VERSION "HNPBNNNYNNNNNNNNNNNNNNNNNNNNNNNNYNYYYYYYYY>4>%%%/4>'%**4YYY///"

NS_ :

BS_:

BU_: TPM TCM SCCM RF_HUB PTS ORC IC HaLF ETM ESM ESC EPS ECM Diagnost DTCM DASM CBC AFLS ADCM

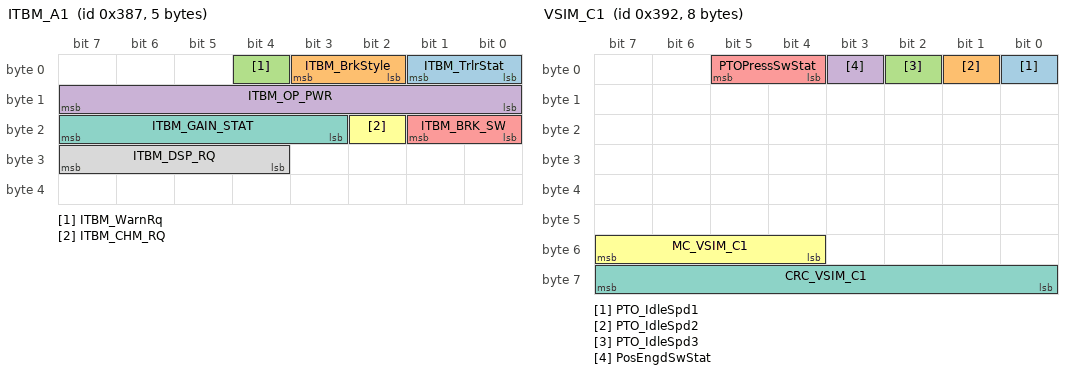
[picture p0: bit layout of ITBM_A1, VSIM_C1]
BO_ 903 ITBM_A1: 5 Vector__XXX
 SG_ ITBM_TrlrStat : 0|2@1+ (1,0) [0|0] ""  PTS,IC,CBC
 SG_ ITBM_BrkStyle : 2|2@1+ (1,0) [0|0] ""  IC,CBC
 SG_ ITBM_WarnRq : 4|1@1+ (1,0) [0|0] ""  IC
 SG_ ITBM_OP_PWR : 8|8@1+ (0.5,0) [0|100] "%"  IC
 SG_ ITBM_BRK_SW : 16|2@1+ (1,0) [0|0] ""  CBC
 SG_ ITBM_CHM_RQ : 18|1@1+ (1,0) [0|0] ""  IC
 SG_ ITBM_GAIN_STAT : 19|5@1+ (0.5,0) [0|10] ""  IC
 SG_ ITBM_DSP_RQ : 28|4@1+ (1,0) [0|0] ""  IC

BO_ 904 TCM_HSC: 8 ECM
 SG_ TCM_HSC : 7|64@0+ (1,0) [0|0] ""  Diagnost

BO_ 912 ECM_APPL5: 8 ECM
 SG_ ECM_APPL5 : 7|64@0+ (1,0) [0|0] ""  Diagnost

BO_ 914 VSIM_C1: 8 Vector__XXX
 SG_ PTO_IdleSpd1 : 0|1@1+ (1,0) [0|0] ""  ECM
 SG_ PTO_IdleSpd2 : 1|1@1+ (1,0) [0|0] ""  ECM
 SG_ PTO_IdleSpd3 : 2|1@1+ (1,0) [0|0] ""  ECM
 SG_ PosEngdSwStat : 3|1@1+ (1,0) [0|0] ""  ECM
 SG_ PTOPressSwStat : 4|2@1+ (1,0) [0|0] ""  ECM,CBC
 SG_ MC_VSIM_C1 : 52|4@1+ (1,0) [0|15] ""  ECM,CBC
 SG_ CRC_VSIM_C1 : 56|8@1+ (1,0) [0|0] ""  ECM,CBC

BO_ 916 VSIM_C2: 6 Vector__XXX
 SG_ STEREO_MD : 0|1@1+ (1,0) [0|0] ""  CBC
 SG_ SupHrnRq : 1|1@1+ (1,0) [0|0] ""  CBC
 SG_ PNC_ALM_MUTE : 2|1@1+ (1,0) [0|0] ""  CBC
 SG_ FtWigWagRq : 3|1@1+ (1,0) [0|0] ""  CBC
 SG_ RrWigWagRq : 4|1@1+ (1,0) [0|0] ""  CBC
 SG_ AudioMuteRq : 5|1@1+ (1,0) [0|0] ""  CBC
 SG_ PlowHL_Stat : 6|2@1+ (1,0) [0|0] ""  CBC
 SG_ SnowPlowPrsnt : 8|1@1+ (1,0) [0|0] ""  CBC
 SG_ VSIM_LBeamFlt : 9|1@1+ (1,0) [0|0] ""  CBC
 SG_ VSIM_HBeamFlt : 10|1@1+ (1,0) [0|0] ""  CBC
 SG_ VSIM_TS_Flt_RL : 11|1@1+ (1,0) [0|0] ""  CBC
 SG_ VSIM_TS_Flt_RR : 12|1@1+ (1,0) [0|0] ""  CBC
 SG_ VSIM_TS : 13|1@1+ (1,0) [0|0] ""  CBC
 SG_ DsblTurnLmpFlt : 14|1@1+ (1,0) [0|0] ""  CBC
 SG_ SprtRearLtg : 15|1@1+ (1,0) [0|0] ""  CBC
 SG_ VSIM_DualQual_Req : 21|1@1+ (1,0) [0|0] ""  CBC
 SG_ VSIM_DRL_Req : 22|1@1+ (1,0) [0|0] ""  CBC
 SG_ R_AC_Enable : 23|1@1+ (1,0) [0|0] ""  CBC

BO_ 920 TCM_HSD: 8 ECM
 SG_ TCM_HSD : 7|64@0+ (1,0) [0|0] ""  Diagnost

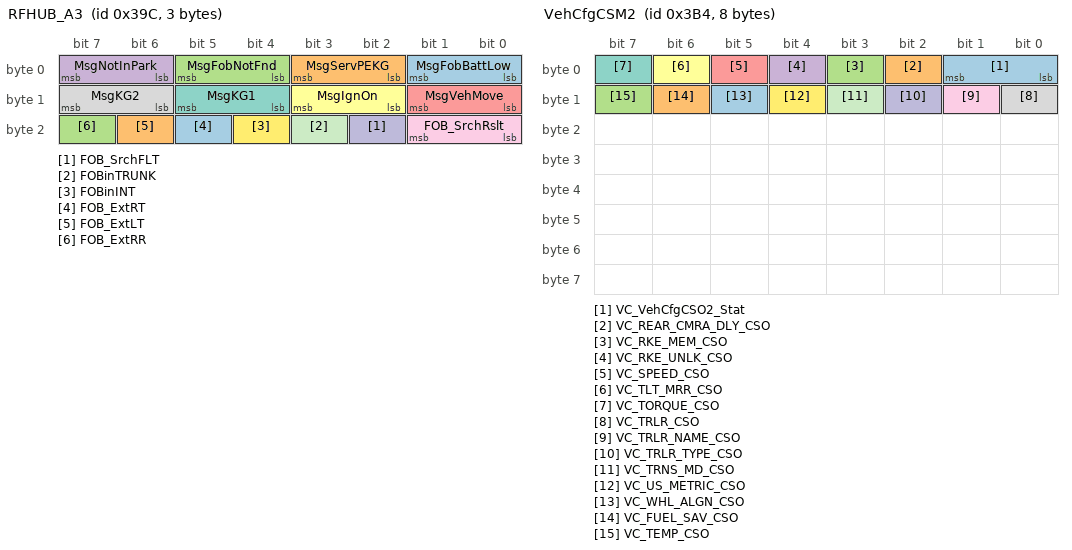
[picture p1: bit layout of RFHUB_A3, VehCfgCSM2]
BO_ 924 RFHUB_A3: 3 RF_HUB
 SG_ MsgFobBattLow : 0|2@1+ (1,0) [0|0] ""  IC
 SG_ MsgServPEKG : 2|2@1+ (1,0) [0|0] ""  IC
 SG_ MsgFobNotFnd : 4|2@1+ (1,0) [0|0] ""  IC
 SG_ MsgNotInPark : 6|2@1+ (1,0) [0|0] ""  IC
 SG_ MsgVehMove : 8|2@1+ (1,0) [0|0] ""  IC
 SG_ MsgIgnOn : 10|2@1+ (1,0) [0|0] ""  IC
 SG_ MsgKG1 : 12|2@1+ (1,0) [0|0] ""  IC
 SG_ MsgKG2 : 14|2@1+ (1,0) [0|0] ""  IC
 SG_ FOB_SrchRslt : 16|2@1+ (1,0) [0|0] ""  CBC
 SG_ FOB_SrchFLT : 18|1@1+ (1,0) [0|0] ""  CBC
 SG_ FOBinTRUNK : 19|1@1+ (1,0) [0|0] ""  CBC
 SG_ FOBinINT : 20|1@1+ (1,0) [0|0] ""  CBC
 SG_ FOB_ExtRT : 21|1@1+ (1,0) [0|0] ""  CBC
 SG_ FOB_ExtLT : 22|1@1+ (1,0) [0|0] ""  CBC
 SG_ FOB_ExtRR : 23|1@1+ (1,0) [0|0] ""  CBC

BO_ 928 ECM_APPL6: 8 ECM
 SG_ ECM_APPL6 : 7|64@0+ (1,0) [0|0] ""  Diagnost

BO_ 936 ECM_APPL7: 8 ECM
 SG_ ECM_APPL7 : 7|64@0+ (1,0) [0|0] ""  Diagnost

BO_ 937 CBC_CFG1: 8 CBC
 SG_ RKE_ONE_PRESS_ENBL : 0|1@1+ (1,0) [0|0] ""  IC
 SG_ SOUND_LK : 1|1@1+ (1,0) [0|0] ""  IC
 SG_ FLASH_LK : 2|1@1+ (1,0) [0|0] ""  IC
 SG_ HL_WPR : 3|1@1+ (1,0) [0|0] ""  IC
 SG_ AUTO_LK : 4|1@1+ (1,0) [0|0] ""  IC
 SG_ AUTO_UNLK : 5|1@1+ (1,0) [0|0] ""  IC
 SG_ DR_ALR : 6|1@1+ (1,0) [0|0] ""  IC
 SG_ CFG_AUTO_WPR : 7|1@1+ (1,0) [0|0] ""  IC
 SG_ ILL_APRCH_TIME : 8|8@1+ (1,0) [0|254] "sec"  IC
 SG_ HL_DLY_TIME : 16|8@1+ (1,0) [0|254] "sec"  IC
 SG_ ACC_DLY_TIME : 31|16@0+ (1,0) [0|65534] "sec"  IC
 SG_ DRL_ON : 40|1@1+ (1,0) [0|0] ""  IC
 SG_ ECM_Enbl : 41|1@1+ (1,0) [0|0] ""  IC
 SG_ RemLoHrnEnbl : 50|1@1+ (1,0) [0|0] ""  IC
 SG_ RemLoLgtEnbl : 51|1@1+ (1,0) [0|0] ""  IC
 SG_ SOUND_RS : 52|1@1+ (1,0) [0|0] ""  IC
 SG_ AUTO_RELK : 53|1@1+ (1,0) [0|0] ""  IC
 SG_ StaticGridResp : 54|1@1+ (1,0) [0|0] ""  IC
 SG_ DynamicGridResp : 55|1@1+ (1,0) [0|0] ""  IC
 SG_ SOUND_LK_1ST_2ND : 56|2@1+ (1,0) [0|0] ""  IC

BO_ 944 TCM_APPL2: 8 Diagnost
 SG_ TCM_APPL2 : 7|64@0+ (1,0) [0|0] ""  TCM,ECM

BO_ 945 TCM_APPL1: 8 ECM
 SG_ TCM_APPL1 : 7|64@0+ (1,0) [0|0] ""  Diagnost

BO_ 946 TCM_APPL3: 8 ECM
 SG_ TCM_APPL3 : 7|64@0+ (1,0) [0|0] ""  Diagnost

BO_ 947 VehCfgCSM1: 8 CBC
 SG_ VC_VehCfgCSO1_Stat : 0|2@1+ (1,0) [0|0] ""  IC,RF_HUB
 SG_ VC_PRK_AST_CSO : 2|2@1+ (1,0) [0|0] ""  IC,RF_HUB
 SG_ VC_PRK_AST_BRK_CSO : 4|1@1+ (1,0) [0|0] ""  IC,RF_HUB
 SG_ VC_PRK_FT_VOL_CSO : 5|1@1+ (1,0) [0|0] ""  IC,RF_HUB
 SG_ VC_PRK_RR_VOL_CSO : 6|1@1+ (1,0) [0|0] ""  IC,RF_HUB
 SG_ VC_EPS_CSO : 7|1@1+ (1,0) [0|0] ""  IC,RF_HUB
 SG_ VC_FCW_CSO : 8|2@1+ (1,0) [0|0] ""  IC,RF_HUB
 SG_ VC_FCW_BRK_CSO : 10|1@1+ (1,0) [0|0] ""  IC,RF_HUB
 SG_ VC_HRN_RMT_LK_CSO : 11|2@1+ (1,0) [0|0] ""  IC,RF_HUB
 SG_ VC_HRN_RMT_ST_CSO : 13|1@1+ (1,0) [0|0] ""  IC,RF_HUB
 SG_ VC_HRN_RMT_LWR_CSO : 14|1@1+ (1,0) [0|0] ""  IC,RF_HUB
 SG_ VC_CHMSL_LINE_CSO : 15|1@1+ (1,0) [0|0] ""  IC,RF_HUB
 SG_ VC_DCS_CSO : 16|2@1+ (1,0) [0|0] ""  IC,RF_HUB
 SG_ VC_AUX_SWS_CSO : 18|2@1+ (1,0) [0|0] ""  IC,RF_HUB
 SG_ VC_CMRA_GRDLNS_CSO : 20|2@1+ (1,0) [0|0] ""  IC,RF_HUB
 SG_ VC_ACC_DLY_CSO : 24|1@1+ (1,0) [0|0] ""  IC,RF_HUB
 SG_ VC_AFLS_CSO : 25|1@1+ (1,0) [0|0] ""  IC,RF_HUB
 SG_ VC_AMB_DMR_CSO : 26|1@1+ (1,0) [0|0] ""  IC,RF_HUB
 SG_ VC_ASCM_TJ_CSO : 27|1@1+ (1,0) [0|0] ""  IC,RF_HUB
 SG_ VC_ASCM_WRN_CSO : 28|1@1+ (1,0) [0|0] ""  IC,RF_HUB
 SG_ VC_AUTO_AERO_CSO : 29|1@1+ (1,0) [0|0] ""  IC,RF_HUB
 SG_ VC_AUTO_HB_CSO : 30|1@1+ (1,0) [0|0] ""  IC,RF_HUB
 SG_ VC_AUTO_PRK_CSO : 31|1@1+ (1,0) [0|0] ""  IC,RF_HUB
 SG_ VC_BLIND_SPOT_CSO : 32|1@1+ (1,0) [0|0] ""  IC,RF_HUB
 SG_ VC_CAPACITY_CSO : 33|1@1+ (1,0) [0|0] ""  IC,RF_HUB
 SG_ VC_CLK_DSP_CSO : 34|1@1+ (1,0) [0|0] ""  IC,RF_HUB
 SG_ VC_CMP_CAL_CSO : 35|1@1+ (1,0) [0|0] ""  IC,RF_HUB
 SG_ VC_CMP_VAR_CSO : 36|1@1+ (1,0) [0|0] ""  IC,RF_HUB
 SG_ VC_CONS_CSO : 37|1@1+ (1,0) [0|0] ""  IC,RF_HUB
 SG_ VC_DISTANCE_CSO : 38|1@1+ (1,0) [0|0] ""  IC,RF_HUB
 SG_ VC_DR_LK_CSO : 39|1@1+ (1,0) [0|0] ""  IC,RF_HUB
 SG_ VC_DR_UNLK_CSO : 40|1@1+ (1,0) [0|0] ""  IC,RF_HUB
 SG_ VC_DRL_CSO : 41|1@1+ (1,0) [0|0] ""  IC,RF_HUB
 SG_ VC_EASY_EXIT_CSO : 42|1@1+ (1,0) [0|0] ""  IC,RF_HUB
 SG_ VC_ENTRY_EXIT_CSO : 43|1@1+ (1,0) [0|0] ""  IC,RF_HUB
 SG_ VC_EPB_SERV_CSO : 44|1@1+ (1,0) [0|0] ""  IC,RF_HUB
 SG_ VC_FLSH_LMP_LK_CSO : 45|1@1+ (1,0) [0|0] ""  IC,RF_HUB
 SG_ VC_HL_DRP_CSO : 46|1@1+ (1,0) [0|0] ""  IC,RF_HUB
 SG_ VC_HL_OFF_DLY_CSO : 47|1@1+ (1,0) [0|0] ""  IC,RF_HUB
 SG_ VC_HL_WPR_CSO : 48|1@1+ (1,0) [0|0] ""  IC,RF_HUB
 SG_ VC_HSA_CSO : 49|1@1+ (1,0) [0|0] ""  IC,RF_HUB
 SG_ VC_ILL_APPRCH_CSO : 50|1@1+ (1,0) [0|0] ""  IC,RF_HUB
 SG_ VC_LDW_TRQ_CSO : 51|1@1+ (1,0) [0|0] ""  IC,RF_HUB
 SG_ VC_LDW_WRN_CSO : 52|1@1+ (1,0) [0|0] ""  IC,RF_HUB
 SG_ VC_LGHT_RMT_LWR_CSO : 53|1@1+ (1,0) [0|0] ""  IC,RF_HUB
 SG_ VC_NAV_TRN_CSO : 54|1@1+ (1,0) [0|0] ""  IC,RF_HUB
 SG_ VC_PE_CSO : 55|1@1+ (1,0) [0|0] ""  IC,RF_HUB
 SG_ VC_PER_SHFT_ENBL_CSO : 56|1@1+ (1,0) [0|0] ""  IC,RF_HUB
 SG_ VC_PER_SHFT_RPM_CSO : 57|1@1+ (1,0) [0|0] ""  IC,RF_HUB
 SG_ VC_PLG_CHM_CSO : 58|1@1+ (1,0) [0|0] ""  IC,RF_HUB
 SG_ VC_POWER_CSO : 59|1@1+ (1,0) [0|0] ""  IC,RF_HUB
 SG_ VC_PRESSURE_CSO : 60|1@1+ (1,0) [0|0] ""  IC,RF_HUB
 SG_ VC_PTO_CSO : 61|1@1+ (1,0) [0|0] ""  IC,RF_HUB
 SG_ VC_RAIN_WPR_CSO : 62|1@1+ (1,0) [0|0] ""  IC,RF_HUB
 SG_ VC_REAR_CMRA_CSO : 63|1@1+ (1,0) [0|0] ""  IC,RF_HUB

BO_ 948 VehCfgCSM2: 8 CBC
 SG_ VC_VehCfgCSO2_Stat : 0|2@1+ (1,0) [0|0] ""  IC,RF_HUB
 SG_ VC_REAR_CMRA_DLY_CSO : 2|1@1+ (1,0) [0|0] ""  IC,RF_HUB
 SG_ VC_RKE_MEM_CSO : 3|1@1+ (1,0) [0|0] ""  IC,RF_HUB
 SG_ VC_RKE_UNLK_CSO : 4|1@1+ (1,0) [0|0] ""  IC,RF_HUB
 SG_ VC_SPEED_CSO : 5|1@1+ (1,0) [0|0] ""  IC,RF_HUB
 SG_ VC_TLT_MRR_CSO : 6|1@1+ (1,0) [0|0] ""  IC,RF_HUB
 SG_ VC_TORQUE_CSO : 7|1@1+ (1,0) [0|0] ""  IC,RF_HUB
 SG_ VC_TRLR_CSO : 8|1@1+ (1,0) [0|0] ""  IC,RF_HUB
 SG_ VC_TRLR_NAME_CSO : 9|1@1+ (1,0) [0|0] ""  IC,RF_HUB
 SG_ VC_TRLR_TYPE_CSO : 10|1@1+ (1,0) [0|0] ""  IC,RF_HUB
 SG_ VC_TRNS_MD_CSO : 11|1@1+ (1,0) [0|0] ""  IC,RF_HUB
 SG_ VC_US_METRIC_CSO : 12|1@1+ (1,0) [0|0] ""  IC,RF_HUB
 SG_ VC_WHL_ALGN_CSO : 13|1@1+ (1,0) [0|0] ""  IC,RF_HUB
 SG_ VC_FUEL_SAV_CSO : 14|1@1+ (1,0) [0|0] ""  RF_HUB
 SG_ VC_TEMP_CSO : 15|1@1+ (1,0) [0|0] ""  RF_HUB

BO_ 949 VehCfgCSM1_BU: 8 RF_HUB
 SG_ VC_BU_VehCfgCSO1_Stat : 0|2@1+ (1,0) [0|0] ""  CBC
 SG_ VC_BU_PRK_AST_CSO : 2|2@1+ (1,0) [0|0] ""  CBC
 SG_ VC_BU_PRK_AST_BRK_CSO : 4|1@1+ (1,0) [0|0] ""  CBC
 SG_ VC_BU_PRK_FT_VOL_CSO : 5|1@1+ (1,0) [0|0] ""  CBC
 SG_ VC_BU_PRK_RR_VOL_CSO : 6|1@1+ (1,0) [0|0] ""  CBC
 SG_ VC_BU_EPS_CSO : 7|1@1+ (1,0) [0|0] ""  CBC
 SG_ VC_BU_FCW_CSO : 8|2@1+ (1,0) [0|0] ""  CBC
 SG_ VC_BU_FCW_BRK_CSO : 10|1@1+ (1,0) [0|0] ""  CBC
 SG_ VC_BU_HRN_RMT_LK_CSO : 11|2@1+ (1,0) [0|0] ""  CBC
 SG_ VC_BU_HRN_RMT_ST_CSO : 13|1@1+ (1,0) [0|0] ""  CBC
 SG_ VC_BU_HRN_RMT_LWR_CSO : 14|1@1+ (1,0) [0|0] ""  CBC
 SG_ VC_BU_CHMSL_LINE_CSO : 15|1@1+ (1,0) [0|0] ""  CBC
 SG_ VC_BU_DCS_CSO : 16|2@1+ (1,0) [0|0] ""  CBC
 SG_ VC_BU_AUX_SWS_CSO : 18|2@1+ (1,0) [0|0] ""  CBC
 SG_ VC_BU_CMRA_GRDLNS_CSO : 20|2@1+ (1,0) [0|0] ""  CBC
 SG_ VC_BU_ACC_DLY_CSO : 24|1@1+ (1,0) [0|0] ""  CBC
 SG_ VC_BU_AFLS_CSO : 25|1@1+ (1,0) [0|0] ""  CBC
 SG_ VC_BU_AMB_DMR_CSO : 26|1@1+ (1,0) [0|0] ""  CBC
 SG_ VC_BU_ASCM_TJ_CSO : 27|1@1+ (1,0) [0|0] ""  CBC
 SG_ VC_BU_ASCM_WRN_CSO : 28|1@1+ (1,0) [0|0] ""  CBC
 SG_ VC_BU_AUTO_AERO_CSO : 29|1@1+ (1,0) [0|0] ""  CBC
 SG_ VC_BU_AUTO_HB_CSO : 30|1@1+ (1,0) [0|0] ""  CBC
 SG_ VC_BU_AUTO_PRK_CSO : 31|1@1+ (1,0) [0|0] ""  CBC
 SG_ VC_BU_BLIND_SPOT_CSO : 32|1@1+ (1,0) [0|0] ""  CBC
 SG_ VC_BU_CAPACITY_CSO : 33|1@1+ (1,0) [0|0] ""  CBC
 SG_ VC_BU_CLK_DSP_CSO : 34|1@1+ (1,0) [0|0] ""  CBC
 SG_ VC_BU_CMP_CAL_CSO : 35|1@1+ (1,0) [0|0] ""  CBC
 SG_ VC_BU_CMP_VAR_CSO : 36|1@1+ (1,0) [0|0] ""  CBC
 SG_ VC_BU_CONS_CSO : 37|1@1+ (1,0) [0|0] ""  CBC
 SG_ VC_BU_DISTANCE_CSO : 38|1@1+ (1,0) [0|0] ""  CBC
 SG_ VC_BU_DR_LK_CSO : 39|1@1+ (1,0) [0|0] ""  CBC
 SG_ VC_BU_DR_UNLK_CSO : 40|1@1+ (1,0) [0|0] ""  CBC
 SG_ VC_BU_DRL_CSO : 41|1@1+ (1,0) [0|0] ""  CBC
 SG_ VC_BU_EASY_EXIT_CSO : 42|1@1+ (1,0) [0|0] ""  CBC
 SG_ VC_BU_ENTRY_EXIT_CSO : 43|1@1+ (1,0) [0|0] ""  CBC
 SG_ VC_BU_EPB_SERV_CSO : 44|1@1+ (1,0) [0|0] ""  CBC
 SG_ VC_BU_FLSH_LMP_LK_CSO : 45|1@1+ (1,0) [0|0] ""  CBC
 SG_ VC_BU_HL_DRP_CSO : 46|1@1+ (1,0) [0|0] ""  CBC
 SG_ VC_BU_HL_OFF_DLY_CSO : 47|1@1+ (1,0) [0|0] ""  CBC
 SG_ VC_BU_HL_WPR_CSO : 48|1@1+ (1,0) [0|0] ""  CBC
 SG_ VC_BU_HSA_CSO : 49|1@1+ (1,0) [0|0] ""  CBC
 SG_ VC_BU_ILL_APPRCH_CSO : 50|1@1+ (1,0) [0|0] ""  CBC
 SG_ VC_BU_LDW_TRQ_CSO : 51|1@1+ (1,0) [0|0] ""  CBC
 SG_ VC_BU_LDW_WRN_CSO : 52|1@1+ (1,0) [0|0] ""  CBC
 SG_ VC_BU_LGHT_RMT_LWR_CSO : 53|1@1+ (1,0) [0|0] ""  CBC
 SG_ VC_BU_NAV_TRN_CSO : 54|1@1+ (1,0) [0|0] ""  CBC
 SG_ VC_BU_PE_CSO : 55|1@1+ (1,0) [0|0] ""  CBC
 SG_ VC_BU_PER_SHFT_ENBL_CSO : 56|1@1+ (1,0) [0|0] ""  CBC
 SG_ VC_BU_PER_SHFT_RPM_CSO : 57|1@1+ (1,0) [0|0] ""  CBC
 SG_ VC_BU_PLG_CHM_CSO : 58|1@1+ (1,0) [0|0] ""  CBC
 SG_ VC_BU_POWER_CSO : 59|1@1+ (1,0) [0|0] ""  CBC
 SG_ VC_BU_PRESSURE_CSO : 60|1@1+ (1,0) [0|0] ""  CBC
 SG_ VC_BU_PTO_CSO : 61|1@1+ (1,0) [0|0] ""  CBC
 SG_ VC_BU_RAIN_WPR_CSO : 62|1@1+ (1,0) [0|0] ""  CBC
 SG_ VC_BU_REAR_CMRA_CSO : 63|1@1+ (1,0) [0|0] ""  CBC

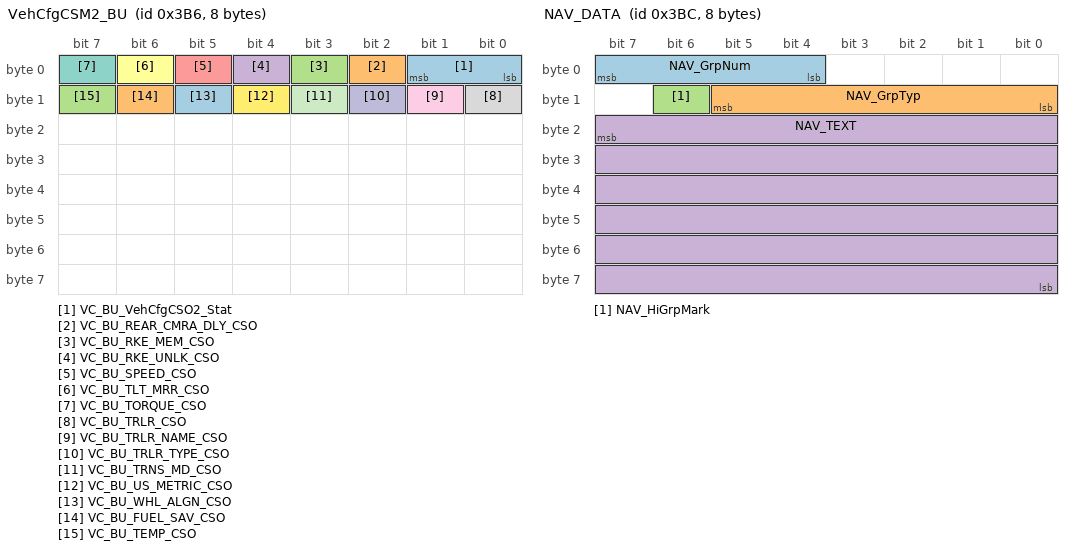
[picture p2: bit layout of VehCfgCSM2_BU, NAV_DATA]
BO_ 950 VehCfgCSM2_BU: 8 RF_HUB
 SG_ VC_BU_VehCfgCSO2_Stat : 0|2@1+ (1,0) [0|0] ""  CBC
 SG_ VC_BU_REAR_CMRA_DLY_CSO : 2|1@1+ (1,0) [0|0] ""  CBC
 SG_ VC_BU_RKE_MEM_CSO : 3|1@1+ (1,0) [0|0] ""  CBC
 SG_ VC_BU_RKE_UNLK_CSO : 4|1@1+ (1,0) [0|0] ""  CBC
 SG_ VC_BU_SPEED_CSO : 5|1@1+ (1,0) [0|0] ""  CBC
 SG_ VC_BU_TLT_MRR_CSO : 6|1@1+ (1,0) [0|0] ""  CBC
 SG_ VC_BU_TORQUE_CSO : 7|1@1+ (1,0) [0|0] ""  CBC
 SG_ VC_BU_TRLR_CSO : 8|1@1+ (1,0) [0|0] ""  CBC
 SG_ VC_BU_TRLR_NAME_CSO : 9|1@1+ (1,0) [0|0] ""  CBC
 SG_ VC_BU_TRLR_TYPE_CSO : 10|1@1+ (1,0) [0|0] ""  CBC
 SG_ VC_BU_TRNS_MD_CSO : 11|1@1+ (1,0) [0|0] ""  CBC
 SG_ VC_BU_US_METRIC_CSO : 12|1@1+ (1,0) [0|0] ""  CBC
 SG_ VC_BU_WHL_ALGN_CSO : 13|1@1+ (1,0) [0|0] ""  CBC
 SG_ VC_BU_FUEL_SAV_CSO : 14|1@1+ (1,0) [0|0] ""  CBC
 SG_ VC_BU_TEMP_CSO : 15|1@1+ (1,0) [0|0] ""  CBC

BO_ 956 NAV_DATA: 8 CBC
 SG_ NAV_GrpNum : 4|4@1+ (1,1) [1|16] "Group"  IC
 SG_ NAV_GrpTyp : 8|6@1+ (1,0) [1|40] "Text"  IC
 SG_ NAV_HiGrpMark : 14|1@1+ (1,0) [0|0] ""  IC
 SG_ NAV_TEXT : 23|48@0+ (1,0) [0|0] ""  IC

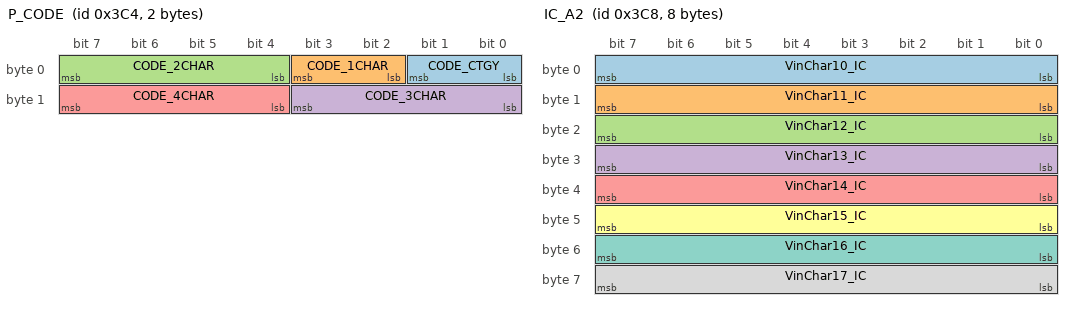
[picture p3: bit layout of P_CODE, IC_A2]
BO_ 964 P_CODE: 2 ECM
 SG_ CODE_CTGY : 0|2@1+ (1,0) [0|0] ""  IC
 SG_ CODE_1CHAR : 2|2@1+ (1,0) [0|3] "decimal"  IC
 SG_ CODE_2CHAR : 4|4@1+ (1,0) [0|15] ""  IC
 SG_ CODE_3CHAR : 8|4@1+ (1,0) [0|15] ""  IC
 SG_ CODE_4CHAR : 12|4@1+ (1,0) [0|15] ""  IC

BO_ 968 IC_A2: 8 IC
 SG_ VinChar10_IC : 0|8@1+ (1,0) [0|0] ""  RF_HUB
 SG_ VinChar11_IC : 8|8@1+ (1,0) [0|0] ""  RF_HUB
 SG_ VinChar12_IC : 16|8@1+ (1,0) [0|0] ""  RF_HUB
 SG_ VinChar13_IC : 24|8@1+ (1,0) [0|0] ""  RF_HUB
 SG_ VinChar14_IC : 32|8@1+ (1,0) [0|0] ""  RF_HUB
 SG_ VinChar15_IC : 40|8@1+ (1,0) [0|0] ""  RF_HUB
 SG_ VinChar16_IC : 48|8@1+ (1,0) [0|0] ""  RF_HUB
 SG_ VinChar17_IC : 56|8@1+ (1,0) [0|0] ""  RF_HUB

BO_ 969 AMB_TEMP_DISP: 4 CBC
 SG_ AMB_TEMP_AVG_F : 0|8@1+ (1,-40) [-40|210] "°F"  IC
 SG_ AMB_TEMP_AVG_C : 8|8@1+ (1,-40) [-40|210] "°C"  IC

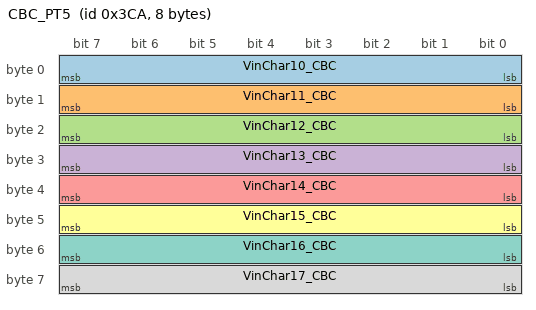
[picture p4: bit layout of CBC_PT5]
BO_ 970 CBC_PT5: 8 CBC
 SG_ VinChar10_CBC : 0|8@1+ (1,0) [0|0] ""  RF_HUB
 SG_ VinChar11_CBC : 8|8@1+ (1,0) [0|0] ""  RF_HUB
 SG_ VinChar12_CBC : 16|8@1+ (1,0) [0|0] ""  RF_HUB
 SG_ VinChar13_CBC : 24|8@1+ (1,0) [0|0] ""  RF_HUB
 SG_ VinChar14_CBC : 32|8@1+ (1,0) [0|0] ""  RF_HUB
 SG_ VinChar15_CBC : 40|8@1+ (1,0) [0|0] ""  RF_HUB
 SG_ VinChar16_CBC : 48|8@1+ (1,0) [0|0] ""  RF_HUB
 SG_ VinChar17_CBC : 56|8@1+ (1,0) [0|0] ""  RF_HUB

CM_ SG_ 903 ITBM_TrlrStat "Trailer connection status";
CM_ SG_ 903 ITBM_BrkStyle "Trailer brake style";
CM_ SG_ 903 ITBM_WarnRq "ITBM warning request";
CM_ SG_ 903 ITBM_OP_PWR "ITBM brake output value (PWM)";
CM_ SG_ 903 ITBM_BRK_SW "Brake light activation";
CM_ SG_ 903 ITBM_CHM_RQ "ITBM fault chime request";
CM_ SG_ 903 ITBM_GAIN_STAT "Set gain";
CM_ SG_ 903 ITBM_DSP_RQ "ITBM display request";
CM_ SG_ 904 TCM_HSC "Manual control at test bench";
CM_ SG_ 912 ECM_APPL5 "CCP 10ms DAQ  (from ENGINE to external tool)";
CM_ SG_ 914 PTO_IdleSpd1 "Power takeoff idle speed 1 selected";
CM_ SG_ 914 PTO_IdleSpd2 "Power takeoff idle speed 2 selected";
CM_ SG_ 914 PTO_IdleSpd3 "Power takeoff idle speed 3 selected";
CM_ SG_ 914 PosEngdSwStat "Positive engagement switch status; On = [1]";
CM_ SG_ 914 PTOPressSwStat "PTO Pressure Switch Status";
CM_ SG_ 914 MC_VSIM_C1 "Message counter";
CM_ SG_ 914 CRC_VSIM_C1 "CRC-checksum byte 1 to 7 according to SAE J1850";
CM_ SG_ 916 STEREO_MD "No HFM mode RQ=[0], HFM mode RQ = [1]";
CM_ SG_ 916 SupHrnRq "Suppress horn request";
CM_ SG_ 916 PNC_ALM_MUTE "Panic alarm mute";
CM_ SG_ 916 FtWigWagRq "Front wig wag request";
CM_ SG_ 916 RrWigWagRq "Rear wig wag request";
CM_ SG_ 916 AudioMuteRq "Audio mute request; Audio mute = [1]";
CM_ SG_ 916 PlowHL_Stat "Snowplow headlamp status";
CM_ SG_ 916 SnowPlowPrsnt "Snowplow is present; true = [1]";
CM_ SG_ 916 VSIM_LBeamFlt "VSIM low beam headlamp faulted";
CM_ SG_ 916 VSIM_HBeamFlt "VSIM high beam headlamp faulted";
CM_ SG_ 916 VSIM_TS_Flt_RL "VSIM turn signal fault - left rear";
CM_ SG_ 916 VSIM_TS_Flt_RR "VSIM turn signal fault - right rear";
CM_ SG_ 916 VSIM_TS "VSIM driven turn signals";
CM_ SG_ 916 DsblTurnLmpFlt "Disable rear turn lamp fault";
CM_ SG_ 916 SprtRearLtg "Separate rear lighting";
CM_ SG_ 916 VSIM_DualQual_Req "Quad headlamp control is required; Quad = [1]";
CM_ SG_ 916 VSIM_DRL_Req "Front DRL control is required; DRL = [1]";
CM_ SG_ 916 R_AC_Enable "Rear A/C enable request; On = [1]";
CM_ SG_ 920 TCM_HSD "Manual control at test bench";
CM_ SG_ 924 MsgFobBattLow "Indicates battery low on FOBIK last used for RKE purposes";
CM_ SG_ 924 MsgServPEKG "Service the Keyless System.";
CM_ SG_ 924 MsgFobNotFnd "FOB Not Detected.";
CM_ SG_ 924 MsgNotInPark "Vehicle was not in Park.";
CM_ SG_ 924 MsgVehMove "Vehicle Moving";
CM_ SG_ 924 MsgIgnOn "Vehicle Ignition was left on";
CM_ SG_ 924 MsgKG1 "Place holder for future.";
CM_ SG_ 924 MsgKG2 "Place holder for future.";
CM_ SG_ 924 FOB_SrchRslt "FOB search result";
CM_ SG_ 924 FOB_SrchFLT "FOB search fault";
CM_ SG_ 924 FOBinTRUNK "FOB is in zone trunk";
CM_ SG_ 924 FOBinINT "FOB is in zone interior";
CM_ SG_ 924 FOB_ExtRT "FOB is in zone exterior right";
CM_ SG_ 924 FOB_ExtLT "FOB is in zone exterior left";
CM_ SG_ 924 FOB_ExtRR "FOB is in zone exterior rear";
CM_ SG_ 928 ECM_APPL6 "CCP 80ms DAQ  (from ENGINE to external tool)";
CM_ SG_ 936 ECM_APPL7 "Application";
CM_ SG_ 937 RKE_ONE_PRESS_ENBL "Unlck all doors on 1st press; yes = [0], no = [1]";
CM_ SG_ 937 SOUND_LK "Sound horn on lock; no = [0], yes = [1]";
CM_ SG_ 937 FLASH_LK "Flash lamps with lock; no = [0], yes = [1]";
CM_ SG_ 937 HL_WPR "Headlamp on with wiper; no = [0], yes =[1]";
CM_ SG_ 937 AUTO_LK "Auto lock; enabled = [1]";
CM_ SG_ 937 AUTO_UNLK "Auto unlock; enabled = [1]";
CM_ SG_ 937 DR_ALR "Door alert; enabled = [1]";
CM_ SG_ 937 CFG_AUTO_WPR "Auto wiper configuration; no = [0], yes =[1]";
CM_ SG_ 937 ILL_APRCH_TIME "Illuminated approach time";
CM_ SG_ 937 HL_DLY_TIME "Headlamp delay time";
CM_ SG_ 937 ACC_DLY_TIME "Power accessory delay time";
CM_ SG_ 937 DRL_ON "Daytime running lamps on; enabled = [1]";
CM_ SG_ 937 ECM_Enbl "EC Mirror; enabled = [1]";
CM_ SG_ 937 RemLoHrnEnbl "Remote lowering horn enabled";
CM_ SG_ 937 RemLoLgtEnbl "Remote lowering lights enabled";
CM_ SG_ 937 SOUND_RS "Sound horn on Remote Start ; no = [0], yes = [1]";
CM_ SG_ 937 AUTO_RELK "Auto relock; enabled = [1]";
CM_ SG_ 937 StaticGridResp "Static Gridlines ON = [1]";
CM_ SG_ 937 DynamicGridResp "Dynamic Gridlines ON = [1]";
CM_ SG_ 937 SOUND_LK_1ST_2ND "Sound horn on lock status";
CM_ SG_ 944 TCM_APPL2 "CCP to transmission";
CM_ SG_ 945 TCM_APPL1 "CCP from transmission";
CM_ SG_ 946 TCM_APPL3 "CCP from transmission";
CM_ SG_ 947 VC_VehCfgCSO1_Stat "Configuration message CSO1 status";
CM_ SG_ 947 VC_PRK_AST_CSO "Park assist customer settings menu";
CM_ SG_ 947 VC_PRK_AST_BRK_CSO "Park assist brake customer settings menu; Present = [1]";
CM_ SG_ 947 VC_PRK_FT_VOL_CSO "Park assist front volume customer settings menu; Present = [1]";
CM_ SG_ 947 VC_PRK_RR_VOL_CSO "Park assist rear volume customer settings menu; Present = [1]";
CM_ SG_ 947 VC_EPS_CSO "Electric power steering customer settings menu; Present = [1]";
CM_ SG_ 947 VC_FCW_CSO "Forward collision warning customer settings menu";
CM_ SG_ 947 VC_FCW_BRK_CSO "Forward collision mitigation braking customer settings menu; Present = [1]";
CM_ SG_ 947 VC_HRN_RMT_LK_CSO "Sound horn with remote lock customer settings menu";
CM_ SG_ 947 VC_HRN_RMT_ST_CSO "Sound horn with remote start customer settings menu; Present = [1]";
CM_ SG_ 947 VC_HRN_RMT_LWR_CSO "Sound horn with remote lower customer settings menu; Present = [1]";
CM_ SG_ 947 VC_CHMSL_LINE_CSO "CHMSL line menu; Present = [1]";
CM_ SG_ 947 VC_DCS_CSO "Auto on driver comfort customer settings menu";
CM_ SG_ 947 VC_AUX_SWS_CSO "Auxiliary switches customer settings menu";
CM_ SG_ 947 VC_CMRA_GRDLNS_CSO "Rear view camera gridlines customer settings menu";
CM_ SG_ 947 VC_ACC_DLY_CSO "Power accessory delay customer settings menu; Present = [1]";
CM_ SG_ 947 VC_AFLS_CSO "Adaptive front light system customer settings menu; Present = [1]";
CM_ SG_ 947 VC_AMB_DMR_CSO "Ambient dimmer customer settings menu; Present = [1]";
CM_ SG_ 947 VC_ASCM_TJ_CSO "Tire jack mode customer settings menu; Present = [1]";
CM_ SG_ 947 VC_ASCM_WRN_CSO "Air suspension warning customer settings menu; Present = [1]";
CM_ SG_ 947 VC_AUTO_AERO_CSO "Automatic aero mode customer settings menu; Present = [1]";
CM_ SG_ 947 VC_AUTO_HB_CSO "Auto high beam customer settings menu; Present = [1]";
CM_ SG_ 947 VC_AUTO_PRK_CSO "Auto park customer settings menu; Present = [1]";
CM_ SG_ 947 VC_BLIND_SPOT_CSO "Blind spot alert customer settings menu; Present = [1]";
CM_ SG_ 947 VC_CAPACITY_CSO "Capacity unit customer settings menu; Present = [1]";
CM_ SG_ 947 VC_CLK_DSP_CSO "Clock display customer settings menu; Present = [1]";
CM_ SG_ 947 VC_CMP_CAL_CSO "Compass calibration customer settings menu; Present = [1]";
CM_ SG_ 947 VC_CMP_VAR_CSO "Compass variance customer settings menu; Present = [1]";
CM_ SG_ 947 VC_CONS_CSO "Consumption unit customer settings menu; Present = [1]";
CM_ SG_ 947 VC_DISTANCE_CSO "Distance unit customer settings menu; Present = [1]";
CM_ SG_ 947 VC_DR_LK_CSO "Auto door lock customer settings menu; Present = [1]";
CM_ SG_ 947 VC_DR_UNLK_CSO "Auto door unlock customer settings menu; Present = [1]";
CM_ SG_ 947 VC_DRL_CSO "Daytime running lights customer settings menu; Present = [1]";
CM_ SG_ 947 VC_EASY_EXIT_CSO "Easy exit seat customer settings menu; Present = [1]";
CM_ SG_ 947 VC_ENTRY_EXIT_CSO "Auto entry exit mode customer settings menu; Present = [1]";
CM_ SG_ 947 VC_EPB_SERV_CSO "EPB service mode customer settings menu; Present = [1]";
CM_ SG_ 947 VC_FLSH_LMP_LK_CSO "Flash lamps with lock customer settings menu; Present = [1]";
CM_ SG_ 947 VC_HL_DRP_CSO "Headlamp drop customer settings menu; Present = [1]";
CM_ SG_ 947 VC_HL_OFF_DLY_CSO "Headlamp off delay customer settings menu; Present = [1]";
CM_ SG_ 947 VC_HL_WPR_CSO "Headlamps on with wiper customer settings menu; Present = [1]";
CM_ SG_ 947 VC_HSA_CSO "Hill start assist customer settings menu; Present = [1]";
CM_ SG_ 947 VC_ILL_APPRCH_CSO "Illuminated approach customer settings menu; Present = [1]";
CM_ SG_ 947 VC_LDW_TRQ_CSO "Lane departure torque customer settings menu; Present = [1]";
CM_ SG_ 947 VC_LDW_WRN_CSO "Lane departure warning customer settings menu; Present = [1]";
CM_ SG_ 947 VC_LGHT_RMT_LWR_CSO "Flash lights with remote lower customer settings menu; Present = [1]";
CM_ SG_ 947 VC_NAV_TRN_CSO "Nav turn by turn customer settings menu; Present = [1]";
CM_ SG_ 947 VC_PE_CSO "Passive entry customer settings menu; Present = [1]";
CM_ SG_ 947 VC_PER_SHFT_ENBL_CSO "Performance shift enable customer settings menu; Present = [1]";
CM_ SG_ 947 VC_PER_SHFT_RPM_CSO "Performance shift rpm customer settings menu; Present = [1]";
CM_ SG_ 947 VC_PLG_CHM_CSO "Power liftgate chime customer settings menu; Present = [1]";
CM_ SG_ 947 VC_POWER_CSO "Power unit customer settings menu; Present = [1]";
CM_ SG_ 947 VC_PRESSURE_CSO "Pressure unit customer settings menu; Present = [1]";
CM_ SG_ 947 VC_PTO_CSO "Power take off customer settings menu; Present = [1]";
CM_ SG_ 947 VC_RAIN_WPR_CSO "Rain sensitive wipers customer settings menu; Present = [1]";
CM_ SG_ 947 VC_REAR_CMRA_CSO "Rear camera customer settings menu; Present = [1]";
CM_ SG_ 948 VC_VehCfgCSO2_Stat "Configuration message CSO2 status";
CM_ SG_ 948 VC_REAR_CMRA_DLY_CSO "Rear view camera delay customer settings menu; Present = [1]";
CM_ SG_ 948 VC_RKE_MEM_CSO "RKE linked to memory customer settings menu; Present = [1]";
CM_ SG_ 948 VC_RKE_UNLK_CSO "RKE unlock customer settings menu; Present = [1]";
CM_ SG_ 948 VC_SPEED_CSO "Speed unit customer settings menu; Present = [1]";
CM_ SG_ 948 VC_TLT_MRR_CSO "Tilt mirror in reverse customer settings menu; Present = [1]";
CM_ SG_ 948 VC_TORQUE_CSO "Torque unit customer settings menu; Present = [1]";
CM_ SG_ 948 VC_TRLR_CSO "Trailer selected customer settings menu; Present = [1]";
CM_ SG_ 948 VC_TRLR_NAME_CSO "Trailer name customer settings menu; Present = [1]";
CM_ SG_ 948 VC_TRLR_TYPE_CSO "Trailer type customer settings menu; Present = [1]";
CM_ SG_ 948 VC_TRNS_MD_CSO "Transport mode customer settings menu; Present = [1]";
CM_ SG_ 948 VC_US_METRIC_CSO "US metric customer settings menu; Present = [1]";
CM_ SG_ 948 VC_WHL_ALGN_CSO "Wheel alignment customer settings menu; Present = [1]";
CM_ SG_ 948 VC_FUEL_SAV_CSO "Waiting for description from J. Kuhn; Present = [1]";
CM_ SG_ 948 VC_TEMP_CSO "Waiting for description from J. Kuhn; Present = [1]";
CM_ SG_ 949 VC_BU_VehCfgCSO1_Stat "Backup for Configuration message CSO1 status";
CM_ SG_ 949 VC_BU_PRK_AST_CSO "Backup for park assist customer settings menu";
CM_ SG_ 949 VC_BU_PRK_AST_BRK_CSO "Backup for park assist brake customer settings menu";
CM_ SG_ 949 VC_BU_PRK_FT_VOL_CSO "Backup for park assist front volume customer settings menu";
CM_ SG_ 949 VC_BU_PRK_RR_VOL_CSO "Backup for park assist rear volume customer settings menu";
CM_ SG_ 949 VC_BU_EPS_CSO "Backup for electric power steering customer settings menu";
CM_ SG_ 949 VC_BU_FCW_CSO "Backup for Forward collision warning customer settings menu";
CM_ SG_ 949 VC_BU_FCW_BRK_CSO "Backup for Forward collision mitigation braking customer settings menu";
CM_ SG_ 949 VC_BU_HRN_RMT_LK_CSO "Backup for Sound horn with remote lock customer settings menu";
CM_ SG_ 949 VC_BU_HRN_RMT_ST_CSO "Backup for Sound horn with remote start customer settings menu";
CM_ SG_ 949 VC_BU_HRN_RMT_LWR_CSO "Backup for Sound horn with remote lower customer settings menu";
CM_ SG_ 949 VC_BU_CHMSL_LINE_CSO "Backup for CHMSL line customer settings menu";
CM_ SG_ 949 VC_BU_DCS_CSO "Backup for Auto on driver comfort customer settings menu";
CM_ SG_ 949 VC_BU_AUX_SWS_CSO "Backup for Auxiliary switches customer settings menu";
CM_ SG_ 949 VC_BU_CMRA_GRDLNS_CSO "Backup for Rear view camera gridlines customer settings menu";
CM_ SG_ 949 VC_BU_ACC_DLY_CSO "Backup for Power accessory delay customer settings menu";
CM_ SG_ 949 VC_BU_AFLS_CSO "Backup for Adaptive front light system customer settings menu";
CM_ SG_ 949 VC_BU_AMB_DMR_CSO "Backup for Ambient dimmer customer settings menu";
CM_ SG_ 949 VC_BU_ASCM_TJ_CSO "Backup for Tire jack mode customer settings menu";
CM_ SG_ 949 VC_BU_ASCM_WRN_CSO "Backup for Air suspension warning customer settings menu";
CM_ SG_ 949 VC_BU_AUTO_AERO_CSO "Backup for Automatic aero mode customer settings menu";
CM_ SG_ 949 VC_BU_AUTO_HB_CSO "Backup for Auto high beam customer settings menu";
CM_ SG_ 949 VC_BU_AUTO_PRK_CSO "Backup for Auto park customer settings menu";
CM_ SG_ 949 VC_BU_BLIND_SPOT_CSO "Backup for Blind spot alert customer settings menu";
CM_ SG_ 949 VC_BU_CAPACITY_CSO "Backup for Capacity unit customer settings menu";
CM_ SG_ 949 VC_BU_CLK_DSP_CSO "Backup for Clock display customer settings menu";
CM_ SG_ 949 VC_BU_CMP_CAL_CSO "Backup for Compass calibration customer settings menu";
CM_ SG_ 949 VC_BU_CMP_VAR_CSO "Backup for Compass variance customer settings menu";
CM_ SG_ 949 VC_BU_CONS_CSO "Backup for Consumption unit customer settings menu";
CM_ SG_ 949 VC_BU_DISTANCE_CSO "Backup for Distance unit customer settings menu";
CM_ SG_ 949 VC_BU_DR_LK_CSO "Backup for Auto door lock customer settings menu";
CM_ SG_ 949 VC_BU_DR_UNLK_CSO "Backup for Auto door unlock customer settings menu";
CM_ SG_ 949 VC_BU_DRL_CSO "Backup for Daytime running lights customer settings menu";
CM_ SG_ 949 VC_BU_EASY_EXIT_CSO "Backup for Easy exit seat customer settings menu";
CM_ SG_ 949 VC_BU_ENTRY_EXIT_CSO "Backup for Auto entry exit mode customer settings menu";
CM_ SG_ 949 VC_BU_EPB_SERV_CSO "Backup for EPB service mode customer settings menu";
CM_ SG_ 949 VC_BU_FLSH_LMP_LK_CSO "Backup for Flash lamps with lock customer settings menu";
CM_ SG_ 949 VC_BU_HL_DRP_CSO "Backup for Headlamp drop customer settings menu";
CM_ SG_ 949 VC_BU_HL_OFF_DLY_CSO "Backup for Headlamp off delay customer settings menu";
CM_ SG_ 949 VC_BU_HL_WPR_CSO "Backup for Headlamps on with wiper customer settings menu";
CM_ SG_ 949 VC_BU_HSA_CSO "Backup for Hill start assist customer settings menu";
CM_ SG_ 949 VC_BU_ILL_APPRCH_CSO "Backup for Illuminated approach customer settings menu";
CM_ SG_ 949 VC_BU_LDW_TRQ_CSO "Backup for Lane departure torque customer settings menu";
CM_ SG_ 949 VC_BU_LDW_WRN_CSO "Backup for Lane departure warning customer settings menu";
CM_ SG_ 949 VC_BU_LGHT_RMT_LWR_CSO "Backup for Flash lights with remote lower customer settings menu";
CM_ SG_ 949 VC_BU_NAV_TRN_CSO "Backup for Nav turn by turn customer settings menu";
CM_ SG_ 949 VC_BU_PE_CSO "Backup for Passive entry customer settings menu";
CM_ SG_ 949 VC_BU_PER_SHFT_ENBL_CSO "Backup for Performance shift enable customer settings menu";
CM_ SG_ 949 VC_BU_PER_SHFT_RPM_CSO "Backup for Performance shift rpm customer settings menu";
CM_ SG_ 949 VC_BU_PLG_CHM_CSO "Backup for Power liftgate chime customer settings menu";
CM_ SG_ 949 VC_BU_POWER_CSO "Backup for Power unit customer settings menu";
CM_ SG_ 949 VC_BU_PRESSURE_CSO "Backup for Pressure unit customer settings menu";
CM_ SG_ 949 VC_BU_PTO_CSO "Backup for Power take off customer settings menu";
CM_ SG_ 949 VC_BU_RAIN_WPR_CSO "Backup for Rain sensitive wipers customer settings menu";
CM_ SG_ 949 VC_BU_REAR_CMRA_CSO "Backup for Rear camera customer settings menu";
CM_ SG_ 950 VC_BU_VehCfgCSO2_Stat "Backup for Configuration message CSO2 status";
CM_ SG_ 950 VC_BU_REAR_CMRA_DLY_CSO "Backup for Rear view camera delay customer settings menu";
CM_ SG_ 950 VC_BU_RKE_MEM_CSO "Backup for RKE linked to memory customer settings menu";
CM_ SG_ 950 VC_BU_RKE_UNLK_CSO "Backup for RKE unlock customer settings menu";
CM_ SG_ 950 VC_BU_SPEED_CSO "Backup for Speed unit customer settings menu";
CM_ SG_ 950 VC_BU_TLT_MRR_CSO "Backup for Tilt mirror in reverse customer settings menu";
CM_ SG_ 950 VC_BU_TORQUE_CSO "Backup for Torque unit customer settings menu";
CM_ SG_ 950 VC_BU_TRLR_CSO "Backup for Trailer selected customer settings menu";
CM_ SG_ 950 VC_BU_TRLR_NAME_CSO "Backup for Trailer name customer settings menu";
CM_ SG_ 950 VC_BU_TRLR_TYPE_CSO "Backup for Trailer type customer settings menu";
CM_ SG_ 950 VC_BU_TRNS_MD_CSO "Backup for Transport mode customer settings menu";
CM_ SG_ 950 VC_BU_US_METRIC_CSO "Backup for US metric customer settings menu";
CM_ SG_ 950 VC_BU_WHL_ALGN_CSO "Backup for Wheel alignment customer settings menu";
CM_ SG_ 950 VC_BU_FUEL_SAV_CSO "Backup for waiting for description from J. Kuhn; Present = [1]";
CM_ SG_ 950 VC_BU_TEMP_CSO "Backup for waiting for description from J. Kuhn; Present = [1]";
CM_ SG_ 956 NAV_GrpNum "NAV group number";
CM_ SG_ 956 NAV_GrpTyp "NAV group type";
CM_ SG_ 956 NAV_HiGrpMark "NAV high group mark";
CM_ SG_ 956 NAV_TEXT "NAV data field";
CM_ SG_ 964 CODE_CTGY "Flash code category";
CM_ SG_ 964 CODE_1CHAR "Flash code 1st character";
CM_ SG_ 964 CODE_2CHAR "Flash code 2nd character";
CM_ SG_ 964 CODE_3CHAR "Flash code 3rd character";
CM_ SG_ 964 CODE_4CHAR "Flash code 4th character";
CM_ SG_ 968 VinChar10_IC "VIN ascii character 10 from the IC";
CM_ SG_ 968 VinChar11_IC "VIN ascii character 11 from the IC";
CM_ SG_ 968 VinChar12_IC "VIN ascii character 12 from the IC";
CM_ SG_ 968 VinChar13_IC "VIN ascii character 13 from the IC";
CM_ SG_ 968 VinChar14_IC "VIN ascii character 14 from the IC";
CM_ SG_ 968 VinChar15_IC "VIN ascii character 15 from the IC";
CM_ SG_ 968 VinChar16_IC "VIN ascii character 16 from the IC";
CM_ SG_ 968 VinChar17_IC "VIN ascii character 17 from the IC";
CM_ SG_ 969 AMB_TEMP_AVG_F "Ambient temperature average - in degrees Fahrenheit";
CM_ SG_ 969 AMB_TEMP_AVG_C "Ambient temperature average - in degrees Celsius";
CM_ SG_ 970 VinChar10_CBC "VIN ascii character 10 from the CBC";
CM_ SG_ 970 VinChar11_CBC "VIN ascii character 11 from the CBC";
CM_ SG_ 970 VinChar12_CBC "VIN ascii character 12 from the CBC";
CM_ SG_ 970 VinChar13_CBC "VIN ascii character 13 from the CBC";
CM_ SG_ 970 VinChar14_CBC "VIN ascii character 14 from the CBC";
CM_ SG_ 970 VinChar15_CBC "VIN ascii character 15 from the CBC";
CM_ SG_ 970 VinChar16_CBC "VIN ascii character 16 from the CBC";
CM_ SG_ 970 VinChar17_CBC "VIN ascii character 17 from the CBC";
BA_DEF_ SG_  "GenSigTimeout_ADCM" INT 0 65535;
BA_DEF_ SG_  "GenSigTimeout_AFLS" INT 0 65535;
BA_DEF_ SG_  "GenSigTimeout_CBC" INT 0 65535;
BA_DEF_ SG_  "GenSigTimeout_DTCM" INT 0 65535;
BA_DEF_ SG_  "GenSigTimeout_ECM" INT 0 65535;
BA_DEF_ SG_  "GenSigTimeout_EPS" INT 0 65535;
BA_DEF_ SG_  "GenSigTimeout_ESC" INT 0 65535;
BA_DEF_ SG_  "GenSigTimeout_ESM" INT 0 65535;
BA_DEF_ SG_  "GenSigTimeout_ETM" INT 0 65535;
BA_DEF_ SG_  "GenSigTimeout_HaLF" INT 0 65535;
BA_DEF_ SG_  "GenSigTimeout_IC" INT 0 65535;
BA_DEF_ SG_  "GenSigTimeout_ORC" INT 0 65535;
BA_DEF_ SG_  "GenSigTimeout_PTS" INT 0 65535;
BA_DEF_ SG_  "GenSigTimeout_RF_HUB" INT 0 65535;
BA_DEF_ SG_  "GenSigTimeout_SCCM" INT 0 65535;
BA_DEF_ SG_  "GenSigTimeout_TPM" INT 0 65535;
BA_DEF_ BO_  "GenMsgStartValue" STRING ;
BA_DEF_ SG_  "GenSigSNA" STRING ;
BA_DEF_ SG_  "FlexKomIsMotorola" ENUM  "nein","ja";
BA_DEF_ SG_  "FlexKomSigLaenge" INT 0 64;
BA_DEF_ SG_  "FlexKomSigStartPos" INT 0 63;
BA_DEF_ SG_  "FlexKomComment" STRING ;
BA_DEF_ SG_  "FlexKomSigName" STRING ;
BA_DEF_ SG_  "FlexKomSID" INT 0 2147483647;
BA_DEF_ SG_  "GenSigStartValue" HEX 0 4294967295;
BA_DEF_ SG_  "FlexKomSigStartValue" STRING ;
BA_DEF_ SG_  "GenSigCycleTimeActive" INT 0 65535;
BA_DEF_ SG_  "GenSigCycleTime" INT 0 65535;
BA_DEF_ SG_  "GenSigSendType" ENUM  "cyclicX","spontanX","cyclicIfActiveX","spontanWithDelay","cyclicAndSpontanX","cyclicAndSpontanWithDelay","spontanWithRepitition","cyclicIfActiveAndSpontanWD","cyclicIfActiveFast","cyclicWithRepeatOnDemand","none";
BA_DEF_ BO_  "GenMsgNrOfRepetitions" INT 0 65535;
BA_DEF_ BO_  "GenMsgDelayTime" INT 0 65535;
BA_DEF_ BO_  "GenMsgStartDelayTime" INT 0 65535;
BA_DEF_ BO_  "GenMsgCycleTimeActive" INT 0 65535;
BA_DEF_ BO_  "GenMsgCycleTime" INT 0 65535;
BA_DEF_ BO_  "GenMsgSendType" ENUM  "cyclicX","spontanX","cyclicIfActiveX","spontanWithDelay","cyclicAndSpontanX","cyclicAndSpontanWithDelay","spontanWithRepitition","cyclicIfActiveAndSpontanWD","cyclicIfActiveFast","cyclicWithRepeatOnDemand","none";
BA_DEF_ BO_  "DiagResponse" ENUM  "nein","ja";
BA_DEF_ BO_  "DiagRequest" ENUM  "nein","ja";
BA_DEF_ BO_  "DiagState" ENUM  "nein","ja";
BA_DEF_ BO_  "App-Botschaft" ENUM  "nein","ja";
BA_DEF_ BO_  "NWM-Botschaft" ENUM  "nein","ja";
BA_DEF_DEF_  "GenSigTimeout_ADCM" 0;
BA_DEF_DEF_  "GenSigTimeout_AFLS" 0;
BA_DEF_DEF_  "GenSigTimeout_CBC" 0;
BA_DEF_DEF_  "GenSigTimeout_DTCM" 0;
BA_DEF_DEF_  "GenSigTimeout_ECM" 0;
BA_DEF_DEF_  "GenSigTimeout_EPS" 0;
BA_DEF_DEF_  "GenSigTimeout_ESC" 0;
BA_DEF_DEF_  "GenSigTimeout_ESM" 0;
BA_DEF_DEF_  "GenSigTimeout_ETM" 0;
BA_DEF_DEF_  "GenSigTimeout_HaLF" 0;
BA_DEF_DEF_  "GenSigTimeout_IC" 0;
BA_DEF_DEF_  "GenSigTimeout_ORC" 0;
BA_DEF_DEF_  "GenSigTimeout_PTS" 0;
BA_DEF_DEF_  "GenSigTimeout_RF_HUB" 0;
BA_DEF_DEF_  "GenSigTimeout_SCCM" 0;
BA_DEF_DEF_  "GenSigTimeout_TPM" 0;
BA_DEF_DEF_  "GenMsgStartValue" "";
BA_DEF_DEF_  "GenSigSNA" "";
BA_DEF_DEF_  "FlexKomIsMotorola" "nein";
BA_DEF_DEF_  "FlexKomSigLaenge" 0;
BA_DEF_DEF_  "FlexKomSigStartPos" 0;
BA_DEF_DEF_  "FlexKomComment" "";
BA_DEF_DEF_  "FlexKomSigName" "";
BA_DEF_DEF_  "FlexKomSID" 0;
BA_DEF_DEF_  "GenSigStartValue" 0;
BA_DEF_DEF_  "FlexKomSigStartValue" "";
BA_DEF_DEF_  "GenSigCycleTimeActive" 0;
BA_DEF_DEF_  "GenSigCycleTime" 0;
BA_DEF_DEF_  "GenSigSendType" "cyclicX";
BA_DEF_DEF_  "GenMsgNrOfRepetitions" 0;
BA_DEF_DEF_  "GenMsgDelayTime" 0;
BA_DEF_DEF_  "GenMsgStartDelayTime" 0;
BA_DEF_DEF_  "GenMsgCycleTimeActive" 0;
BA_DEF_DEF_  "GenMsgCycleTime" 0;
BA_DEF_DEF_  "GenMsgSendType" "cyclicX";
BA_DEF_DEF_  "DiagResponse" "nein";
BA_DEF_DEF_  "DiagRequest" "nein";
BA_DEF_DEF_  "DiagState" "nein";
BA_DEF_DEF_  "App-Botschaft" "nein";
BA_DEF_DEF_  "NWM-Botschaft" "nein";
BA_ "GenMsgSendType" BO_ 903 5;
BA_ "GenMsgCycleTime" BO_ 903 500;
BA_ "GenMsgDelayTime" BO_ 903 20;
BA_ "GenMsgNrOfRepetitions" BO_ 903 2;
BA_ "GenMsgStartValue" BO_ 903 "000003F000h";
BA_ "GenMsgSendType" BO_ 904 1;
BA_ "GenMsgDelayTime" BO_ 904 20;
BA_ "GenMsgNrOfRepetitions" BO_ 904 2;
BA_ "GenMsgStartValue" BO_ 904 "0000000000000000h";
BA_ "GenMsgSendType" BO_ 912 1;
BA_ "GenMsgDelayTime" BO_ 912 20;
BA_ "GenMsgNrOfRepetitions" BO_ 912 2;
BA_ "GenMsgStartValue" BO_ 912 "0000000000000000h";
BA_ "GenMsgCycleTime" BO_ 914 250;
BA_ "GenMsgDelayTime" BO_ 914 20;
BA_ "GenMsgNrOfRepetitions" BO_ 914 2;
BA_ "GenMsgStartValue" BO_ 914 "00000000000000FFh";
BA_ "GenMsgSendType" BO_ 916 5;
BA_ "GenMsgCycleTime" BO_ 916 1000;
BA_ "GenMsgDelayTime" BO_ 916 20;
BA_ "GenMsgNrOfRepetitions" BO_ 916 2;
BA_ "GenMsgStartValue" BO_ 916 "000000000000h";
BA_ "GenMsgSendType" BO_ 920 1;
BA_ "GenMsgDelayTime" BO_ 920 20;
BA_ "GenMsgNrOfRepetitions" BO_ 920 2;
BA_ "GenMsgStartValue" BO_ 920 "0000000000000000h";
BA_ "GenMsgSendType" BO_ 924 5;
BA_ "GenMsgCycleTime" BO_ 924 1000;
BA_ "GenMsgDelayTime" BO_ 924 20;
BA_ "GenMsgNrOfRepetitions" BO_ 924 2;
BA_ "GenMsgStartValue" BO_ 924 "000000h";
BA_ "GenMsgSendType" BO_ 928 1;
BA_ "GenMsgDelayTime" BO_ 928 20;
BA_ "GenMsgNrOfRepetitions" BO_ 928 2;
BA_ "GenMsgStartValue" BO_ 928 "0000000000000000h";
BA_ "GenMsgSendType" BO_ 936 1;
BA_ "GenMsgDelayTime" BO_ 936 20;
BA_ "GenMsgNrOfRepetitions" BO_ 936 2;
BA_ "GenMsgStartValue" BO_ 936 "0000000000000000h";
BA_ "GenMsgSendType" BO_ 937 5;
BA_ "GenMsgCycleTime" BO_ 937 1000;
BA_ "GenMsgDelayTime" BO_ 937 20;
BA_ "GenMsgNrOfRepetitions" BO_ 937 2;
BA_ "GenMsgStartValue" BO_ 937 "00FFFFFFFF00C003h";
BA_ "GenMsgStartDelayTime" BO_ 937 10;
BA_ "GenMsgSendType" BO_ 944 1;
BA_ "GenMsgDelayTime" BO_ 944 20;
BA_ "GenMsgNrOfRepetitions" BO_ 944 2;
BA_ "GenMsgStartValue" BO_ 944 "0000000000000000h";
BA_ "GenMsgSendType" BO_ 945 1;
BA_ "GenMsgDelayTime" BO_ 945 20;
BA_ "GenMsgNrOfRepetitions" BO_ 945 2;
BA_ "GenMsgStartValue" BO_ 945 "0000000000000000h";
BA_ "GenMsgSendType" BO_ 946 1;
BA_ "GenMsgDelayTime" BO_ 946 20;
BA_ "GenMsgNrOfRepetitions" BO_ 946 2;
BA_ "GenMsgStartValue" BO_ 946 "0000000000000000h";
BA_ "GenMsgSendType" BO_ 947 5;
BA_ "GenMsgCycleTime" BO_ 947 2000;
BA_ "GenMsgDelayTime" BO_ 947 20;
BA_ "GenMsgNrOfRepetitions" BO_ 947 2;
BA_ "GenMsgStartValue" BO_ 947 "0300000000000000h";
BA_ "GenMsgStartDelayTime" BO_ 947 60;
BA_ "GenMsgSendType" BO_ 948 5;
BA_ "GenMsgCycleTime" BO_ 948 2000;
BA_ "GenMsgDelayTime" BO_ 948 20;
BA_ "GenMsgNrOfRepetitions" BO_ 948 2;
BA_ "GenMsgStartValue" BO_ 948 "0300000000000000h";
BA_ "GenMsgStartDelayTime" BO_ 948 70;
BA_ "GenMsgSendType" BO_ 949 1;
BA_ "GenMsgDelayTime" BO_ 949 20;
BA_ "GenMsgNrOfRepetitions" BO_ 949 2;
BA_ "GenMsgStartValue" BO_ 949 "0300000000000000h";
BA_ "GenMsgSendType" BO_ 950 1;
BA_ "GenMsgDelayTime" BO_ 950 20;
BA_ "GenMsgNrOfRepetitions" BO_ 950 2;
BA_ "GenMsgStartValue" BO_ 950 "0300000000000000h";
BA_ "GenMsgSendType" BO_ 956 5;
BA_ "GenMsgCycleTime" BO_ 956 1000;
BA_ "GenMsgDelayTime" BO_ 956 20;
BA_ "GenMsgNrOfRepetitions" BO_ 956 2;
BA_ "GenMsgStartValue" BO_ 956 "0000000000000000h";
BA_ "GenMsgSendType" BO_ 964 1;
BA_ "GenMsgDelayTime" BO_ 964 20;
BA_ "GenMsgNrOfRepetitions" BO_ 964 2;
BA_ "GenMsgStartValue" BO_ 964 "0000h";
BA_ "GenMsgSendType" BO_ 968 9;
BA_ "GenMsgCycleTime" BO_ 968 100;
BA_ "GenMsgDelayTime" BO_ 968 100;
BA_ "GenMsgNrOfRepetitions" BO_ 968 3;
BA_ "GenMsgStartValue" BO_ 968 "0000000000000000h";
BA_ "GenMsgCycleTime" BO_ 969 1000;
BA_ "GenMsgDelayTime" BO_ 969 20;
BA_ "GenMsgNrOfRepetitions" BO_ 969 2;
BA_ "GenMsgStartValue" BO_ 969 "FFFF0000h";
BA_ "GenMsgSendType" BO_ 970 9;
BA_ "GenMsgCycleTime" BO_ 970 100;
BA_ "GenMsgDelayTime" BO_ 970 100;
BA_ "GenMsgNrOfRepetitions" BO_ 970 3;
BA_ "GenMsgStartValue" BO_ 970 "0000000000000000h";
BA_ "GenSigSendType" SG_ 903 ITBM_TrlrStat 5;
BA_ "GenSigCycleTime" SG_ 903 ITBM_TrlrStat 500;
BA_ "FlexKomSigStartValue" SG_ 903 ITBM_TrlrStat "00h";
BA_ "GenSigTimeout_CBC" SG_ 903 ITBM_TrlrStat 5250;
BA_ "GenSigTimeout_IC" SG_ 903 ITBM_TrlrStat 5250;
BA_ "GenSigTimeout_PTS" SG_ 903 ITBM_TrlrStat 5250;
BA_ "FlexKomSID" SG_ 903 ITBM_TrlrStat 1592;
BA_ "FlexKomSigStartPos" SG_ 903 ITBM_TrlrStat 7;
BA_ "FlexKomSigLaenge" SG_ 903 ITBM_TrlrStat 8;
BA_ "FlexKomSigName" SG_ 903 ITBM_TrlrStat "ITBM_TrlrPkt";
BA_ "FlexKomComment" SG_ 903 ITBM_TrlrStat "ITBM trailer status packet";
BA_ "FlexKomIsMotorola" SG_ 903 ITBM_TrlrStat 1;
BA_ "GenSigSNA" SG_ 903 ITBM_TrlrStat "3h";
BA_ "GenSigSendType" SG_ 903 ITBM_BrkStyle 5;
BA_ "GenSigCycleTime" SG_ 903 ITBM_BrkStyle 500;
BA_ "FlexKomSigStartValue" SG_ 903 ITBM_BrkStyle "00h";
BA_ "GenSigTimeout_CBC" SG_ 903 ITBM_BrkStyle 5250;
BA_ "GenSigTimeout_IC" SG_ 903 ITBM_BrkStyle 5250;
BA_ "FlexKomSID" SG_ 903 ITBM_BrkStyle 1592;
BA_ "FlexKomSigStartPos" SG_ 903 ITBM_BrkStyle 7;
BA_ "FlexKomSigLaenge" SG_ 903 ITBM_BrkStyle 8;
BA_ "FlexKomSigName" SG_ 903 ITBM_BrkStyle "ITBM_TrlrPkt";
BA_ "FlexKomComment" SG_ 903 ITBM_BrkStyle "ITBM trailer status packet";
BA_ "FlexKomIsMotorola" SG_ 903 ITBM_BrkStyle 1;
BA_ "GenSigSNA" SG_ 903 ITBM_BrkStyle "0h";
BA_ "GenSigSendType" SG_ 903 ITBM_WarnRq 5;
BA_ "GenSigCycleTime" SG_ 903 ITBM_WarnRq 500;
BA_ "FlexKomSigStartValue" SG_ 903 ITBM_WarnRq "00h";
BA_ "GenSigTimeout_IC" SG_ 903 ITBM_WarnRq 5250;
BA_ "FlexKomSID" SG_ 903 ITBM_WarnRq 1592;
BA_ "FlexKomSigStartPos" SG_ 903 ITBM_WarnRq 7;
BA_ "FlexKomSigLaenge" SG_ 903 ITBM_WarnRq 8;
BA_ "FlexKomSigName" SG_ 903 ITBM_WarnRq "ITBM_TrlrPkt";
BA_ "FlexKomComment" SG_ 903 ITBM_WarnRq "ITBM trailer status packet";
BA_ "FlexKomIsMotorola" SG_ 903 ITBM_WarnRq 1;
BA_ "GenSigSNA" SG_ 903 ITBM_WarnRq "0h";
BA_ "GenSigSendType" SG_ 903 ITBM_OP_PWR 5;
BA_ "GenSigCycleTime" SG_ 903 ITBM_OP_PWR 500;
BA_ "FlexKomSigStartValue" SG_ 903 ITBM_OP_PWR "00h";
BA_ "GenSigTimeout_IC" SG_ 903 ITBM_OP_PWR 5250;
BA_ "FlexKomSID" SG_ 903 ITBM_OP_PWR 1737;
BA_ "FlexKomSigStartPos" SG_ 903 ITBM_OP_PWR 15;
BA_ "FlexKomSigLaenge" SG_ 903 ITBM_OP_PWR 8;
BA_ "FlexKomSigName" SG_ 903 ITBM_OP_PWR "ITBM_OP_PWR";
BA_ "FlexKomComment" SG_ 903 ITBM_OP_PWR "ITBM brake output value (PWM)";
BA_ "FlexKomIsMotorola" SG_ 903 ITBM_OP_PWR 1;
BA_ "GenSigSNA" SG_ 903 ITBM_OP_PWR "FFh";
BA_ "GenSigSendType" SG_ 903 ITBM_BRK_SW 5;
BA_ "GenSigCycleTime" SG_ 903 ITBM_BRK_SW 500;
BA_ "FlexKomSigStartValue" SG_ 903 ITBM_BRK_SW "03h";
BA_ "GenSigStartValue" SG_ 903 ITBM_BRK_SW 3;
BA_ "GenSigTimeout_CBC" SG_ 903 ITBM_BRK_SW 5250;
BA_ "FlexKomSID" SG_ 903 ITBM_BRK_SW 1735;
BA_ "FlexKomSigStartPos" SG_ 903 ITBM_BRK_SW 17;
BA_ "FlexKomSigLaenge" SG_ 903 ITBM_BRK_SW 2;
BA_ "FlexKomSigName" SG_ 903 ITBM_BRK_SW "ITBM_BRK_SW";
BA_ "FlexKomComment" SG_ 903 ITBM_BRK_SW "Brake light activation";
BA_ "FlexKomIsMotorola" SG_ 903 ITBM_BRK_SW 1;
BA_ "GenSigSNA" SG_ 903 ITBM_BRK_SW "3h";
BA_ "GenSigSendType" SG_ 903 ITBM_CHM_RQ 5;
BA_ "GenSigCycleTime" SG_ 903 ITBM_CHM_RQ 500;
BA_ "FlexKomSigStartValue" SG_ 903 ITBM_CHM_RQ "00h";
BA_ "GenSigTimeout_IC" SG_ 903 ITBM_CHM_RQ 5250;
BA_ "FlexKomSID" SG_ 903 ITBM_CHM_RQ 1739;
BA_ "FlexKomSigStartPos" SG_ 903 ITBM_CHM_RQ 18;
BA_ "FlexKomSigLaenge" SG_ 903 ITBM_CHM_RQ 1;
BA_ "FlexKomSigName" SG_ 903 ITBM_CHM_RQ "ITBM_CHM_RQ";
BA_ "FlexKomComment" SG_ 903 ITBM_CHM_RQ "ITBM fault chime request";
BA_ "FlexKomIsMotorola" SG_ 903 ITBM_CHM_RQ 1;
BA_ "GenSigSNA" SG_ 903 ITBM_CHM_RQ "0h";
BA_ "GenSigSendType" SG_ 903 ITBM_GAIN_STAT 5;
BA_ "GenSigCycleTime" SG_ 903 ITBM_GAIN_STAT 500;
BA_ "FlexKomSigStartValue" SG_ 903 ITBM_GAIN_STAT "00h";
BA_ "GenSigTimeout_IC" SG_ 903 ITBM_GAIN_STAT 5250;
BA_ "FlexKomSID" SG_ 903 ITBM_GAIN_STAT 1738;
BA_ "FlexKomSigStartPos" SG_ 903 ITBM_GAIN_STAT 23;
BA_ "FlexKomSigLaenge" SG_ 903 ITBM_GAIN_STAT 5;
BA_ "FlexKomSigName" SG_ 903 ITBM_GAIN_STAT "ITBM_GAIN_STAT";
BA_ "FlexKomComment" SG_ 903 ITBM_GAIN_STAT "Set gain";
BA_ "FlexKomIsMotorola" SG_ 903 ITBM_GAIN_STAT 1;
BA_ "GenSigSNA" SG_ 903 ITBM_GAIN_STAT "1Fh";
BA_ "GenSigSendType" SG_ 903 ITBM_DSP_RQ 5;
BA_ "GenSigCycleTime" SG_ 903 ITBM_DSP_RQ 500;
BA_ "FlexKomSigStartValue" SG_ 903 ITBM_DSP_RQ "0Fh";
BA_ "GenSigStartValue" SG_ 903 ITBM_DSP_RQ 15;
BA_ "GenSigTimeout_IC" SG_ 903 ITBM_DSP_RQ 5250;
BA_ "FlexKomSID" SG_ 903 ITBM_DSP_RQ 1736;
BA_ "FlexKomSigStartPos" SG_ 903 ITBM_DSP_RQ 31;
BA_ "FlexKomSigLaenge" SG_ 903 ITBM_DSP_RQ 4;
BA_ "FlexKomSigName" SG_ 903 ITBM_DSP_RQ "ITBM_DSP_RQ";
BA_ "FlexKomComment" SG_ 903 ITBM_DSP_RQ "ITBM display request";
BA_ "FlexKomIsMotorola" SG_ 903 ITBM_DSP_RQ 1;
BA_ "GenSigSNA" SG_ 903 ITBM_DSP_RQ "Fh";
BA_ "GenSigSendType" SG_ 904 TCM_HSC 1;
BA_ "FlexKomSigStartValue" SG_ 904 TCM_HSC "0000000000000000h";
BA_ "FlexKomSID" SG_ 904 TCM_HSC 801;
BA_ "FlexKomSigStartPos" SG_ 904 TCM_HSC 7;
BA_ "FlexKomSigLaenge" SG_ 904 TCM_HSC 64;
BA_ "FlexKomSigName" SG_ 904 TCM_HSC "TCM_HSC";
BA_ "FlexKomComment" SG_ 904 TCM_HSC "Manual control at test bench";
BA_ "FlexKomIsMotorola" SG_ 904 TCM_HSC 1;
BA_ "GenSigSNA" SG_ 904 TCM_HSC "0h";
BA_ "GenSigSendType" SG_ 912 ECM_APPL5 1;
BA_ "FlexKomSigStartValue" SG_ 912 ECM_APPL5 "0000000000000000h";
BA_ "FlexKomSID" SG_ 912 ECM_APPL5 783;
BA_ "FlexKomSigStartPos" SG_ 912 ECM_APPL5 7;
BA_ "FlexKomSigLaenge" SG_ 912 ECM_APPL5 64;
BA_ "FlexKomSigName" SG_ 912 ECM_APPL5 "ECM_APPL5";
BA_ "FlexKomComment" SG_ 912 ECM_APPL5 "CCP 10ms DAQ  (from ENGINE to external tool)";
BA_ "FlexKomIsMotorola" SG_ 912 ECM_APPL5 1;
BA_ "GenSigSNA" SG_ 912 ECM_APPL5 "0h";
BA_ "GenSigCycleTime" SG_ 914 PTO_IdleSpd1 250;
BA_ "FlexKomSigStartValue" SG_ 914 PTO_IdleSpd1 "00000000000000FFh";
BA_ "FlexKomSID" SG_ 914 PTO_IdleSpd1 1799;
BA_ "FlexKomSigStartPos" SG_ 914 PTO_IdleSpd1 7;
BA_ "FlexKomSigLaenge" SG_ 914 PTO_IdleSpd1 64;
BA_ "FlexKomSigName" SG_ 914 PTO_IdleSpd1 "VSIM_PTO_Pkt";
BA_ "FlexKomComment" SG_ 914 PTO_IdleSpd1 "Power takeoff packet";
BA_ "FlexKomIsMotorola" SG_ 914 PTO_IdleSpd1 1;
BA_ "GenSigSNA" SG_ 914 PTO_IdleSpd1 "0h";
BA_ "GenSigCycleTime" SG_ 914 PTO_IdleSpd2 250;
BA_ "FlexKomSigStartValue" SG_ 914 PTO_IdleSpd2 "00000000000000FFh";
BA_ "FlexKomSID" SG_ 914 PTO_IdleSpd2 1799;
BA_ "FlexKomSigStartPos" SG_ 914 PTO_IdleSpd2 7;
BA_ "FlexKomSigLaenge" SG_ 914 PTO_IdleSpd2 64;
BA_ "FlexKomSigName" SG_ 914 PTO_IdleSpd2 "VSIM_PTO_Pkt";
BA_ "FlexKomComment" SG_ 914 PTO_IdleSpd2 "Power takeoff packet";
BA_ "FlexKomIsMotorola" SG_ 914 PTO_IdleSpd2 1;
BA_ "GenSigSNA" SG_ 914 PTO_IdleSpd2 "0h";
BA_ "GenSigCycleTime" SG_ 914 PTO_IdleSpd3 250;
BA_ "FlexKomSigStartValue" SG_ 914 PTO_IdleSpd3 "00000000000000FFh";
BA_ "FlexKomSID" SG_ 914 PTO_IdleSpd3 1799;
BA_ "FlexKomSigStartPos" SG_ 914 PTO_IdleSpd3 7;
BA_ "FlexKomSigLaenge" SG_ 914 PTO_IdleSpd3 64;
BA_ "FlexKomSigName" SG_ 914 PTO_IdleSpd3 "VSIM_PTO_Pkt";
BA_ "FlexKomComment" SG_ 914 PTO_IdleSpd3 "Power takeoff packet";
BA_ "FlexKomIsMotorola" SG_ 914 PTO_IdleSpd3 1;
BA_ "GenSigSNA" SG_ 914 PTO_IdleSpd3 "0h";
BA_ "GenSigCycleTime" SG_ 914 PosEngdSwStat 250;
BA_ "FlexKomSigStartValue" SG_ 914 PosEngdSwStat "00000000000000FFh";
BA_ "FlexKomSID" SG_ 914 PosEngdSwStat 1799;
BA_ "FlexKomSigStartPos" SG_ 914 PosEngdSwStat 7;
BA_ "FlexKomSigLaenge" SG_ 914 PosEngdSwStat 64;
BA_ "FlexKomSigName" SG_ 914 PosEngdSwStat "VSIM_PTO_Pkt";
BA_ "FlexKomComment" SG_ 914 PosEngdSwStat "Power takeoff packet";
BA_ "FlexKomIsMotorola" SG_ 914 PosEngdSwStat 1;
BA_ "GenSigSNA" SG_ 914 PosEngdSwStat "0h";
BA_ "GenSigCycleTime" SG_ 914 PTOPressSwStat 250;
BA_ "FlexKomSigStartValue" SG_ 914 PTOPressSwStat "00000000000000FFh";
BA_ "GenSigTimeout_CBC" SG_ 914 PTOPressSwStat 2625;
BA_ "FlexKomSID" SG_ 914 PTOPressSwStat 1799;
BA_ "FlexKomSigStartPos" SG_ 914 PTOPressSwStat 7;
BA_ "FlexKomSigLaenge" SG_ 914 PTOPressSwStat 64;
BA_ "FlexKomSigName" SG_ 914 PTOPressSwStat "VSIM_PTO_Pkt";
BA_ "FlexKomComment" SG_ 914 PTOPressSwStat "Power takeoff packet";
BA_ "FlexKomIsMotorola" SG_ 914 PTOPressSwStat 1;
BA_ "GenSigSNA" SG_ 914 PTOPressSwStat "3h";
BA_ "GenSigCycleTime" SG_ 914 MC_VSIM_C1 250;
BA_ "FlexKomSigStartValue" SG_ 914 MC_VSIM_C1 "00000000000000FFh";
BA_ "GenSigTimeout_CBC" SG_ 914 MC_VSIM_C1 2625;
BA_ "FlexKomSID" SG_ 914 MC_VSIM_C1 1799;
BA_ "FlexKomSigStartPos" SG_ 914 MC_VSIM_C1 7;
BA_ "FlexKomSigLaenge" SG_ 914 MC_VSIM_C1 64;
BA_ "FlexKomSigName" SG_ 914 MC_VSIM_C1 "VSIM_PTO_Pkt";
BA_ "FlexKomComment" SG_ 914 MC_VSIM_C1 "Power takeoff packet";
BA_ "FlexKomIsMotorola" SG_ 914 MC_VSIM_C1 1;
BA_ "GenSigSNA" SG_ 914 MC_VSIM_C1 "0h";
BA_ "GenSigCycleTime" SG_ 914 CRC_VSIM_C1 250;
BA_ "FlexKomSigStartValue" SG_ 914 CRC_VSIM_C1 "00000000000000FFh";
BA_ "GenSigStartValue" SG_ 914 CRC_VSIM_C1 255;
BA_ "GenSigTimeout_CBC" SG_ 914 CRC_VSIM_C1 2625;
BA_ "FlexKomSID" SG_ 914 CRC_VSIM_C1 1799;
BA_ "FlexKomSigStartPos" SG_ 914 CRC_VSIM_C1 7;
BA_ "FlexKomSigLaenge" SG_ 914 CRC_VSIM_C1 64;
BA_ "FlexKomSigName" SG_ 914 CRC_VSIM_C1 "VSIM_PTO_Pkt";
BA_ "FlexKomComment" SG_ 914 CRC_VSIM_C1 "Power takeoff packet";
BA_ "FlexKomIsMotorola" SG_ 914 CRC_VSIM_C1 1;
BA_ "GenSigSNA" SG_ 914 CRC_VSIM_C1 "FFh";
BA_ "GenSigSendType" SG_ 916 STEREO_MD 5;
BA_ "GenSigCycleTime" SG_ 916 STEREO_MD 1000;
BA_ "FlexKomSigStartValue" SG_ 916 STEREO_MD "00h";
BA_ "FlexKomSID" SG_ 916 STEREO_MD 736;
BA_ "FlexKomSigLaenge" SG_ 916 STEREO_MD 1;
BA_ "FlexKomSigName" SG_ 916 STEREO_MD "STEREO_MD";
BA_ "FlexKomComment" SG_ 916 STEREO_MD "No HFM mode RQ=[0], HFM mode RQ = [1]";
BA_ "FlexKomIsMotorola" SG_ 916 STEREO_MD 1;
BA_ "GenSigSNA" SG_ 916 STEREO_MD "0h";
BA_ "GenSigSendType" SG_ 916 SupHrnRq 5;
BA_ "GenSigCycleTime" SG_ 916 SupHrnRq 1000;
BA_ "FlexKomSigStartValue" SG_ 916 SupHrnRq "00h";
BA_ "FlexKomSID" SG_ 916 SupHrnRq 737;
BA_ "FlexKomSigStartPos" SG_ 916 SupHrnRq 1;
BA_ "FlexKomSigLaenge" SG_ 916 SupHrnRq 1;
BA_ "FlexKomSigName" SG_ 916 SupHrnRq "SupHrnRq";
BA_ "FlexKomComment" SG_ 916 SupHrnRq "Suppress horn request";
BA_ "FlexKomIsMotorola" SG_ 916 SupHrnRq 1;
BA_ "GenSigSNA" SG_ 916 SupHrnRq "0h";
BA_ "GenSigSendType" SG_ 916 PNC_ALM_MUTE 5;
BA_ "GenSigCycleTime" SG_ 916 PNC_ALM_MUTE 1000;
BA_ "FlexKomSigStartValue" SG_ 916 PNC_ALM_MUTE "00h";
BA_ "FlexKomSID" SG_ 916 PNC_ALM_MUTE 738;
BA_ "FlexKomSigStartPos" SG_ 916 PNC_ALM_MUTE 2;
BA_ "FlexKomSigLaenge" SG_ 916 PNC_ALM_MUTE 1;
BA_ "FlexKomSigName" SG_ 916 PNC_ALM_MUTE "PNC_ALM_MUTE";
BA_ "FlexKomComment" SG_ 916 PNC_ALM_MUTE "Panic alarm mute";
BA_ "FlexKomIsMotorola" SG_ 916 PNC_ALM_MUTE 1;
BA_ "GenSigSNA" SG_ 916 PNC_ALM_MUTE "0h";
BA_ "GenSigSendType" SG_ 916 FtWigWagRq 5;
BA_ "GenSigCycleTime" SG_ 916 FtWigWagRq 1000;
BA_ "FlexKomSigStartValue" SG_ 916 FtWigWagRq "00h";
BA_ "FlexKomSID" SG_ 916 FtWigWagRq 739;
BA_ "FlexKomSigStartPos" SG_ 916 FtWigWagRq 4;
BA_ "FlexKomSigLaenge" SG_ 916 FtWigWagRq 2;
BA_ "FlexKomSigName" SG_ 916 FtWigWagRq "WigWagPkt";
BA_ "FlexKomComment" SG_ 916 FtWigWagRq "Exterior lighting wig wag packet";
BA_ "FlexKomIsMotorola" SG_ 916 FtWigWagRq 1;
BA_ "GenSigSNA" SG_ 916 FtWigWagRq "0h";
BA_ "GenSigSendType" SG_ 916 RrWigWagRq 5;
BA_ "GenSigCycleTime" SG_ 916 RrWigWagRq 1000;
BA_ "FlexKomSigStartValue" SG_ 916 RrWigWagRq "00h";
BA_ "FlexKomSID" SG_ 916 RrWigWagRq 739;
BA_ "FlexKomSigStartPos" SG_ 916 RrWigWagRq 4;
BA_ "FlexKomSigLaenge" SG_ 916 RrWigWagRq 2;
BA_ "FlexKomSigName" SG_ 916 RrWigWagRq "WigWagPkt";
BA_ "FlexKomComment" SG_ 916 RrWigWagRq "Exterior lighting wig wag packet";
BA_ "FlexKomIsMotorola" SG_ 916 RrWigWagRq 1;
BA_ "GenSigSNA" SG_ 916 RrWigWagRq "0h";
BA_ "GenSigSendType" SG_ 916 AudioMuteRq 5;
BA_ "GenSigCycleTime" SG_ 916 AudioMuteRq 1000;
BA_ "FlexKomSigStartValue" SG_ 916 AudioMuteRq "00h";
BA_ "FlexKomSID" SG_ 916 AudioMuteRq 1936;
BA_ "FlexKomSigStartPos" SG_ 916 AudioMuteRq 5;
BA_ "FlexKomSigLaenge" SG_ 916 AudioMuteRq 1;
BA_ "FlexKomSigName" SG_ 916 AudioMuteRq "AudioMuteRq";
BA_ "FlexKomComment" SG_ 916 AudioMuteRq "Audio mute request; Audio mute = [1]";
BA_ "FlexKomIsMotorola" SG_ 916 AudioMuteRq 1;
BA_ "GenSigSNA" SG_ 916 AudioMuteRq "0h";
BA_ "GenSigSendType" SG_ 916 PlowHL_Stat 5;
BA_ "GenSigCycleTime" SG_ 916 PlowHL_Stat 1000;
BA_ "FlexKomSigStartValue" SG_ 916 PlowHL_Stat "00h";
BA_ "GenSigTimeout_CBC" SG_ 916 PlowHL_Stat 10500;
BA_ "FlexKomSID" SG_ 916 PlowHL_Stat 1751;
BA_ "FlexKomSigStartPos" SG_ 916 PlowHL_Stat 7;
BA_ "FlexKomSigLaenge" SG_ 916 PlowHL_Stat 2;
BA_ "FlexKomSigName" SG_ 916 PlowHL_Stat "PlowHL_Stat";
BA_ "FlexKomComment" SG_ 916 PlowHL_Stat "Snowplow headlamp status";
BA_ "FlexKomIsMotorola" SG_ 916 PlowHL_Stat 1;
BA_ "GenSigSNA" SG_ 916 PlowHL_Stat "3h";
BA_ "GenSigSendType" SG_ 916 SnowPlowPrsnt 5;
BA_ "GenSigCycleTime" SG_ 916 SnowPlowPrsnt 1000;
BA_ "FlexKomSigStartValue" SG_ 916 SnowPlowPrsnt "00h";
BA_ "FlexKomSID" SG_ 916 SnowPlowPrsnt 1752;
BA_ "FlexKomSigStartPos" SG_ 916 SnowPlowPrsnt 8;
BA_ "FlexKomSigLaenge" SG_ 916 SnowPlowPrsnt 1;
BA_ "FlexKomSigName" SG_ 916 SnowPlowPrsnt "SnowPlowPrsnt";
BA_ "FlexKomComment" SG_ 916 SnowPlowPrsnt "Snowplow is present; true = [1]";
BA_ "FlexKomIsMotorola" SG_ 916 SnowPlowPrsnt 1;
BA_ "GenSigSNA" SG_ 916 SnowPlowPrsnt "0h";
BA_ "GenSigSendType" SG_ 916 VSIM_LBeamFlt 5;
BA_ "GenSigCycleTime" SG_ 916 VSIM_LBeamFlt 1000;
BA_ "FlexKomSigStartValue" SG_ 916 VSIM_LBeamFlt "00h";
BA_ "FlexKomSID" SG_ 916 VSIM_LBeamFlt 1753;
BA_ "FlexKomSigStartPos" SG_ 916 VSIM_LBeamFlt 9;
BA_ "FlexKomSigLaenge" SG_ 916 VSIM_LBeamFlt 1;
BA_ "FlexKomSigName" SG_ 916 VSIM_LBeamFlt "VSIM_LBeamFlt";
BA_ "FlexKomComment" SG_ 916 VSIM_LBeamFlt "VSIM low beam headlamp faulted";
BA_ "FlexKomIsMotorola" SG_ 916 VSIM_LBeamFlt 1;
BA_ "GenSigSNA" SG_ 916 VSIM_LBeamFlt "0h";
BA_ "GenSigSendType" SG_ 916 VSIM_HBeamFlt 5;
BA_ "GenSigCycleTime" SG_ 916 VSIM_HBeamFlt 1000;
BA_ "FlexKomSigStartValue" SG_ 916 VSIM_HBeamFlt "00h";
BA_ "FlexKomSID" SG_ 916 VSIM_HBeamFlt 1754;
BA_ "FlexKomSigStartPos" SG_ 916 VSIM_HBeamFlt 10;
BA_ "FlexKomSigLaenge" SG_ 916 VSIM_HBeamFlt 1;
BA_ "FlexKomSigName" SG_ 916 VSIM_HBeamFlt "VSIM_HBeamFlt";
BA_ "FlexKomComment" SG_ 916 VSIM_HBeamFlt "VSIM high beam headlamp faulted";
BA_ "FlexKomIsMotorola" SG_ 916 VSIM_HBeamFlt 1;
BA_ "GenSigSNA" SG_ 916 VSIM_HBeamFlt "0h";
BA_ "GenSigSendType" SG_ 916 VSIM_TS_Flt_RL 5;
BA_ "GenSigCycleTime" SG_ 916 VSIM_TS_Flt_RL 1000;
BA_ "FlexKomSigStartValue" SG_ 916 VSIM_TS_Flt_RL "00h";
BA_ "FlexKomSID" SG_ 916 VSIM_TS_Flt_RL 1755;
BA_ "FlexKomSigStartPos" SG_ 916 VSIM_TS_Flt_RL 11;
BA_ "FlexKomSigLaenge" SG_ 916 VSIM_TS_Flt_RL 1;
BA_ "FlexKomSigName" SG_ 916 VSIM_TS_Flt_RL "VSIM_TS_Flt_RL";
BA_ "FlexKomComment" SG_ 916 VSIM_TS_Flt_RL "VSIM turn signal fault - left rear";
BA_ "FlexKomIsMotorola" SG_ 916 VSIM_TS_Flt_RL 1;
BA_ "GenSigSNA" SG_ 916 VSIM_TS_Flt_RL "0h";
BA_ "GenSigSendType" SG_ 916 VSIM_TS_Flt_RR 5;
BA_ "GenSigCycleTime" SG_ 916 VSIM_TS_Flt_RR 1000;
BA_ "FlexKomSigStartValue" SG_ 916 VSIM_TS_Flt_RR "00h";
BA_ "FlexKomSID" SG_ 916 VSIM_TS_Flt_RR 1756;
BA_ "FlexKomSigStartPos" SG_ 916 VSIM_TS_Flt_RR 12;
BA_ "FlexKomSigLaenge" SG_ 916 VSIM_TS_Flt_RR 1;
BA_ "FlexKomSigName" SG_ 916 VSIM_TS_Flt_RR "VSIM_TS_Flt_RR";
BA_ "FlexKomComment" SG_ 916 VSIM_TS_Flt_RR "VSIM turn signal fault - right rear";
BA_ "FlexKomIsMotorola" SG_ 916 VSIM_TS_Flt_RR 1;
BA_ "GenSigSNA" SG_ 916 VSIM_TS_Flt_RR "0h";
BA_ "GenSigSendType" SG_ 916 VSIM_TS 5;
BA_ "GenSigCycleTime" SG_ 916 VSIM_TS 1000;
BA_ "FlexKomSigStartValue" SG_ 916 VSIM_TS "00h";
BA_ "FlexKomSID" SG_ 916 VSIM_TS 1757;
BA_ "FlexKomSigStartPos" SG_ 916 VSIM_TS 13;
BA_ "FlexKomSigLaenge" SG_ 916 VSIM_TS 1;
BA_ "FlexKomSigName" SG_ 916 VSIM_TS "VSIM_TS";
BA_ "FlexKomComment" SG_ 916 VSIM_TS "VSIM driven turn signals";
BA_ "FlexKomIsMotorola" SG_ 916 VSIM_TS 1;
BA_ "GenSigSNA" SG_ 916 VSIM_TS "0h";
BA_ "GenSigSendType" SG_ 916 DsblTurnLmpFlt 5;
BA_ "GenSigCycleTime" SG_ 916 DsblTurnLmpFlt 1000;
BA_ "FlexKomSigStartValue" SG_ 916 DsblTurnLmpFlt "00h";
BA_ "FlexKomSID" SG_ 916 DsblTurnLmpFlt 1758;
BA_ "FlexKomSigStartPos" SG_ 916 DsblTurnLmpFlt 14;
BA_ "FlexKomSigLaenge" SG_ 916 DsblTurnLmpFlt 1;
BA_ "FlexKomSigName" SG_ 916 DsblTurnLmpFlt "DsblTurnLmpFlt";
BA_ "FlexKomComment" SG_ 916 DsblTurnLmpFlt "Disable rear turn lamp fault";
BA_ "FlexKomIsMotorola" SG_ 916 DsblTurnLmpFlt 1;
BA_ "GenSigSNA" SG_ 916 DsblTurnLmpFlt "0h";
BA_ "GenSigSendType" SG_ 916 SprtRearLtg 5;
BA_ "GenSigCycleTime" SG_ 916 SprtRearLtg 1000;
BA_ "FlexKomSigStartValue" SG_ 916 SprtRearLtg "00h";
BA_ "FlexKomSID" SG_ 916 SprtRearLtg 1759;
BA_ "FlexKomSigStartPos" SG_ 916 SprtRearLtg 15;
BA_ "FlexKomSigLaenge" SG_ 916 SprtRearLtg 1;
BA_ "FlexKomSigName" SG_ 916 SprtRearLtg "SprtRearLtg";
BA_ "FlexKomComment" SG_ 916 SprtRearLtg "Separate rear lighting";
BA_ "FlexKomIsMotorola" SG_ 916 SprtRearLtg 1;
BA_ "GenSigSNA" SG_ 916 SprtRearLtg "0h";
BA_ "GenSigSendType" SG_ 916 VSIM_DualQual_Req 5;
BA_ "GenSigCycleTime" SG_ 916 VSIM_DualQual_Req 1000;
BA_ "FlexKomSigStartValue" SG_ 916 VSIM_DualQual_Req "00h";
BA_ "FlexKomSID" SG_ 916 VSIM_DualQual_Req 1937;
BA_ "FlexKomSigStartPos" SG_ 916 VSIM_DualQual_Req 21;
BA_ "FlexKomSigLaenge" SG_ 916 VSIM_DualQual_Req 1;
BA_ "FlexKomSigName" SG_ 916 VSIM_DualQual_Req "VSIM_DualQual_Req";
BA_ "FlexKomComment" SG_ 916 VSIM_DualQual_Req "Quad headlamp control is required; Quad = [1]";
BA_ "FlexKomIsMotorola" SG_ 916 VSIM_DualQual_Req 1;
BA_ "GenSigSNA" SG_ 916 VSIM_DualQual_Req "0h";
BA_ "GenSigSendType" SG_ 916 VSIM_DRL_Req 5;
BA_ "GenSigCycleTime" SG_ 916 VSIM_DRL_Req 1000;
BA_ "FlexKomSigStartValue" SG_ 916 VSIM_DRL_Req "00h";
BA_ "FlexKomSID" SG_ 916 VSIM_DRL_Req 1938;
BA_ "FlexKomSigStartPos" SG_ 916 VSIM_DRL_Req 22;
BA_ "FlexKomSigLaenge" SG_ 916 VSIM_DRL_Req 1;
BA_ "FlexKomSigName" SG_ 916 VSIM_DRL_Req "VSIM_DRL_Req";
BA_ "FlexKomComment" SG_ 916 VSIM_DRL_Req "Front DRL control is required; DRL = [1]";
BA_ "FlexKomIsMotorola" SG_ 916 VSIM_DRL_Req 1;
BA_ "GenSigSNA" SG_ 916 VSIM_DRL_Req "0h";
BA_ "GenSigSendType" SG_ 916 R_AC_Enable 5;
BA_ "GenSigCycleTime" SG_ 916 R_AC_Enable 1000;
BA_ "FlexKomSigStartValue" SG_ 916 R_AC_Enable "00h";
BA_ "FlexKomSID" SG_ 916 R_AC_Enable 1939;
BA_ "FlexKomSigStartPos" SG_ 916 R_AC_Enable 23;
BA_ "FlexKomSigLaenge" SG_ 916 R_AC_Enable 1;
BA_ "FlexKomSigName" SG_ 916 R_AC_Enable "R_AC_Enable";
BA_ "FlexKomComment" SG_ 916 R_AC_Enable "Rear A/C enable request; On = [1]";
BA_ "FlexKomIsMotorola" SG_ 916 R_AC_Enable 1;
BA_ "GenSigSNA" SG_ 916 R_AC_Enable "0h";
BA_ "GenSigSendType" SG_ 920 TCM_HSD 1;
BA_ "FlexKomSigStartValue" SG_ 920 TCM_HSD "0000000000000000h";
BA_ "FlexKomSID" SG_ 920 TCM_HSD 802;
BA_ "FlexKomSigStartPos" SG_ 920 TCM_HSD 7;
BA_ "FlexKomSigLaenge" SG_ 920 TCM_HSD 64;
BA_ "FlexKomSigName" SG_ 920 TCM_HSD "TCM_HSD";
BA_ "FlexKomComment" SG_ 920 TCM_HSD "Manual control at test bench";
BA_ "FlexKomIsMotorola" SG_ 920 TCM_HSD 1;
BA_ "GenSigSNA" SG_ 920 TCM_HSD "0h";
BA_ "GenSigSendType" SG_ 924 MsgFobBattLow 5;
BA_ "GenSigCycleTime" SG_ 924 MsgFobBattLow 1000;
BA_ "FlexKomSigStartValue" SG_ 924 MsgFobBattLow "000000h";
BA_ "GenSigTimeout_IC" SG_ 924 MsgFobBattLow 10500;
BA_ "FlexKomSID" SG_ 924 MsgFobBattLow 1038;
BA_ "FlexKomSigStartPos" SG_ 924 MsgFobBattLow 7;
BA_ "FlexKomSigLaenge" SG_ 924 MsgFobBattLow 24;
BA_ "FlexKomSigName" SG_ 924 MsgFobBattLow "RFMsgPkt";
BA_ "FlexKomComment" SG_ 924 MsgFobBattLow "RF message packet";
BA_ "FlexKomIsMotorola" SG_ 924 MsgFobBattLow 1;
BA_ "GenSigSNA" SG_ 924 MsgFobBattLow "3h";
BA_ "GenSigSendType" SG_ 924 MsgServPEKG 5;
BA_ "GenSigCycleTime" SG_ 924 MsgServPEKG 1000;
BA_ "FlexKomSigStartValue" SG_ 924 MsgServPEKG "000000h";
BA_ "GenSigTimeout_IC" SG_ 924 MsgServPEKG 10500;
BA_ "FlexKomSID" SG_ 924 MsgServPEKG 1038;
BA_ "FlexKomSigStartPos" SG_ 924 MsgServPEKG 7;
BA_ "FlexKomSigLaenge" SG_ 924 MsgServPEKG 24;
BA_ "FlexKomSigName" SG_ 924 MsgServPEKG "RFMsgPkt";
BA_ "FlexKomComment" SG_ 924 MsgServPEKG "RF message packet";
BA_ "FlexKomIsMotorola" SG_ 924 MsgServPEKG 1;
BA_ "GenSigSNA" SG_ 924 MsgServPEKG "3h";
BA_ "GenSigSendType" SG_ 924 MsgFobNotFnd 5;
BA_ "GenSigCycleTime" SG_ 924 MsgFobNotFnd 1000;
BA_ "FlexKomSigStartValue" SG_ 924 MsgFobNotFnd "000000h";
BA_ "GenSigTimeout_IC" SG_ 924 MsgFobNotFnd 10500;
BA_ "FlexKomSID" SG_ 924 MsgFobNotFnd 1038;
BA_ "FlexKomSigStartPos" SG_ 924 MsgFobNotFnd 7;
BA_ "FlexKomSigLaenge" SG_ 924 MsgFobNotFnd 24;
BA_ "FlexKomSigName" SG_ 924 MsgFobNotFnd "RFMsgPkt";
BA_ "FlexKomComment" SG_ 924 MsgFobNotFnd "RF message packet";
BA_ "FlexKomIsMotorola" SG_ 924 MsgFobNotFnd 1;
BA_ "GenSigSNA" SG_ 924 MsgFobNotFnd "3h";
BA_ "GenSigSendType" SG_ 924 MsgNotInPark 5;
BA_ "GenSigCycleTime" SG_ 924 MsgNotInPark 1000;
BA_ "FlexKomSigStartValue" SG_ 924 MsgNotInPark "000000h";
BA_ "GenSigTimeout_IC" SG_ 924 MsgNotInPark 10500;
BA_ "FlexKomSID" SG_ 924 MsgNotInPark 1038;
BA_ "FlexKomSigStartPos" SG_ 924 MsgNotInPark 7;
BA_ "FlexKomSigLaenge" SG_ 924 MsgNotInPark 24;
BA_ "FlexKomSigName" SG_ 924 MsgNotInPark "RFMsgPkt";
BA_ "FlexKomComment" SG_ 924 MsgNotInPark "RF message packet";
BA_ "FlexKomIsMotorola" SG_ 924 MsgNotInPark 1;
BA_ "GenSigSNA" SG_ 924 MsgNotInPark "3h";
BA_ "GenSigSendType" SG_ 924 MsgVehMove 5;
BA_ "GenSigCycleTime" SG_ 924 MsgVehMove 1000;
BA_ "FlexKomSigStartValue" SG_ 924 MsgVehMove "000000h";
BA_ "GenSigTimeout_IC" SG_ 924 MsgVehMove 10500;
BA_ "FlexKomSID" SG_ 924 MsgVehMove 1038;
BA_ "FlexKomSigStartPos" SG_ 924 MsgVehMove 7;
BA_ "FlexKomSigLaenge" SG_ 924 MsgVehMove 24;
BA_ "FlexKomSigName" SG_ 924 MsgVehMove "RFMsgPkt";
BA_ "FlexKomComment" SG_ 924 MsgVehMove "RF message packet";
BA_ "FlexKomIsMotorola" SG_ 924 MsgVehMove 1;
BA_ "GenSigSNA" SG_ 924 MsgVehMove "3h";
BA_ "GenSigSendType" SG_ 924 MsgIgnOn 5;
BA_ "GenSigCycleTime" SG_ 924 MsgIgnOn 1000;
BA_ "FlexKomSigStartValue" SG_ 924 MsgIgnOn "000000h";
BA_ "GenSigTimeout_IC" SG_ 924 MsgIgnOn 10500;
BA_ "FlexKomSID" SG_ 924 MsgIgnOn 1038;
BA_ "FlexKomSigStartPos" SG_ 924 MsgIgnOn 7;
BA_ "FlexKomSigLaenge" SG_ 924 MsgIgnOn 24;
BA_ "FlexKomSigName" SG_ 924 MsgIgnOn "RFMsgPkt";
BA_ "FlexKomComment" SG_ 924 MsgIgnOn "RF message packet";
BA_ "FlexKomIsMotorola" SG_ 924 MsgIgnOn 1;
BA_ "GenSigSNA" SG_ 924 MsgIgnOn "3h";
BA_ "GenSigSendType" SG_ 924 MsgKG1 5;
BA_ "GenSigCycleTime" SG_ 924 MsgKG1 1000;
BA_ "FlexKomSigStartValue" SG_ 924 MsgKG1 "000000h";
BA_ "GenSigTimeout_IC" SG_ 924 MsgKG1 10500;
BA_ "FlexKomSID" SG_ 924 MsgKG1 1038;
BA_ "FlexKomSigStartPos" SG_ 924 MsgKG1 7;
BA_ "FlexKomSigLaenge" SG_ 924 MsgKG1 24;
BA_ "FlexKomSigName" SG_ 924 MsgKG1 "RFMsgPkt";
BA_ "FlexKomComment" SG_ 924 MsgKG1 "RF message packet";
BA_ "FlexKomIsMotorola" SG_ 924 MsgKG1 1;
BA_ "GenSigSNA" SG_ 924 MsgKG1 "3h";
BA_ "GenSigSendType" SG_ 924 MsgKG2 5;
BA_ "GenSigCycleTime" SG_ 924 MsgKG2 1000;
BA_ "FlexKomSigStartValue" SG_ 924 MsgKG2 "000000h";
BA_ "GenSigTimeout_IC" SG_ 924 MsgKG2 10500;
BA_ "FlexKomSID" SG_ 924 MsgKG2 1038;
BA_ "FlexKomSigStartPos" SG_ 924 MsgKG2 7;
BA_ "FlexKomSigLaenge" SG_ 924 MsgKG2 24;
BA_ "FlexKomSigName" SG_ 924 MsgKG2 "RFMsgPkt";
BA_ "FlexKomComment" SG_ 924 MsgKG2 "RF message packet";
BA_ "FlexKomIsMotorola" SG_ 924 MsgKG2 1;
BA_ "GenSigSNA" SG_ 924 MsgKG2 "3h";
BA_ "GenSigSendType" SG_ 924 FOB_SrchRslt 5;
BA_ "GenSigCycleTime" SG_ 924 FOB_SrchRslt 1000;
BA_ "FlexKomSigStartValue" SG_ 924 FOB_SrchRslt "000000h";
BA_ "GenSigTimeout_CBC" SG_ 924 FOB_SrchRslt 10500;
BA_ "FlexKomSID" SG_ 924 FOB_SrchRslt 1038;
BA_ "FlexKomSigStartPos" SG_ 924 FOB_SrchRslt 7;
BA_ "FlexKomSigLaenge" SG_ 924 FOB_SrchRslt 24;
BA_ "FlexKomSigName" SG_ 924 FOB_SrchRslt "RFMsgPkt";
BA_ "FlexKomComment" SG_ 924 FOB_SrchRslt "RF message packet";
BA_ "FlexKomIsMotorola" SG_ 924 FOB_SrchRslt 1;
BA_ "GenSigSNA" SG_ 924 FOB_SrchRslt "0h";
BA_ "GenSigSendType" SG_ 924 FOB_SrchFLT 5;
BA_ "GenSigCycleTime" SG_ 924 FOB_SrchFLT 1000;
BA_ "FlexKomSigStartValue" SG_ 924 FOB_SrchFLT "000000h";
BA_ "FlexKomSID" SG_ 924 FOB_SrchFLT 1038;
BA_ "FlexKomSigStartPos" SG_ 924 FOB_SrchFLT 7;
BA_ "FlexKomSigLaenge" SG_ 924 FOB_SrchFLT 24;
BA_ "FlexKomSigName" SG_ 924 FOB_SrchFLT "RFMsgPkt";
BA_ "FlexKomComment" SG_ 924 FOB_SrchFLT "RF message packet";
BA_ "FlexKomIsMotorola" SG_ 924 FOB_SrchFLT 1;
BA_ "GenSigSNA" SG_ 924 FOB_SrchFLT "0h";
BA_ "GenSigSendType" SG_ 924 FOBinTRUNK 5;
BA_ "GenSigCycleTime" SG_ 924 FOBinTRUNK 1000;
BA_ "FlexKomSigStartValue" SG_ 924 FOBinTRUNK "000000h";
BA_ "FlexKomSID" SG_ 924 FOBinTRUNK 1038;
BA_ "FlexKomSigStartPos" SG_ 924 FOBinTRUNK 7;
BA_ "FlexKomSigLaenge" SG_ 924 FOBinTRUNK 24;
BA_ "FlexKomSigName" SG_ 924 FOBinTRUNK "RFMsgPkt";
BA_ "FlexKomComment" SG_ 924 FOBinTRUNK "RF message packet";
BA_ "FlexKomIsMotorola" SG_ 924 FOBinTRUNK 1;
BA_ "GenSigSNA" SG_ 924 FOBinTRUNK "0h";
BA_ "GenSigSendType" SG_ 924 FOBinINT 5;
BA_ "GenSigCycleTime" SG_ 924 FOBinINT 1000;
BA_ "FlexKomSigStartValue" SG_ 924 FOBinINT "000000h";
BA_ "FlexKomSID" SG_ 924 FOBinINT 1038;
BA_ "FlexKomSigStartPos" SG_ 924 FOBinINT 7;
BA_ "FlexKomSigLaenge" SG_ 924 FOBinINT 24;
BA_ "FlexKomSigName" SG_ 924 FOBinINT "RFMsgPkt";
BA_ "FlexKomComment" SG_ 924 FOBinINT "RF message packet";
BA_ "FlexKomIsMotorola" SG_ 924 FOBinINT 1;
BA_ "GenSigSNA" SG_ 924 FOBinINT "0h";
BA_ "GenSigSendType" SG_ 924 FOB_ExtRT 5;
BA_ "GenSigCycleTime" SG_ 924 FOB_ExtRT 1000;
BA_ "FlexKomSigStartValue" SG_ 924 FOB_ExtRT "000000h";
BA_ "FlexKomSID" SG_ 924 FOB_ExtRT 1038;
BA_ "FlexKomSigStartPos" SG_ 924 FOB_ExtRT 7;
BA_ "FlexKomSigLaenge" SG_ 924 FOB_ExtRT 24;
BA_ "FlexKomSigName" SG_ 924 FOB_ExtRT "RFMsgPkt";
BA_ "FlexKomComment" SG_ 924 FOB_ExtRT "RF message packet";
BA_ "FlexKomIsMotorola" SG_ 924 FOB_ExtRT 1;
BA_ "GenSigSNA" SG_ 924 FOB_ExtRT "0h";
BA_ "GenSigSendType" SG_ 924 FOB_ExtLT 5;
BA_ "GenSigCycleTime" SG_ 924 FOB_ExtLT 1000;
BA_ "FlexKomSigStartValue" SG_ 924 FOB_ExtLT "000000h";
BA_ "FlexKomSID" SG_ 924 FOB_ExtLT 1038;
BA_ "FlexKomSigStartPos" SG_ 924 FOB_ExtLT 7;
BA_ "FlexKomSigLaenge" SG_ 924 FOB_ExtLT 24;
BA_ "FlexKomSigName" SG_ 924 FOB_ExtLT "RFMsgPkt";
BA_ "FlexKomComment" SG_ 924 FOB_ExtLT "RF message packet";
BA_ "FlexKomIsMotorola" SG_ 924 FOB_ExtLT 1;
BA_ "GenSigSNA" SG_ 924 FOB_ExtLT "0h";
BA_ "GenSigSendType" SG_ 924 FOB_ExtRR 5;
BA_ "GenSigCycleTime" SG_ 924 FOB_ExtRR 1000;
BA_ "FlexKomSigStartValue" SG_ 924 FOB_ExtRR "000000h";
BA_ "FlexKomSID" SG_ 924 FOB_ExtRR 1038;
BA_ "FlexKomSigStartPos" SG_ 924 FOB_ExtRR 7;
BA_ "FlexKomSigLaenge" SG_ 924 FOB_ExtRR 24;
BA_ "FlexKomSigName" SG_ 924 FOB_ExtRR "RFMsgPkt";
BA_ "FlexKomComment" SG_ 924 FOB_ExtRR "RF message packet";
BA_ "FlexKomIsMotorola" SG_ 924 FOB_ExtRR 1;
BA_ "GenSigSNA" SG_ 924 FOB_ExtRR "0h";
BA_ "GenSigSendType" SG_ 928 ECM_APPL6 1;
BA_ "FlexKomSigStartValue" SG_ 928 ECM_APPL6 "0000000000000000h";
BA_ "FlexKomSID" SG_ 928 ECM_APPL6 784;
BA_ "FlexKomSigStartPos" SG_ 928 ECM_APPL6 7;
BA_ "FlexKomSigLaenge" SG_ 928 ECM_APPL6 64;
BA_ "FlexKomSigName" SG_ 928 ECM_APPL6 "ECM_APPL6";
BA_ "FlexKomComment" SG_ 928 ECM_APPL6 "CCP 80ms DAQ  (from ENGINE to external tool)";
BA_ "FlexKomIsMotorola" SG_ 928 ECM_APPL6 1;
BA_ "GenSigSNA" SG_ 928 ECM_APPL6 "0h";
BA_ "GenSigSendType" SG_ 936 ECM_APPL7 1;
BA_ "FlexKomSigStartValue" SG_ 936 ECM_APPL7 "0000000000000000h";
BA_ "FlexKomSID" SG_ 936 ECM_APPL7 1111;
BA_ "FlexKomSigStartPos" SG_ 936 ECM_APPL7 7;
BA_ "FlexKomSigLaenge" SG_ 936 ECM_APPL7 64;
BA_ "FlexKomSigName" SG_ 936 ECM_APPL7 "ECM_APPL7";
BA_ "FlexKomComment" SG_ 936 ECM_APPL7 "Application";
BA_ "FlexKomIsMotorola" SG_ 936 ECM_APPL7 1;
BA_ "GenSigSNA" SG_ 936 ECM_APPL7 "0h";
BA_ "GenSigSendType" SG_ 937 RKE_ONE_PRESS_ENBL 5;
BA_ "GenSigCycleTime" SG_ 937 RKE_ONE_PRESS_ENBL 1000;
BA_ "FlexKomSigStartValue" SG_ 937 RKE_ONE_PRESS_ENBL "00FFFFFFFF00h";
BA_ "GenSigTimeout_IC" SG_ 937 RKE_ONE_PRESS_ENBL 10500;
BA_ "FlexKomSID" SG_ 937 RKE_ONE_PRESS_ENBL 843;
BA_ "FlexKomSigStartPos" SG_ 937 RKE_ONE_PRESS_ENBL 7;
BA_ "FlexKomSigLaenge" SG_ 937 RKE_ONE_PRESS_ENBL 48;
BA_ "FlexKomSigName" SG_ 937 RKE_ONE_PRESS_ENBL "CBC_CFG_STAT";
BA_ "FlexKomComment" SG_ 937 RKE_ONE_PRESS_ENBL "Configuration status CBC";
BA_ "FlexKomIsMotorola" SG_ 937 RKE_ONE_PRESS_ENBL 1;
BA_ "GenSigSNA" SG_ 937 RKE_ONE_PRESS_ENBL "0h";
BA_ "GenSigSendType" SG_ 937 SOUND_LK 5;
BA_ "GenSigCycleTime" SG_ 937 SOUND_LK 1000;
BA_ "FlexKomSigStartValue" SG_ 937 SOUND_LK "00FFFFFFFF00h";
BA_ "GenSigTimeout_IC" SG_ 937 SOUND_LK 10500;
BA_ "FlexKomSID" SG_ 937 SOUND_LK 843;
BA_ "FlexKomSigStartPos" SG_ 937 SOUND_LK 7;
BA_ "FlexKomSigLaenge" SG_ 937 SOUND_LK 48;
BA_ "FlexKomSigName" SG_ 937 SOUND_LK "CBC_CFG_STAT";
BA_ "FlexKomComment" SG_ 937 SOUND_LK "Configuration status CBC";
BA_ "FlexKomIsMotorola" SG_ 937 SOUND_LK 1;
BA_ "GenSigSNA" SG_ 937 SOUND_LK "0h";
BA_ "GenSigSendType" SG_ 937 FLASH_LK 5;
BA_ "GenSigCycleTime" SG_ 937 FLASH_LK 1000;
BA_ "FlexKomSigStartValue" SG_ 937 FLASH_LK "00FFFFFFFF00h";
BA_ "GenSigTimeout_IC" SG_ 937 FLASH_LK 10500;
BA_ "FlexKomSID" SG_ 937 FLASH_LK 843;
BA_ "FlexKomSigStartPos" SG_ 937 FLASH_LK 7;
BA_ "FlexKomSigLaenge" SG_ 937 FLASH_LK 48;
BA_ "FlexKomSigName" SG_ 937 FLASH_LK "CBC_CFG_STAT";
BA_ "FlexKomComment" SG_ 937 FLASH_LK "Configuration status CBC";
BA_ "FlexKomIsMotorola" SG_ 937 FLASH_LK 1;
BA_ "GenSigSNA" SG_ 937 FLASH_LK "0h";
BA_ "GenSigSendType" SG_ 937 HL_WPR 5;
BA_ "GenSigCycleTime" SG_ 937 HL_WPR 1000;
BA_ "FlexKomSigStartValue" SG_ 937 HL_WPR "00FFFFFFFF00h";
BA_ "GenSigTimeout_IC" SG_ 937 HL_WPR 10500;
BA_ "FlexKomSID" SG_ 937 HL_WPR 843;
BA_ "FlexKomSigStartPos" SG_ 937 HL_WPR 7;
BA_ "FlexKomSigLaenge" SG_ 937 HL_WPR 48;
BA_ "FlexKomSigName" SG_ 937 HL_WPR "CBC_CFG_STAT";
BA_ "FlexKomComment" SG_ 937 HL_WPR "Configuration status CBC";
BA_ "FlexKomIsMotorola" SG_ 937 HL_WPR 1;
BA_ "GenSigSNA" SG_ 937 HL_WPR "0h";
BA_ "GenSigSendType" SG_ 937 AUTO_LK 5;
BA_ "GenSigCycleTime" SG_ 937 AUTO_LK 1000;
BA_ "FlexKomSigStartValue" SG_ 937 AUTO_LK "00FFFFFFFF00h";
BA_ "GenSigTimeout_IC" SG_ 937 AUTO_LK 10500;
BA_ "FlexKomSID" SG_ 937 AUTO_LK 843;
BA_ "FlexKomSigStartPos" SG_ 937 AUTO_LK 7;
BA_ "FlexKomSigLaenge" SG_ 937 AUTO_LK 48;
BA_ "FlexKomSigName" SG_ 937 AUTO_LK "CBC_CFG_STAT";
BA_ "FlexKomComment" SG_ 937 AUTO_LK "Configuration status CBC";
BA_ "FlexKomIsMotorola" SG_ 937 AUTO_LK 1;
BA_ "GenSigSNA" SG_ 937 AUTO_LK "0h";
BA_ "GenSigSendType" SG_ 937 AUTO_UNLK 5;
BA_ "GenSigCycleTime" SG_ 937 AUTO_UNLK 1000;
BA_ "FlexKomSigStartValue" SG_ 937 AUTO_UNLK "00FFFFFFFF00h";
BA_ "GenSigTimeout_IC" SG_ 937 AUTO_UNLK 10500;
BA_ "FlexKomSID" SG_ 937 AUTO_UNLK 843;
BA_ "FlexKomSigStartPos" SG_ 937 AUTO_UNLK 7;
BA_ "FlexKomSigLaenge" SG_ 937 AUTO_UNLK 48;
BA_ "FlexKomSigName" SG_ 937 AUTO_UNLK "CBC_CFG_STAT";
BA_ "FlexKomComment" SG_ 937 AUTO_UNLK "Configuration status CBC";
BA_ "FlexKomIsMotorola" SG_ 937 AUTO_UNLK 1;
BA_ "GenSigSNA" SG_ 937 AUTO_UNLK "0h";
BA_ "GenSigSendType" SG_ 937 DR_ALR 5;
BA_ "GenSigCycleTime" SG_ 937 DR_ALR 1000;
BA_ "FlexKomSigStartValue" SG_ 937 DR_ALR "00FFFFFFFF00h";
BA_ "GenSigTimeout_IC" SG_ 937 DR_ALR 10500;
BA_ "FlexKomSID" SG_ 937 DR_ALR 843;
BA_ "FlexKomSigStartPos" SG_ 937 DR_ALR 7;
BA_ "FlexKomSigLaenge" SG_ 937 DR_ALR 48;
BA_ "FlexKomSigName" SG_ 937 DR_ALR "CBC_CFG_STAT";
BA_ "FlexKomComment" SG_ 937 DR_ALR "Configuration status CBC";
BA_ "FlexKomIsMotorola" SG_ 937 DR_ALR 1;
BA_ "GenSigSNA" SG_ 937 DR_ALR "0h";
BA_ "GenSigSendType" SG_ 937 CFG_AUTO_WPR 5;
BA_ "GenSigCycleTime" SG_ 937 CFG_AUTO_WPR 1000;
BA_ "FlexKomSigStartValue" SG_ 937 CFG_AUTO_WPR "00FFFFFFFF00h";
BA_ "GenSigTimeout_IC" SG_ 937 CFG_AUTO_WPR 10500;
BA_ "FlexKomSID" SG_ 937 CFG_AUTO_WPR 843;
BA_ "FlexKomSigStartPos" SG_ 937 CFG_AUTO_WPR 7;
BA_ "FlexKomSigLaenge" SG_ 937 CFG_AUTO_WPR 48;
BA_ "FlexKomSigName" SG_ 937 CFG_AUTO_WPR "CBC_CFG_STAT";
BA_ "FlexKomComment" SG_ 937 CFG_AUTO_WPR "Configuration status CBC";
BA_ "FlexKomIsMotorola" SG_ 937 CFG_AUTO_WPR 1;
BA_ "GenSigSNA" SG_ 937 CFG_AUTO_WPR "0h";
BA_ "GenSigSendType" SG_ 937 ILL_APRCH_TIME 5;
BA_ "GenSigCycleTime" SG_ 937 ILL_APRCH_TIME 1000;
BA_ "FlexKomSigStartValue" SG_ 937 ILL_APRCH_TIME "00FFFFFFFF00h";
BA_ "GenSigStartValue" SG_ 937 ILL_APRCH_TIME 255;
BA_ "GenSigTimeout_IC" SG_ 937 ILL_APRCH_TIME 10500;
BA_ "FlexKomSID" SG_ 937 ILL_APRCH_TIME 843;
BA_ "FlexKomSigStartPos" SG_ 937 ILL_APRCH_TIME 7;
BA_ "FlexKomSigLaenge" SG_ 937 ILL_APRCH_TIME 48;
BA_ "FlexKomSigName" SG_ 937 ILL_APRCH_TIME "CBC_CFG_STAT";
BA_ "FlexKomComment" SG_ 937 ILL_APRCH_TIME "Configuration status CBC";
BA_ "FlexKomIsMotorola" SG_ 937 ILL_APRCH_TIME 1;
BA_ "GenSigSNA" SG_ 937 ILL_APRCH_TIME "FFh";
BA_ "GenSigSendType" SG_ 937 HL_DLY_TIME 5;
BA_ "GenSigCycleTime" SG_ 937 HL_DLY_TIME 1000;
BA_ "FlexKomSigStartValue" SG_ 937 HL_DLY_TIME "00FFFFFFFF00h";
BA_ "GenSigStartValue" SG_ 937 HL_DLY_TIME 255;
BA_ "GenSigTimeout_IC" SG_ 937 HL_DLY_TIME 10500;
BA_ "FlexKomSID" SG_ 937 HL_DLY_TIME 843;
BA_ "FlexKomSigStartPos" SG_ 937 HL_DLY_TIME 7;
BA_ "FlexKomSigLaenge" SG_ 937 HL_DLY_TIME 48;
BA_ "FlexKomSigName" SG_ 937 HL_DLY_TIME "CBC_CFG_STAT";
BA_ "FlexKomComment" SG_ 937 HL_DLY_TIME "Configuration status CBC";
BA_ "FlexKomIsMotorola" SG_ 937 HL_DLY_TIME 1;
BA_ "GenSigSNA" SG_ 937 HL_DLY_TIME "FFh";
BA_ "GenSigSendType" SG_ 937 ACC_DLY_TIME 5;
BA_ "GenSigCycleTime" SG_ 937 ACC_DLY_TIME 1000;
BA_ "FlexKomSigStartValue" SG_ 937 ACC_DLY_TIME "00FFFFFFFF00h";
BA_ "GenSigStartValue" SG_ 937 ACC_DLY_TIME 65535;
BA_ "GenSigTimeout_IC" SG_ 937 ACC_DLY_TIME 10500;
BA_ "FlexKomSID" SG_ 937 ACC_DLY_TIME 843;
BA_ "FlexKomSigStartPos" SG_ 937 ACC_DLY_TIME 7;
BA_ "FlexKomSigLaenge" SG_ 937 ACC_DLY_TIME 48;
BA_ "FlexKomSigName" SG_ 937 ACC_DLY_TIME "CBC_CFG_STAT";
BA_ "FlexKomComment" SG_ 937 ACC_DLY_TIME "Configuration status CBC";
BA_ "FlexKomIsMotorola" SG_ 937 ACC_DLY_TIME 1;
BA_ "GenSigSNA" SG_ 937 ACC_DLY_TIME "FFFFh";
BA_ "GenSigSendType" SG_ 937 DRL_ON 5;
BA_ "GenSigCycleTime" SG_ 937 DRL_ON 1000;
BA_ "FlexKomSigStartValue" SG_ 937 DRL_ON "00FFFFFFFF00h";
BA_ "GenSigTimeout_IC" SG_ 937 DRL_ON 10500;
BA_ "FlexKomSID" SG_ 937 DRL_ON 843;
BA_ "FlexKomSigStartPos" SG_ 937 DRL_ON 7;
BA_ "FlexKomSigLaenge" SG_ 937 DRL_ON 48;
BA_ "FlexKomSigName" SG_ 937 DRL_ON "CBC_CFG_STAT";
BA_ "FlexKomComment" SG_ 937 DRL_ON "Configuration status CBC";
BA_ "FlexKomIsMotorola" SG_ 937 DRL_ON 1;
BA_ "GenSigSNA" SG_ 937 DRL_ON "0h";
BA_ "GenSigSendType" SG_ 937 ECM_Enbl 5;
BA_ "GenSigCycleTime" SG_ 937 ECM_Enbl 1000;
BA_ "FlexKomSigStartValue" SG_ 937 ECM_Enbl "00FFFFFFFF00h";
BA_ "GenSigTimeout_IC" SG_ 937 ECM_Enbl 10500;
BA_ "FlexKomSID" SG_ 937 ECM_Enbl 843;
BA_ "FlexKomSigStartPos" SG_ 937 ECM_Enbl 7;
BA_ "FlexKomSigLaenge" SG_ 937 ECM_Enbl 48;
BA_ "FlexKomSigName" SG_ 937 ECM_Enbl "CBC_CFG_STAT";
BA_ "FlexKomComment" SG_ 937 ECM_Enbl "Configuration status CBC";
BA_ "FlexKomIsMotorola" SG_ 937 ECM_Enbl 1;
BA_ "GenSigSNA" SG_ 937 ECM_Enbl "0h";
BA_ "GenSigSendType" SG_ 937 RemLoHrnEnbl 5;
BA_ "GenSigCycleTime" SG_ 937 RemLoHrnEnbl 1000;
BA_ "FlexKomSigStartValue" SG_ 937 RemLoHrnEnbl "00h";
BA_ "GenSigTimeout_IC" SG_ 937 RemLoHrnEnbl 10500;
BA_ "FlexKomSID" SG_ 937 RemLoHrnEnbl 1813;
BA_ "FlexKomSigStartPos" SG_ 937 RemLoHrnEnbl 50;
BA_ "FlexKomSigLaenge" SG_ 937 RemLoHrnEnbl 1;
BA_ "FlexKomSigName" SG_ 937 RemLoHrnEnbl "RemLoHrnEnbl";
BA_ "FlexKomComment" SG_ 937 RemLoHrnEnbl "Remote lowering horn enabled";
BA_ "FlexKomIsMotorola" SG_ 937 RemLoHrnEnbl 1;
BA_ "GenSigSNA" SG_ 937 RemLoHrnEnbl "0h";
BA_ "GenSigSendType" SG_ 937 RemLoLgtEnbl 5;
BA_ "GenSigCycleTime" SG_ 937 RemLoLgtEnbl 1000;
BA_ "FlexKomSigStartValue" SG_ 937 RemLoLgtEnbl "00h";
BA_ "GenSigTimeout_IC" SG_ 937 RemLoLgtEnbl 10500;
BA_ "FlexKomSID" SG_ 937 RemLoLgtEnbl 1812;
BA_ "FlexKomSigStartPos" SG_ 937 RemLoLgtEnbl 51;
BA_ "FlexKomSigLaenge" SG_ 937 RemLoLgtEnbl 1;
BA_ "FlexKomSigName" SG_ 937 RemLoLgtEnbl "RemLoLgtEnbl";
BA_ "FlexKomComment" SG_ 937 RemLoLgtEnbl "Remote lowering lights enabled";
BA_ "FlexKomIsMotorola" SG_ 937 RemLoLgtEnbl 1;
BA_ "GenSigSNA" SG_ 937 RemLoLgtEnbl "0h";
BA_ "GenSigSendType" SG_ 937 SOUND_RS 5;
BA_ "GenSigCycleTime" SG_ 937 SOUND_RS 1000;
BA_ "FlexKomSigStartValue" SG_ 937 SOUND_RS "00h";
BA_ "GenSigTimeout_IC" SG_ 937 SOUND_RS 10500;
BA_ "FlexKomSID" SG_ 937 SOUND_RS 966;
BA_ "FlexKomSigStartPos" SG_ 937 SOUND_RS 52;
BA_ "FlexKomSigLaenge" SG_ 937 SOUND_RS 1;
BA_ "FlexKomSigName" SG_ 937 SOUND_RS "SOUND_RS";
BA_ "FlexKomComment" SG_ 937 SOUND_RS "Sound horn on Remote Start ; no = [0], yes = [1]";
BA_ "FlexKomIsMotorola" SG_ 937 SOUND_RS 1;
BA_ "GenSigSNA" SG_ 937 SOUND_RS "0h";
BA_ "GenSigSendType" SG_ 937 AUTO_RELK 5;
BA_ "GenSigCycleTime" SG_ 937 AUTO_RELK 1000;
BA_ "FlexKomSigStartValue" SG_ 937 AUTO_RELK "00h";
BA_ "GenSigTimeout_IC" SG_ 937 AUTO_RELK 10500;
BA_ "FlexKomSID" SG_ 937 AUTO_RELK 1079;
BA_ "FlexKomSigStartPos" SG_ 937 AUTO_RELK 53;
BA_ "FlexKomSigLaenge" SG_ 937 AUTO_RELK 1;
BA_ "FlexKomSigName" SG_ 937 AUTO_RELK "AUTO_RELK";
BA_ "FlexKomComment" SG_ 937 AUTO_RELK "Auto relock; enabled = [1]";
BA_ "FlexKomIsMotorola" SG_ 937 AUTO_RELK 1;
BA_ "GenSigSNA" SG_ 937 AUTO_RELK "0h";
BA_ "GenSigSendType" SG_ 937 StaticGridResp 5;
BA_ "GenSigCycleTime" SG_ 937 StaticGridResp 1000;
BA_ "FlexKomSigStartValue" SG_ 937 StaticGridResp "01h";
BA_ "GenSigStartValue" SG_ 937 StaticGridResp 1;
BA_ "GenSigTimeout_IC" SG_ 937 StaticGridResp 10500;
BA_ "FlexKomSID" SG_ 937 StaticGridResp 1879;
BA_ "FlexKomSigStartPos" SG_ 937 StaticGridResp 54;
BA_ "FlexKomSigLaenge" SG_ 937 StaticGridResp 1;
BA_ "FlexKomSigName" SG_ 937 StaticGridResp "StaticGridResp";
BA_ "FlexKomComment" SG_ 937 StaticGridResp "Static Gridlines ON = [1]";
BA_ "FlexKomIsMotorola" SG_ 937 StaticGridResp 1;
BA_ "GenSigSNA" SG_ 937 StaticGridResp "1h";
BA_ "GenSigSendType" SG_ 937 DynamicGridResp 5;
BA_ "GenSigCycleTime" SG_ 937 DynamicGridResp 1000;
BA_ "FlexKomSigStartValue" SG_ 937 DynamicGridResp "01h";
BA_ "GenSigStartValue" SG_ 937 DynamicGridResp 1;
BA_ "GenSigTimeout_IC" SG_ 937 DynamicGridResp 10500;
BA_ "FlexKomSID" SG_ 937 DynamicGridResp 1878;
BA_ "FlexKomSigStartPos" SG_ 937 DynamicGridResp 55;
BA_ "FlexKomSigLaenge" SG_ 937 DynamicGridResp 1;
BA_ "FlexKomSigName" SG_ 937 DynamicGridResp "DynamicGridResp";
BA_ "FlexKomComment" SG_ 937 DynamicGridResp "Dynamic Gridlines ON = [1]";
BA_ "FlexKomIsMotorola" SG_ 937 DynamicGridResp 1;
BA_ "GenSigSNA" SG_ 937 DynamicGridResp "1h";
BA_ "GenSigSendType" SG_ 937 SOUND_LK_1ST_2ND 5;
BA_ "GenSigCycleTime" SG_ 937 SOUND_LK_1ST_2ND 1000;
BA_ "FlexKomSigStartValue" SG_ 937 SOUND_LK_1ST_2ND "03h";
BA_ "GenSigStartValue" SG_ 937 SOUND_LK_1ST_2ND 3;
BA_ "GenSigTimeout_IC" SG_ 937 SOUND_LK_1ST_2ND 10500;
BA_ "FlexKomSID" SG_ 937 SOUND_LK_1ST_2ND 1956;
BA_ "FlexKomSigStartPos" SG_ 937 SOUND_LK_1ST_2ND 57;
BA_ "FlexKomSigLaenge" SG_ 937 SOUND_LK_1ST_2ND 2;
BA_ "FlexKomSigName" SG_ 937 SOUND_LK_1ST_2ND "SOUND_LK_1ST_2ND";
BA_ "FlexKomComment" SG_ 937 SOUND_LK_1ST_2ND "Sound horn on lock status";
BA_ "FlexKomIsMotorola" SG_ 937 SOUND_LK_1ST_2ND 1;
BA_ "GenSigSNA" SG_ 937 SOUND_LK_1ST_2ND "3h";
BA_ "GenSigSendType" SG_ 944 TCM_APPL2 1;
BA_ "FlexKomSigStartValue" SG_ 944 TCM_APPL2 "0000000000000000h";
BA_ "FlexKomSID" SG_ 944 TCM_APPL2 1178;
BA_ "FlexKomSigStartPos" SG_ 944 TCM_APPL2 7;
BA_ "FlexKomSigLaenge" SG_ 944 TCM_APPL2 64;
BA_ "FlexKomSigName" SG_ 944 TCM_APPL2 "TCM_APPL2";
BA_ "FlexKomComment" SG_ 944 TCM_APPL2 "CCP to transmission";
BA_ "FlexKomIsMotorola" SG_ 944 TCM_APPL2 1;
BA_ "GenSigSNA" SG_ 944 TCM_APPL2 "0h";
BA_ "GenSigSendType" SG_ 945 TCM_APPL1 1;
BA_ "FlexKomSigStartValue" SG_ 945 TCM_APPL1 "0000000000000000h";
BA_ "FlexKomSID" SG_ 945 TCM_APPL1 778;
BA_ "FlexKomSigStartPos" SG_ 945 TCM_APPL1 7;
BA_ "FlexKomSigLaenge" SG_ 945 TCM_APPL1 64;
BA_ "FlexKomSigName" SG_ 945 TCM_APPL1 "TCM_APPL1";
BA_ "FlexKomComment" SG_ 945 TCM_APPL1 "CCP from transmission";
BA_ "FlexKomIsMotorola" SG_ 945 TCM_APPL1 1;
BA_ "GenSigSNA" SG_ 945 TCM_APPL1 "0h";
BA_ "GenSigSendType" SG_ 946 TCM_APPL3 1;
BA_ "FlexKomSigStartValue" SG_ 946 TCM_APPL3 "0000000000000000h";
BA_ "FlexKomSID" SG_ 946 TCM_APPL3 1179;
BA_ "FlexKomSigStartPos" SG_ 946 TCM_APPL3 7;
BA_ "FlexKomSigLaenge" SG_ 946 TCM_APPL3 64;
BA_ "FlexKomSigName" SG_ 946 TCM_APPL3 "TCM_APPL3";
BA_ "FlexKomComment" SG_ 946 TCM_APPL3 "CCP from transmission";
BA_ "FlexKomIsMotorola" SG_ 946 TCM_APPL3 1;
BA_ "GenSigSNA" SG_ 946 TCM_APPL3 "0h";
BA_ "GenSigSendType" SG_ 947 VC_VehCfgCSO1_Stat 5;
BA_ "GenSigCycleTime" SG_ 947 VC_VehCfgCSO1_Stat 2000;
BA_ "FlexKomSigStartValue" SG_ 947 VC_VehCfgCSO1_Stat "0300000000000000h";
BA_ "GenSigStartValue" SG_ 947 VC_VehCfgCSO1_Stat 3;
BA_ "GenSigTimeout_IC" SG_ 947 VC_VehCfgCSO1_Stat 21000;
BA_ "FlexKomSID" SG_ 947 VC_VehCfgCSO1_Stat 2006;
BA_ "FlexKomSigStartPos" SG_ 947 VC_VehCfgCSO1_Stat 7;
BA_ "FlexKomSigLaenge" SG_ 947 VC_VehCfgCSO1_Stat 64;
BA_ "FlexKomSigName" SG_ 947 VC_VehCfgCSO1_Stat "VehCfgCSM1_Pkt";
BA_ "FlexKomComment" SG_ 947 VC_VehCfgCSO1_Stat "Vehicle configuration - customer settings menu 1 P";
BA_ "FlexKomIsMotorola" SG_ 947 VC_VehCfgCSO1_Stat 1;
BA_ "GenSigSNA" SG_ 947 VC_VehCfgCSO1_Stat "3h";
BA_ "GenSigSendType" SG_ 947 VC_PRK_AST_CSO 5;
BA_ "GenSigCycleTime" SG_ 947 VC_PRK_AST_CSO 2000;
BA_ "FlexKomSigStartValue" SG_ 947 VC_PRK_AST_CSO "0300000000000000h";
BA_ "GenSigTimeout_IC" SG_ 947 VC_PRK_AST_CSO 21000;
BA_ "FlexKomSID" SG_ 947 VC_PRK_AST_CSO 2006;
BA_ "FlexKomSigStartPos" SG_ 947 VC_PRK_AST_CSO 7;
BA_ "FlexKomSigLaenge" SG_ 947 VC_PRK_AST_CSO 64;
BA_ "FlexKomSigName" SG_ 947 VC_PRK_AST_CSO "VehCfgCSM1_Pkt";
BA_ "FlexKomComment" SG_ 947 VC_PRK_AST_CSO "Vehicle configuration - customer settings menu 1 P";
BA_ "FlexKomIsMotorola" SG_ 947 VC_PRK_AST_CSO 1;
BA_ "GenSigSNA" SG_ 947 VC_PRK_AST_CSO "0h";
BA_ "GenSigSendType" SG_ 947 VC_PRK_AST_BRK_CSO 5;
BA_ "GenSigCycleTime" SG_ 947 VC_PRK_AST_BRK_CSO 2000;
BA_ "FlexKomSigStartValue" SG_ 947 VC_PRK_AST_BRK_CSO "0300000000000000h";
BA_ "GenSigTimeout_IC" SG_ 947 VC_PRK_AST_BRK_CSO 21000;
BA_ "FlexKomSID" SG_ 947 VC_PRK_AST_BRK_CSO 2006;
BA_ "FlexKomSigStartPos" SG_ 947 VC_PRK_AST_BRK_CSO 7;
BA_ "FlexKomSigLaenge" SG_ 947 VC_PRK_AST_BRK_CSO 64;
BA_ "FlexKomSigName" SG_ 947 VC_PRK_AST_BRK_CSO "VehCfgCSM1_Pkt";
BA_ "FlexKomComment" SG_ 947 VC_PRK_AST_BRK_CSO "Vehicle configuration - customer settings menu 1 P";
BA_ "FlexKomIsMotorola" SG_ 947 VC_PRK_AST_BRK_CSO 1;
BA_ "GenSigSNA" SG_ 947 VC_PRK_AST_BRK_CSO "0h";
BA_ "GenSigSendType" SG_ 947 VC_PRK_FT_VOL_CSO 5;
BA_ "GenSigCycleTime" SG_ 947 VC_PRK_FT_VOL_CSO 2000;
BA_ "FlexKomSigStartValue" SG_ 947 VC_PRK_FT_VOL_CSO "0300000000000000h";
BA_ "GenSigTimeout_IC" SG_ 947 VC_PRK_FT_VOL_CSO 21000;
BA_ "FlexKomSID" SG_ 947 VC_PRK_FT_VOL_CSO 2006;
BA_ "FlexKomSigStartPos" SG_ 947 VC_PRK_FT_VOL_CSO 7;
BA_ "FlexKomSigLaenge" SG_ 947 VC_PRK_FT_VOL_CSO 64;
BA_ "FlexKomSigName" SG_ 947 VC_PRK_FT_VOL_CSO "VehCfgCSM1_Pkt";
BA_ "FlexKomComment" SG_ 947 VC_PRK_FT_VOL_CSO "Vehicle configuration - customer settings menu 1 P";
BA_ "FlexKomIsMotorola" SG_ 947 VC_PRK_FT_VOL_CSO 1;
BA_ "GenSigSNA" SG_ 947 VC_PRK_FT_VOL_CSO "0h";
BA_ "GenSigSendType" SG_ 947 VC_PRK_RR_VOL_CSO 5;
BA_ "GenSigCycleTime" SG_ 947 VC_PRK_RR_VOL_CSO 2000;
BA_ "FlexKomSigStartValue" SG_ 947 VC_PRK_RR_VOL_CSO "0300000000000000h";
BA_ "GenSigTimeout_IC" SG_ 947 VC_PRK_RR_VOL_CSO 21000;
BA_ "FlexKomSID" SG_ 947 VC_PRK_RR_VOL_CSO 2006;
BA_ "FlexKomSigStartPos" SG_ 947 VC_PRK_RR_VOL_CSO 7;
BA_ "FlexKomSigLaenge" SG_ 947 VC_PRK_RR_VOL_CSO 64;
BA_ "FlexKomSigName" SG_ 947 VC_PRK_RR_VOL_CSO "VehCfgCSM1_Pkt";
BA_ "FlexKomComment" SG_ 947 VC_PRK_RR_VOL_CSO "Vehicle configuration - customer settings menu 1 P";
BA_ "FlexKomIsMotorola" SG_ 947 VC_PRK_RR_VOL_CSO 1;
BA_ "GenSigSNA" SG_ 947 VC_PRK_RR_VOL_CSO "0h";
BA_ "GenSigSendType" SG_ 947 VC_EPS_CSO 5;
BA_ "GenSigCycleTime" SG_ 947 VC_EPS_CSO 2000;
BA_ "FlexKomSigStartValue" SG_ 947 VC_EPS_CSO "0300000000000000h";
BA_ "GenSigTimeout_IC" SG_ 947 VC_EPS_CSO 21000;
BA_ "FlexKomSID" SG_ 947 VC_EPS_CSO 2006;
BA_ "FlexKomSigStartPos" SG_ 947 VC_EPS_CSO 7;
BA_ "FlexKomSigLaenge" SG_ 947 VC_EPS_CSO 64;
BA_ "FlexKomSigName" SG_ 947 VC_EPS_CSO "VehCfgCSM1_Pkt";
BA_ "FlexKomComment" SG_ 947 VC_EPS_CSO "Vehicle configuration - customer settings menu 1 P";
BA_ "FlexKomIsMotorola" SG_ 947 VC_EPS_CSO 1;
BA_ "GenSigSNA" SG_ 947 VC_EPS_CSO "0h";
BA_ "GenSigSendType" SG_ 947 VC_FCW_CSO 5;
BA_ "GenSigCycleTime" SG_ 947 VC_FCW_CSO 2000;
BA_ "FlexKomSigStartValue" SG_ 947 VC_FCW_CSO "0300000000000000h";
BA_ "GenSigTimeout_IC" SG_ 947 VC_FCW_CSO 21000;
BA_ "FlexKomSID" SG_ 947 VC_FCW_CSO 2006;
BA_ "FlexKomSigStartPos" SG_ 947 VC_FCW_CSO 7;
BA_ "FlexKomSigLaenge" SG_ 947 VC_FCW_CSO 64;
BA_ "FlexKomSigName" SG_ 947 VC_FCW_CSO "VehCfgCSM1_Pkt";
BA_ "FlexKomComment" SG_ 947 VC_FCW_CSO "Vehicle configuration - customer settings menu 1 P";
BA_ "FlexKomIsMotorola" SG_ 947 VC_FCW_CSO 1;
BA_ "GenSigSNA" SG_ 947 VC_FCW_CSO "0h";
BA_ "GenSigSendType" SG_ 947 VC_FCW_BRK_CSO 5;
BA_ "GenSigCycleTime" SG_ 947 VC_FCW_BRK_CSO 2000;
BA_ "FlexKomSigStartValue" SG_ 947 VC_FCW_BRK_CSO "0300000000000000h";
BA_ "GenSigTimeout_IC" SG_ 947 VC_FCW_BRK_CSO 21000;
BA_ "FlexKomSID" SG_ 947 VC_FCW_BRK_CSO 2006;
BA_ "FlexKomSigStartPos" SG_ 947 VC_FCW_BRK_CSO 7;
BA_ "FlexKomSigLaenge" SG_ 947 VC_FCW_BRK_CSO 64;
BA_ "FlexKomSigName" SG_ 947 VC_FCW_BRK_CSO "VehCfgCSM1_Pkt";
BA_ "FlexKomComment" SG_ 947 VC_FCW_BRK_CSO "Vehicle configuration - customer settings menu 1 P";
BA_ "FlexKomIsMotorola" SG_ 947 VC_FCW_BRK_CSO 1;
BA_ "GenSigSNA" SG_ 947 VC_FCW_BRK_CSO "0h";
BA_ "GenSigSendType" SG_ 947 VC_HRN_RMT_LK_CSO 5;
BA_ "GenSigCycleTime" SG_ 947 VC_HRN_RMT_LK_CSO 2000;
BA_ "FlexKomSigStartValue" SG_ 947 VC_HRN_RMT_LK_CSO "0300000000000000h";
BA_ "GenSigTimeout_IC" SG_ 947 VC_HRN_RMT_LK_CSO 21000;
BA_ "FlexKomSID" SG_ 947 VC_HRN_RMT_LK_CSO 2006;
BA_ "FlexKomSigStartPos" SG_ 947 VC_HRN_RMT_LK_CSO 7;
BA_ "FlexKomSigLaenge" SG_ 947 VC_HRN_RMT_LK_CSO 64;
BA_ "FlexKomSigName" SG_ 947 VC_HRN_RMT_LK_CSO "VehCfgCSM1_Pkt";
BA_ "FlexKomComment" SG_ 947 VC_HRN_RMT_LK_CSO "Vehicle configuration - customer settings menu 1 P";
BA_ "FlexKomIsMotorola" SG_ 947 VC_HRN_RMT_LK_CSO 1;
BA_ "GenSigSNA" SG_ 947 VC_HRN_RMT_LK_CSO "0h";
BA_ "GenSigSendType" SG_ 947 VC_HRN_RMT_ST_CSO 5;
BA_ "GenSigCycleTime" SG_ 947 VC_HRN_RMT_ST_CSO 2000;
BA_ "FlexKomSigStartValue" SG_ 947 VC_HRN_RMT_ST_CSO "0300000000000000h";
BA_ "GenSigTimeout_IC" SG_ 947 VC_HRN_RMT_ST_CSO 21000;
BA_ "FlexKomSID" SG_ 947 VC_HRN_RMT_ST_CSO 2006;
BA_ "FlexKomSigStartPos" SG_ 947 VC_HRN_RMT_ST_CSO 7;
BA_ "FlexKomSigLaenge" SG_ 947 VC_HRN_RMT_ST_CSO 64;
BA_ "FlexKomSigName" SG_ 947 VC_HRN_RMT_ST_CSO "VehCfgCSM1_Pkt";
BA_ "FlexKomComment" SG_ 947 VC_HRN_RMT_ST_CSO "Vehicle configuration - customer settings menu 1 P";
BA_ "FlexKomIsMotorola" SG_ 947 VC_HRN_RMT_ST_CSO 1;
BA_ "GenSigSNA" SG_ 947 VC_HRN_RMT_ST_CSO "0h";
BA_ "GenSigSendType" SG_ 947 VC_HRN_RMT_LWR_CSO 5;
BA_ "GenSigCycleTime" SG_ 947 VC_HRN_RMT_LWR_CSO 2000;
BA_ "FlexKomSigStartValue" SG_ 947 VC_HRN_RMT_LWR_CSO "0300000000000000h";
BA_ "GenSigTimeout_IC" SG_ 947 VC_HRN_RMT_LWR_CSO 21000;
BA_ "FlexKomSID" SG_ 947 VC_HRN_RMT_LWR_CSO 2006;
BA_ "FlexKomSigStartPos" SG_ 947 VC_HRN_RMT_LWR_CSO 7;
BA_ "FlexKomSigLaenge" SG_ 947 VC_HRN_RMT_LWR_CSO 64;
BA_ "FlexKomSigName" SG_ 947 VC_HRN_RMT_LWR_CSO "VehCfgCSM1_Pkt";
BA_ "FlexKomComment" SG_ 947 VC_HRN_RMT_LWR_CSO "Vehicle configuration - customer settings menu 1 P";
BA_ "FlexKomIsMotorola" SG_ 947 VC_HRN_RMT_LWR_CSO 1;
BA_ "GenSigSNA" SG_ 947 VC_HRN_RMT_LWR_CSO "0h";
BA_ "GenSigSendType" SG_ 947 VC_CHMSL_LINE_CSO 5;
BA_ "GenSigCycleTime" SG_ 947 VC_CHMSL_LINE_CSO 2000;
BA_ "FlexKomSigStartValue" SG_ 947 VC_CHMSL_LINE_CSO "0300000000000000h";
BA_ "GenSigTimeout_IC" SG_ 947 VC_CHMSL_LINE_CSO 21000;
BA_ "FlexKomSID" SG_ 947 VC_CHMSL_LINE_CSO 2006;
BA_ "FlexKomSigStartPos" SG_ 947 VC_CHMSL_LINE_CSO 7;
BA_ "FlexKomSigLaenge" SG_ 947 VC_CHMSL_LINE_CSO 64;
BA_ "FlexKomSigName" SG_ 947 VC_CHMSL_LINE_CSO "VehCfgCSM1_Pkt";
BA_ "FlexKomComment" SG_ 947 VC_CHMSL_LINE_CSO "Vehicle configuration - customer settings menu 1 P";
BA_ "FlexKomIsMotorola" SG_ 947 VC_CHMSL_LINE_CSO 1;
BA_ "GenSigSNA" SG_ 947 VC_CHMSL_LINE_CSO "0h";
BA_ "GenSigSendType" SG_ 947 VC_DCS_CSO 5;
BA_ "GenSigCycleTime" SG_ 947 VC_DCS_CSO 2000;
BA_ "FlexKomSigStartValue" SG_ 947 VC_DCS_CSO "0300000000000000h";
BA_ "GenSigTimeout_IC" SG_ 947 VC_DCS_CSO 21000;
BA_ "FlexKomSID" SG_ 947 VC_DCS_CSO 2006;
BA_ "FlexKomSigStartPos" SG_ 947 VC_DCS_CSO 7;
BA_ "FlexKomSigLaenge" SG_ 947 VC_DCS_CSO 64;
BA_ "FlexKomSigName" SG_ 947 VC_DCS_CSO "VehCfgCSM1_Pkt";
BA_ "FlexKomComment" SG_ 947 VC_DCS_CSO "Vehicle configuration - customer settings menu 1 P";
BA_ "FlexKomIsMotorola" SG_ 947 VC_DCS_CSO 1;
BA_ "GenSigSNA" SG_ 947 VC_DCS_CSO "0h";
BA_ "GenSigSendType" SG_ 947 VC_AUX_SWS_CSO 5;
BA_ "GenSigCycleTime" SG_ 947 VC_AUX_SWS_CSO 2000;
BA_ "FlexKomSigStartValue" SG_ 947 VC_AUX_SWS_CSO "0300000000000000h";
BA_ "GenSigTimeout_IC" SG_ 947 VC_AUX_SWS_CSO 21000;
BA_ "FlexKomSID" SG_ 947 VC_AUX_SWS_CSO 2006;
BA_ "FlexKomSigStartPos" SG_ 947 VC_AUX_SWS_CSO 7;
BA_ "FlexKomSigLaenge" SG_ 947 VC_AUX_SWS_CSO 64;
BA_ "FlexKomSigName" SG_ 947 VC_AUX_SWS_CSO "VehCfgCSM1_Pkt";
BA_ "FlexKomComment" SG_ 947 VC_AUX_SWS_CSO "Vehicle configuration - customer settings menu 1 P";
BA_ "FlexKomIsMotorola" SG_ 947 VC_AUX_SWS_CSO 1;
BA_ "GenSigSNA" SG_ 947 VC_AUX_SWS_CSO "0h";
BA_ "GenSigSendType" SG_ 947 VC_CMRA_GRDLNS_CSO 5;
BA_ "GenSigCycleTime" SG_ 947 VC_CMRA_GRDLNS_CSO 2000;
BA_ "FlexKomSigStartValue" SG_ 947 VC_CMRA_GRDLNS_CSO "0300000000000000h";
BA_ "GenSigTimeout_IC" SG_ 947 VC_CMRA_GRDLNS_CSO 21000;
BA_ "FlexKomSID" SG_ 947 VC_CMRA_GRDLNS_CSO 2006;
BA_ "FlexKomSigStartPos" SG_ 947 VC_CMRA_GRDLNS_CSO 7;
BA_ "FlexKomSigLaenge" SG_ 947 VC_CMRA_GRDLNS_CSO 64;
BA_ "FlexKomSigName" SG_ 947 VC_CMRA_GRDLNS_CSO "VehCfgCSM1_Pkt";
BA_ "FlexKomComment" SG_ 947 VC_CMRA_GRDLNS_CSO "Vehicle configuration - customer settings menu 1 P";
BA_ "FlexKomIsMotorola" SG_ 947 VC_CMRA_GRDLNS_CSO 1;
BA_ "GenSigSNA" SG_ 947 VC_CMRA_GRDLNS_CSO "0h";
BA_ "GenSigSendType" SG_ 947 VC_ACC_DLY_CSO 5;
BA_ "GenSigCycleTime" SG_ 947 VC_ACC_DLY_CSO 2000;
BA_ "FlexKomSigStartValue" SG_ 947 VC_ACC_DLY_CSO "0300000000000000h";
BA_ "GenSigTimeout_IC" SG_ 947 VC_ACC_DLY_CSO 21000;
BA_ "FlexKomSID" SG_ 947 VC_ACC_DLY_CSO 2006;
BA_ "FlexKomSigStartPos" SG_ 947 VC_ACC_DLY_CSO 7;
BA_ "FlexKomSigLaenge" SG_ 947 VC_ACC_DLY_CSO 64;
BA_ "FlexKomSigName" SG_ 947 VC_ACC_DLY_CSO "VehCfgCSM1_Pkt";
BA_ "FlexKomComment" SG_ 947 VC_ACC_DLY_CSO "Vehicle configuration - customer settings menu 1 P";
BA_ "FlexKomIsMotorola" SG_ 947 VC_ACC_DLY_CSO 1;
BA_ "GenSigSNA" SG_ 947 VC_ACC_DLY_CSO "0h";
BA_ "GenSigSendType" SG_ 947 VC_AFLS_CSO 5;
BA_ "GenSigCycleTime" SG_ 947 VC_AFLS_CSO 2000;
BA_ "FlexKomSigStartValue" SG_ 947 VC_AFLS_CSO "0300000000000000h";
BA_ "GenSigTimeout_IC" SG_ 947 VC_AFLS_CSO 21000;
BA_ "FlexKomSID" SG_ 947 VC_AFLS_CSO 2006;
BA_ "FlexKomSigStartPos" SG_ 947 VC_AFLS_CSO 7;
BA_ "FlexKomSigLaenge" SG_ 947 VC_AFLS_CSO 64;
BA_ "FlexKomSigName" SG_ 947 VC_AFLS_CSO "VehCfgCSM1_Pkt";
BA_ "FlexKomComment" SG_ 947 VC_AFLS_CSO "Vehicle configuration - customer settings menu 1 P";
BA_ "FlexKomIsMotorola" SG_ 947 VC_AFLS_CSO 1;
BA_ "GenSigSNA" SG_ 947 VC_AFLS_CSO "0h";
BA_ "GenSigSendType" SG_ 947 VC_AMB_DMR_CSO 5;
BA_ "GenSigCycleTime" SG_ 947 VC_AMB_DMR_CSO 2000;
BA_ "FlexKomSigStartValue" SG_ 947 VC_AMB_DMR_CSO "0300000000000000h";
BA_ "GenSigTimeout_IC" SG_ 947 VC_AMB_DMR_CSO 21000;
BA_ "FlexKomSID" SG_ 947 VC_AMB_DMR_CSO 2006;
BA_ "FlexKomSigStartPos" SG_ 947 VC_AMB_DMR_CSO 7;
BA_ "FlexKomSigLaenge" SG_ 947 VC_AMB_DMR_CSO 64;
BA_ "FlexKomSigName" SG_ 947 VC_AMB_DMR_CSO "VehCfgCSM1_Pkt";
BA_ "FlexKomComment" SG_ 947 VC_AMB_DMR_CSO "Vehicle configuration - customer settings menu 1 P";
BA_ "FlexKomIsMotorola" SG_ 947 VC_AMB_DMR_CSO 1;
BA_ "GenSigSNA" SG_ 947 VC_AMB_DMR_CSO "0h";
BA_ "GenSigSendType" SG_ 947 VC_ASCM_TJ_CSO 5;
BA_ "GenSigCycleTime" SG_ 947 VC_ASCM_TJ_CSO 2000;
BA_ "FlexKomSigStartValue" SG_ 947 VC_ASCM_TJ_CSO "0300000000000000h";
BA_ "GenSigTimeout_IC" SG_ 947 VC_ASCM_TJ_CSO 21000;
BA_ "FlexKomSID" SG_ 947 VC_ASCM_TJ_CSO 2006;
BA_ "FlexKomSigStartPos" SG_ 947 VC_ASCM_TJ_CSO 7;
BA_ "FlexKomSigLaenge" SG_ 947 VC_ASCM_TJ_CSO 64;
BA_ "FlexKomSigName" SG_ 947 VC_ASCM_TJ_CSO "VehCfgCSM1_Pkt";
BA_ "FlexKomComment" SG_ 947 VC_ASCM_TJ_CSO "Vehicle configuration - customer settings menu 1 P";
BA_ "FlexKomIsMotorola" SG_ 947 VC_ASCM_TJ_CSO 1;
BA_ "GenSigSNA" SG_ 947 VC_ASCM_TJ_CSO "0h";
BA_ "GenSigSendType" SG_ 947 VC_ASCM_WRN_CSO 5;
BA_ "GenSigCycleTime" SG_ 947 VC_ASCM_WRN_CSO 2000;
BA_ "FlexKomSigStartValue" SG_ 947 VC_ASCM_WRN_CSO "0300000000000000h";
BA_ "GenSigTimeout_IC" SG_ 947 VC_ASCM_WRN_CSO 21000;
BA_ "FlexKomSID" SG_ 947 VC_ASCM_WRN_CSO 2006;
BA_ "FlexKomSigStartPos" SG_ 947 VC_ASCM_WRN_CSO 7;
BA_ "FlexKomSigLaenge" SG_ 947 VC_ASCM_WRN_CSO 64;
BA_ "FlexKomSigName" SG_ 947 VC_ASCM_WRN_CSO "VehCfgCSM1_Pkt";
BA_ "FlexKomComment" SG_ 947 VC_ASCM_WRN_CSO "Vehicle configuration - customer settings menu 1 P";
BA_ "FlexKomIsMotorola" SG_ 947 VC_ASCM_WRN_CSO 1;
BA_ "GenSigSNA" SG_ 947 VC_ASCM_WRN_CSO "0h";
BA_ "GenSigSendType" SG_ 947 VC_AUTO_AERO_CSO 5;
BA_ "GenSigCycleTime" SG_ 947 VC_AUTO_AERO_CSO 2000;
BA_ "FlexKomSigStartValue" SG_ 947 VC_AUTO_AERO_CSO "0300000000000000h";
BA_ "GenSigTimeout_IC" SG_ 947 VC_AUTO_AERO_CSO 21000;
BA_ "FlexKomSID" SG_ 947 VC_AUTO_AERO_CSO 2006;
BA_ "FlexKomSigStartPos" SG_ 947 VC_AUTO_AERO_CSO 7;
BA_ "FlexKomSigLaenge" SG_ 947 VC_AUTO_AERO_CSO 64;
BA_ "FlexKomSigName" SG_ 947 VC_AUTO_AERO_CSO "VehCfgCSM1_Pkt";
BA_ "FlexKomComment" SG_ 947 VC_AUTO_AERO_CSO "Vehicle configuration - customer settings menu 1 P";
BA_ "FlexKomIsMotorola" SG_ 947 VC_AUTO_AERO_CSO 1;
BA_ "GenSigSNA" SG_ 947 VC_AUTO_AERO_CSO "0h";
BA_ "GenSigSendType" SG_ 947 VC_AUTO_HB_CSO 5;
BA_ "GenSigCycleTime" SG_ 947 VC_AUTO_HB_CSO 2000;
BA_ "FlexKomSigStartValue" SG_ 947 VC_AUTO_HB_CSO "0300000000000000h";
BA_ "GenSigTimeout_IC" SG_ 947 VC_AUTO_HB_CSO 21000;
BA_ "FlexKomSID" SG_ 947 VC_AUTO_HB_CSO 2006;
BA_ "FlexKomSigStartPos" SG_ 947 VC_AUTO_HB_CSO 7;
BA_ "FlexKomSigLaenge" SG_ 947 VC_AUTO_HB_CSO 64;
BA_ "FlexKomSigName" SG_ 947 VC_AUTO_HB_CSO "VehCfgCSM1_Pkt";
BA_ "FlexKomComment" SG_ 947 VC_AUTO_HB_CSO "Vehicle configuration - customer settings menu 1 P";
BA_ "FlexKomIsMotorola" SG_ 947 VC_AUTO_HB_CSO 1;
BA_ "GenSigSNA" SG_ 947 VC_AUTO_HB_CSO "0h";
BA_ "GenSigSendType" SG_ 947 VC_AUTO_PRK_CSO 5;
BA_ "GenSigCycleTime" SG_ 947 VC_AUTO_PRK_CSO 2000;
BA_ "FlexKomSigStartValue" SG_ 947 VC_AUTO_PRK_CSO "0300000000000000h";
BA_ "GenSigTimeout_IC" SG_ 947 VC_AUTO_PRK_CSO 21000;
BA_ "FlexKomSID" SG_ 947 VC_AUTO_PRK_CSO 2006;
BA_ "FlexKomSigStartPos" SG_ 947 VC_AUTO_PRK_CSO 7;
BA_ "FlexKomSigLaenge" SG_ 947 VC_AUTO_PRK_CSO 64;
BA_ "FlexKomSigName" SG_ 947 VC_AUTO_PRK_CSO "VehCfgCSM1_Pkt";
BA_ "FlexKomComment" SG_ 947 VC_AUTO_PRK_CSO "Vehicle configuration - customer settings menu 1 P";
BA_ "FlexKomIsMotorola" SG_ 947 VC_AUTO_PRK_CSO 1;
BA_ "GenSigSNA" SG_ 947 VC_AUTO_PRK_CSO "0h";
BA_ "GenSigSendType" SG_ 947 VC_BLIND_SPOT_CSO 5;
BA_ "GenSigCycleTime" SG_ 947 VC_BLIND_SPOT_CSO 2000;
BA_ "FlexKomSigStartValue" SG_ 947 VC_BLIND_SPOT_CSO "0300000000000000h";
BA_ "GenSigTimeout_IC" SG_ 947 VC_BLIND_SPOT_CSO 21000;
BA_ "FlexKomSID" SG_ 947 VC_BLIND_SPOT_CSO 2006;
BA_ "FlexKomSigStartPos" SG_ 947 VC_BLIND_SPOT_CSO 7;
BA_ "FlexKomSigLaenge" SG_ 947 VC_BLIND_SPOT_CSO 64;
BA_ "FlexKomSigName" SG_ 947 VC_BLIND_SPOT_CSO "VehCfgCSM1_Pkt";
BA_ "FlexKomComment" SG_ 947 VC_BLIND_SPOT_CSO "Vehicle configuration - customer settings menu 1 P";
BA_ "FlexKomIsMotorola" SG_ 947 VC_BLIND_SPOT_CSO 1;
BA_ "GenSigSNA" SG_ 947 VC_BLIND_SPOT_CSO "0h";
BA_ "GenSigSendType" SG_ 947 VC_CAPACITY_CSO 5;
BA_ "GenSigCycleTime" SG_ 947 VC_CAPACITY_CSO 2000;
BA_ "FlexKomSigStartValue" SG_ 947 VC_CAPACITY_CSO "0300000000000000h";
BA_ "GenSigTimeout_IC" SG_ 947 VC_CAPACITY_CSO 21000;
BA_ "FlexKomSID" SG_ 947 VC_CAPACITY_CSO 2006;
BA_ "FlexKomSigStartPos" SG_ 947 VC_CAPACITY_CSO 7;
BA_ "FlexKomSigLaenge" SG_ 947 VC_CAPACITY_CSO 64;
BA_ "FlexKomSigName" SG_ 947 VC_CAPACITY_CSO "VehCfgCSM1_Pkt";
BA_ "FlexKomComment" SG_ 947 VC_CAPACITY_CSO "Vehicle configuration - customer settings menu 1 P";
BA_ "FlexKomIsMotorola" SG_ 947 VC_CAPACITY_CSO 1;
BA_ "GenSigSNA" SG_ 947 VC_CAPACITY_CSO "0h";
BA_ "GenSigSendType" SG_ 947 VC_CLK_DSP_CSO 5;
BA_ "GenSigCycleTime" SG_ 947 VC_CLK_DSP_CSO 2000;
BA_ "FlexKomSigStartValue" SG_ 947 VC_CLK_DSP_CSO "0300000000000000h";
BA_ "GenSigTimeout_IC" SG_ 947 VC_CLK_DSP_CSO 21000;
BA_ "FlexKomSID" SG_ 947 VC_CLK_DSP_CSO 2006;
BA_ "FlexKomSigStartPos" SG_ 947 VC_CLK_DSP_CSO 7;
BA_ "FlexKomSigLaenge" SG_ 947 VC_CLK_DSP_CSO 64;
BA_ "FlexKomSigName" SG_ 947 VC_CLK_DSP_CSO "VehCfgCSM1_Pkt";
BA_ "FlexKomComment" SG_ 947 VC_CLK_DSP_CSO "Vehicle configuration - customer settings menu 1 P";
BA_ "FlexKomIsMotorola" SG_ 947 VC_CLK_DSP_CSO 1;
BA_ "GenSigSNA" SG_ 947 VC_CLK_DSP_CSO "0h";
BA_ "GenSigSendType" SG_ 947 VC_CMP_CAL_CSO 5;
BA_ "GenSigCycleTime" SG_ 947 VC_CMP_CAL_CSO 2000;
BA_ "FlexKomSigStartValue" SG_ 947 VC_CMP_CAL_CSO "0300000000000000h";
BA_ "GenSigTimeout_IC" SG_ 947 VC_CMP_CAL_CSO 21000;
BA_ "FlexKomSID" SG_ 947 VC_CMP_CAL_CSO 2006;
BA_ "FlexKomSigStartPos" SG_ 947 VC_CMP_CAL_CSO 7;
BA_ "FlexKomSigLaenge" SG_ 947 VC_CMP_CAL_CSO 64;
BA_ "FlexKomSigName" SG_ 947 VC_CMP_CAL_CSO "VehCfgCSM1_Pkt";
BA_ "FlexKomComment" SG_ 947 VC_CMP_CAL_CSO "Vehicle configuration - customer settings menu 1 P";
BA_ "FlexKomIsMotorola" SG_ 947 VC_CMP_CAL_CSO 1;
BA_ "GenSigSNA" SG_ 947 VC_CMP_CAL_CSO "0h";
BA_ "GenSigSendType" SG_ 947 VC_CMP_VAR_CSO 5;
BA_ "GenSigCycleTime" SG_ 947 VC_CMP_VAR_CSO 2000;
BA_ "FlexKomSigStartValue" SG_ 947 VC_CMP_VAR_CSO "0300000000000000h";
BA_ "GenSigTimeout_IC" SG_ 947 VC_CMP_VAR_CSO 21000;
BA_ "FlexKomSID" SG_ 947 VC_CMP_VAR_CSO 2006;
BA_ "FlexKomSigStartPos" SG_ 947 VC_CMP_VAR_CSO 7;
BA_ "FlexKomSigLaenge" SG_ 947 VC_CMP_VAR_CSO 64;
BA_ "FlexKomSigName" SG_ 947 VC_CMP_VAR_CSO "VehCfgCSM1_Pkt";
BA_ "FlexKomComment" SG_ 947 VC_CMP_VAR_CSO "Vehicle configuration - customer settings menu 1 P";
BA_ "FlexKomIsMotorola" SG_ 947 VC_CMP_VAR_CSO 1;
BA_ "GenSigSNA" SG_ 947 VC_CMP_VAR_CSO "0h";
BA_ "GenSigSendType" SG_ 947 VC_CONS_CSO 5;
BA_ "GenSigCycleTime" SG_ 947 VC_CONS_CSO 2000;
BA_ "FlexKomSigStartValue" SG_ 947 VC_CONS_CSO "0300000000000000h";
BA_ "GenSigTimeout_IC" SG_ 947 VC_CONS_CSO 21000;
BA_ "FlexKomSID" SG_ 947 VC_CONS_CSO 2006;
BA_ "FlexKomSigStartPos" SG_ 947 VC_CONS_CSO 7;
BA_ "FlexKomSigLaenge" SG_ 947 VC_CONS_CSO 64;
BA_ "FlexKomSigName" SG_ 947 VC_CONS_CSO "VehCfgCSM1_Pkt";
BA_ "FlexKomComment" SG_ 947 VC_CONS_CSO "Vehicle configuration - customer settings menu 1 P";
BA_ "FlexKomIsMotorola" SG_ 947 VC_CONS_CSO 1;
BA_ "GenSigSNA" SG_ 947 VC_CONS_CSO "0h";
BA_ "GenSigSendType" SG_ 947 VC_DISTANCE_CSO 5;
BA_ "GenSigCycleTime" SG_ 947 VC_DISTANCE_CSO 2000;
BA_ "FlexKomSigStartValue" SG_ 947 VC_DISTANCE_CSO "0300000000000000h";
BA_ "GenSigTimeout_IC" SG_ 947 VC_DISTANCE_CSO 21000;
BA_ "FlexKomSID" SG_ 947 VC_DISTANCE_CSO 2006;
BA_ "FlexKomSigStartPos" SG_ 947 VC_DISTANCE_CSO 7;
BA_ "FlexKomSigLaenge" SG_ 947 VC_DISTANCE_CSO 64;
BA_ "FlexKomSigName" SG_ 947 VC_DISTANCE_CSO "VehCfgCSM1_Pkt";
BA_ "FlexKomComment" SG_ 947 VC_DISTANCE_CSO "Vehicle configuration - customer settings menu 1 P";
BA_ "FlexKomIsMotorola" SG_ 947 VC_DISTANCE_CSO 1;
BA_ "GenSigSNA" SG_ 947 VC_DISTANCE_CSO "0h";
BA_ "GenSigSendType" SG_ 947 VC_DR_LK_CSO 5;
BA_ "GenSigCycleTime" SG_ 947 VC_DR_LK_CSO 2000;
BA_ "FlexKomSigStartValue" SG_ 947 VC_DR_LK_CSO "0300000000000000h";
BA_ "GenSigTimeout_IC" SG_ 947 VC_DR_LK_CSO 21000;
BA_ "FlexKomSID" SG_ 947 VC_DR_LK_CSO 2006;
BA_ "FlexKomSigStartPos" SG_ 947 VC_DR_LK_CSO 7;
BA_ "FlexKomSigLaenge" SG_ 947 VC_DR_LK_CSO 64;
BA_ "FlexKomSigName" SG_ 947 VC_DR_LK_CSO "VehCfgCSM1_Pkt";
BA_ "FlexKomComment" SG_ 947 VC_DR_LK_CSO "Vehicle configuration - customer settings menu 1 P";
BA_ "FlexKomIsMotorola" SG_ 947 VC_DR_LK_CSO 1;
BA_ "GenSigSNA" SG_ 947 VC_DR_LK_CSO "0h";
BA_ "GenSigSendType" SG_ 947 VC_DR_UNLK_CSO 5;
BA_ "GenSigCycleTime" SG_ 947 VC_DR_UNLK_CSO 2000;
BA_ "FlexKomSigStartValue" SG_ 947 VC_DR_UNLK_CSO "0300000000000000h";
BA_ "GenSigTimeout_IC" SG_ 947 VC_DR_UNLK_CSO 21000;
BA_ "FlexKomSID" SG_ 947 VC_DR_UNLK_CSO 2006;
BA_ "FlexKomSigStartPos" SG_ 947 VC_DR_UNLK_CSO 7;
BA_ "FlexKomSigLaenge" SG_ 947 VC_DR_UNLK_CSO 64;
BA_ "FlexKomSigName" SG_ 947 VC_DR_UNLK_CSO "VehCfgCSM1_Pkt";
BA_ "FlexKomComment" SG_ 947 VC_DR_UNLK_CSO "Vehicle configuration - customer settings menu 1 P";
BA_ "FlexKomIsMotorola" SG_ 947 VC_DR_UNLK_CSO 1;
BA_ "GenSigSNA" SG_ 947 VC_DR_UNLK_CSO "0h";
BA_ "GenSigSendType" SG_ 947 VC_DRL_CSO 5;
BA_ "GenSigCycleTime" SG_ 947 VC_DRL_CSO 2000;
BA_ "FlexKomSigStartValue" SG_ 947 VC_DRL_CSO "0300000000000000h";
BA_ "GenSigTimeout_IC" SG_ 947 VC_DRL_CSO 21000;
BA_ "FlexKomSID" SG_ 947 VC_DRL_CSO 2006;
BA_ "FlexKomSigStartPos" SG_ 947 VC_DRL_CSO 7;
BA_ "FlexKomSigLaenge" SG_ 947 VC_DRL_CSO 64;
BA_ "FlexKomSigName" SG_ 947 VC_DRL_CSO "VehCfgCSM1_Pkt";
BA_ "FlexKomComment" SG_ 947 VC_DRL_CSO "Vehicle configuration - customer settings menu 1 P";
BA_ "FlexKomIsMotorola" SG_ 947 VC_DRL_CSO 1;
BA_ "GenSigSNA" SG_ 947 VC_DRL_CSO "0h";
BA_ "GenSigSendType" SG_ 947 VC_EASY_EXIT_CSO 5;
BA_ "GenSigCycleTime" SG_ 947 VC_EASY_EXIT_CSO 2000;
BA_ "FlexKomSigStartValue" SG_ 947 VC_EASY_EXIT_CSO "0300000000000000h";
BA_ "GenSigTimeout_IC" SG_ 947 VC_EASY_EXIT_CSO 21000;
BA_ "FlexKomSID" SG_ 947 VC_EASY_EXIT_CSO 2006;
BA_ "FlexKomSigStartPos" SG_ 947 VC_EASY_EXIT_CSO 7;
BA_ "FlexKomSigLaenge" SG_ 947 VC_EASY_EXIT_CSO 64;
BA_ "FlexKomSigName" SG_ 947 VC_EASY_EXIT_CSO "VehCfgCSM1_Pkt";
BA_ "FlexKomComment" SG_ 947 VC_EASY_EXIT_CSO "Vehicle configuration - customer settings menu 1 P";
BA_ "FlexKomIsMotorola" SG_ 947 VC_EASY_EXIT_CSO 1;
BA_ "GenSigSNA" SG_ 947 VC_EASY_EXIT_CSO "0h";
BA_ "GenSigSendType" SG_ 947 VC_ENTRY_EXIT_CSO 5;
BA_ "GenSigCycleTime" SG_ 947 VC_ENTRY_EXIT_CSO 2000;
BA_ "FlexKomSigStartValue" SG_ 947 VC_ENTRY_EXIT_CSO "0300000000000000h";
BA_ "GenSigTimeout_IC" SG_ 947 VC_ENTRY_EXIT_CSO 21000;
BA_ "FlexKomSID" SG_ 947 VC_ENTRY_EXIT_CSO 2006;
BA_ "FlexKomSigStartPos" SG_ 947 VC_ENTRY_EXIT_CSO 7;
BA_ "FlexKomSigLaenge" SG_ 947 VC_ENTRY_EXIT_CSO 64;
BA_ "FlexKomSigName" SG_ 947 VC_ENTRY_EXIT_CSO "VehCfgCSM1_Pkt";
BA_ "FlexKomComment" SG_ 947 VC_ENTRY_EXIT_CSO "Vehicle configuration - customer settings menu 1 P";
BA_ "FlexKomIsMotorola" SG_ 947 VC_ENTRY_EXIT_CSO 1;
BA_ "GenSigSNA" SG_ 947 VC_ENTRY_EXIT_CSO "0h";
BA_ "GenSigSendType" SG_ 947 VC_EPB_SERV_CSO 5;
BA_ "GenSigCycleTime" SG_ 947 VC_EPB_SERV_CSO 2000;
BA_ "FlexKomSigStartValue" SG_ 947 VC_EPB_SERV_CSO "0300000000000000h";
BA_ "GenSigTimeout_IC" SG_ 947 VC_EPB_SERV_CSO 21000;
BA_ "FlexKomSID" SG_ 947 VC_EPB_SERV_CSO 2006;
BA_ "FlexKomSigStartPos" SG_ 947 VC_EPB_SERV_CSO 7;
BA_ "FlexKomSigLaenge" SG_ 947 VC_EPB_SERV_CSO 64;
BA_ "FlexKomSigName" SG_ 947 VC_EPB_SERV_CSO "VehCfgCSM1_Pkt";
BA_ "FlexKomComment" SG_ 947 VC_EPB_SERV_CSO "Vehicle configuration - customer settings menu 1 P";
BA_ "FlexKomIsMotorola" SG_ 947 VC_EPB_SERV_CSO 1;
BA_ "GenSigSNA" SG_ 947 VC_EPB_SERV_CSO "0h";
BA_ "GenSigSendType" SG_ 947 VC_FLSH_LMP_LK_CSO 5;
BA_ "GenSigCycleTime" SG_ 947 VC_FLSH_LMP_LK_CSO 2000;
BA_ "FlexKomSigStartValue" SG_ 947 VC_FLSH_LMP_LK_CSO "0300000000000000h";
BA_ "GenSigTimeout_IC" SG_ 947 VC_FLSH_LMP_LK_CSO 21000;
BA_ "FlexKomSID" SG_ 947 VC_FLSH_LMP_LK_CSO 2006;
BA_ "FlexKomSigStartPos" SG_ 947 VC_FLSH_LMP_LK_CSO 7;
BA_ "FlexKomSigLaenge" SG_ 947 VC_FLSH_LMP_LK_CSO 64;
BA_ "FlexKomSigName" SG_ 947 VC_FLSH_LMP_LK_CSO "VehCfgCSM1_Pkt";
BA_ "FlexKomComment" SG_ 947 VC_FLSH_LMP_LK_CSO "Vehicle configuration - customer settings menu 1 P";
BA_ "FlexKomIsMotorola" SG_ 947 VC_FLSH_LMP_LK_CSO 1;
BA_ "GenSigSNA" SG_ 947 VC_FLSH_LMP_LK_CSO "0h";
BA_ "GenSigSendType" SG_ 947 VC_HL_DRP_CSO 5;
BA_ "GenSigCycleTime" SG_ 947 VC_HL_DRP_CSO 2000;
BA_ "FlexKomSigStartValue" SG_ 947 VC_HL_DRP_CSO "0300000000000000h";
BA_ "GenSigTimeout_IC" SG_ 947 VC_HL_DRP_CSO 21000;
BA_ "FlexKomSID" SG_ 947 VC_HL_DRP_CSO 2006;
BA_ "FlexKomSigStartPos" SG_ 947 VC_HL_DRP_CSO 7;
BA_ "FlexKomSigLaenge" SG_ 947 VC_HL_DRP_CSO 64;
BA_ "FlexKomSigName" SG_ 947 VC_HL_DRP_CSO "VehCfgCSM1_Pkt";
BA_ "FlexKomComment" SG_ 947 VC_HL_DRP_CSO "Vehicle configuration - customer settings menu 1 P";
BA_ "FlexKomIsMotorola" SG_ 947 VC_HL_DRP_CSO 1;
BA_ "GenSigSNA" SG_ 947 VC_HL_DRP_CSO "0h";
BA_ "GenSigSendType" SG_ 947 VC_HL_OFF_DLY_CSO 5;
BA_ "GenSigCycleTime" SG_ 947 VC_HL_OFF_DLY_CSO 2000;
BA_ "FlexKomSigStartValue" SG_ 947 VC_HL_OFF_DLY_CSO "0300000000000000h";
BA_ "GenSigTimeout_IC" SG_ 947 VC_HL_OFF_DLY_CSO 21000;
BA_ "FlexKomSID" SG_ 947 VC_HL_OFF_DLY_CSO 2006;
BA_ "FlexKomSigStartPos" SG_ 947 VC_HL_OFF_DLY_CSO 7;
BA_ "FlexKomSigLaenge" SG_ 947 VC_HL_OFF_DLY_CSO 64;
BA_ "FlexKomSigName" SG_ 947 VC_HL_OFF_DLY_CSO "VehCfgCSM1_Pkt";
BA_ "FlexKomComment" SG_ 947 VC_HL_OFF_DLY_CSO "Vehicle configuration - customer settings menu 1 P";
BA_ "FlexKomIsMotorola" SG_ 947 VC_HL_OFF_DLY_CSO 1;
BA_ "GenSigSNA" SG_ 947 VC_HL_OFF_DLY_CSO "0h";
BA_ "GenSigSendType" SG_ 947 VC_HL_WPR_CSO 5;
BA_ "GenSigCycleTime" SG_ 947 VC_HL_WPR_CSO 2000;
BA_ "FlexKomSigStartValue" SG_ 947 VC_HL_WPR_CSO "0300000000000000h";
BA_ "GenSigTimeout_IC" SG_ 947 VC_HL_WPR_CSO 21000;
BA_ "FlexKomSID" SG_ 947 VC_HL_WPR_CSO 2006;
BA_ "FlexKomSigStartPos" SG_ 947 VC_HL_WPR_CSO 7;
BA_ "FlexKomSigLaenge" SG_ 947 VC_HL_WPR_CSO 64;
BA_ "FlexKomSigName" SG_ 947 VC_HL_WPR_CSO "VehCfgCSM1_Pkt";
BA_ "FlexKomComment" SG_ 947 VC_HL_WPR_CSO "Vehicle configuration - customer settings menu 1 P";
BA_ "FlexKomIsMotorola" SG_ 947 VC_HL_WPR_CSO 1;
BA_ "GenSigSNA" SG_ 947 VC_HL_WPR_CSO "0h";
BA_ "GenSigSendType" SG_ 947 VC_HSA_CSO 5;
BA_ "GenSigCycleTime" SG_ 947 VC_HSA_CSO 2000;
BA_ "FlexKomSigStartValue" SG_ 947 VC_HSA_CSO "0300000000000000h";
BA_ "GenSigTimeout_IC" SG_ 947 VC_HSA_CSO 21000;
BA_ "FlexKomSID" SG_ 947 VC_HSA_CSO 2006;
BA_ "FlexKomSigStartPos" SG_ 947 VC_HSA_CSO 7;
BA_ "FlexKomSigLaenge" SG_ 947 VC_HSA_CSO 64;
BA_ "FlexKomSigName" SG_ 947 VC_HSA_CSO "VehCfgCSM1_Pkt";
BA_ "FlexKomComment" SG_ 947 VC_HSA_CSO "Vehicle configuration - customer settings menu 1 P";
BA_ "FlexKomIsMotorola" SG_ 947 VC_HSA_CSO 1;
BA_ "GenSigSNA" SG_ 947 VC_HSA_CSO "0h";
BA_ "GenSigSendType" SG_ 947 VC_ILL_APPRCH_CSO 5;
BA_ "GenSigCycleTime" SG_ 947 VC_ILL_APPRCH_CSO 2000;
BA_ "FlexKomSigStartValue" SG_ 947 VC_ILL_APPRCH_CSO "0300000000000000h";
BA_ "GenSigTimeout_IC" SG_ 947 VC_ILL_APPRCH_CSO 21000;
BA_ "FlexKomSID" SG_ 947 VC_ILL_APPRCH_CSO 2006;
BA_ "FlexKomSigStartPos" SG_ 947 VC_ILL_APPRCH_CSO 7;
BA_ "FlexKomSigLaenge" SG_ 947 VC_ILL_APPRCH_CSO 64;
BA_ "FlexKomSigName" SG_ 947 VC_ILL_APPRCH_CSO "VehCfgCSM1_Pkt";
BA_ "FlexKomComment" SG_ 947 VC_ILL_APPRCH_CSO "Vehicle configuration - customer settings menu 1 P";
BA_ "FlexKomIsMotorola" SG_ 947 VC_ILL_APPRCH_CSO 1;
BA_ "GenSigSNA" SG_ 947 VC_ILL_APPRCH_CSO "0h";
BA_ "GenSigSendType" SG_ 947 VC_LDW_TRQ_CSO 5;
BA_ "GenSigCycleTime" SG_ 947 VC_LDW_TRQ_CSO 2000;
BA_ "FlexKomSigStartValue" SG_ 947 VC_LDW_TRQ_CSO "0300000000000000h";
BA_ "GenSigTimeout_IC" SG_ 947 VC_LDW_TRQ_CSO 21000;
BA_ "FlexKomSID" SG_ 947 VC_LDW_TRQ_CSO 2006;
BA_ "FlexKomSigStartPos" SG_ 947 VC_LDW_TRQ_CSO 7;
BA_ "FlexKomSigLaenge" SG_ 947 VC_LDW_TRQ_CSO 64;
BA_ "FlexKomSigName" SG_ 947 VC_LDW_TRQ_CSO "VehCfgCSM1_Pkt";
BA_ "FlexKomComment" SG_ 947 VC_LDW_TRQ_CSO "Vehicle configuration - customer settings menu 1 P";
BA_ "FlexKomIsMotorola" SG_ 947 VC_LDW_TRQ_CSO 1;
BA_ "GenSigSNA" SG_ 947 VC_LDW_TRQ_CSO "0h";
BA_ "GenSigSendType" SG_ 947 VC_LDW_WRN_CSO 5;
BA_ "GenSigCycleTime" SG_ 947 VC_LDW_WRN_CSO 2000;
BA_ "FlexKomSigStartValue" SG_ 947 VC_LDW_WRN_CSO "0300000000000000h";
BA_ "GenSigTimeout_IC" SG_ 947 VC_LDW_WRN_CSO 21000;
BA_ "FlexKomSID" SG_ 947 VC_LDW_WRN_CSO 2006;
BA_ "FlexKomSigStartPos" SG_ 947 VC_LDW_WRN_CSO 7;
BA_ "FlexKomSigLaenge" SG_ 947 VC_LDW_WRN_CSO 64;
BA_ "FlexKomSigName" SG_ 947 VC_LDW_WRN_CSO "VehCfgCSM1_Pkt";
BA_ "FlexKomComment" SG_ 947 VC_LDW_WRN_CSO "Vehicle configuration - customer settings menu 1 P";
BA_ "FlexKomIsMotorola" SG_ 947 VC_LDW_WRN_CSO 1;
BA_ "GenSigSNA" SG_ 947 VC_LDW_WRN_CSO "0h";
BA_ "GenSigSendType" SG_ 947 VC_LGHT_RMT_LWR_CSO 5;
BA_ "GenSigCycleTime" SG_ 947 VC_LGHT_RMT_LWR_CSO 2000;
BA_ "FlexKomSigStartValue" SG_ 947 VC_LGHT_RMT_LWR_CSO "0300000000000000h";
BA_ "GenSigTimeout_IC" SG_ 947 VC_LGHT_RMT_LWR_CSO 21000;
BA_ "FlexKomSID" SG_ 947 VC_LGHT_RMT_LWR_CSO 2006;
BA_ "FlexKomSigStartPos" SG_ 947 VC_LGHT_RMT_LWR_CSO 7;
BA_ "FlexKomSigLaenge" SG_ 947 VC_LGHT_RMT_LWR_CSO 64;
BA_ "FlexKomSigName" SG_ 947 VC_LGHT_RMT_LWR_CSO "VehCfgCSM1_Pkt";
BA_ "FlexKomComment" SG_ 947 VC_LGHT_RMT_LWR_CSO "Vehicle configuration - customer settings menu 1 P";
BA_ "FlexKomIsMotorola" SG_ 947 VC_LGHT_RMT_LWR_CSO 1;
BA_ "GenSigSNA" SG_ 947 VC_LGHT_RMT_LWR_CSO "0h";
BA_ "GenSigSendType" SG_ 947 VC_NAV_TRN_CSO 5;
BA_ "GenSigCycleTime" SG_ 947 VC_NAV_TRN_CSO 2000;
BA_ "FlexKomSigStartValue" SG_ 947 VC_NAV_TRN_CSO "0300000000000000h";
BA_ "GenSigTimeout_IC" SG_ 947 VC_NAV_TRN_CSO 21000;
BA_ "FlexKomSID" SG_ 947 VC_NAV_TRN_CSO 2006;
BA_ "FlexKomSigStartPos" SG_ 947 VC_NAV_TRN_CSO 7;
BA_ "FlexKomSigLaenge" SG_ 947 VC_NAV_TRN_CSO 64;
BA_ "FlexKomSigName" SG_ 947 VC_NAV_TRN_CSO "VehCfgCSM1_Pkt";
BA_ "FlexKomComment" SG_ 947 VC_NAV_TRN_CSO "Vehicle configuration - customer settings menu 1 P";
BA_ "FlexKomIsMotorola" SG_ 947 VC_NAV_TRN_CSO 1;
BA_ "GenSigSNA" SG_ 947 VC_NAV_TRN_CSO "0h";
BA_ "GenSigSendType" SG_ 947 VC_PE_CSO 5;
BA_ "GenSigCycleTime" SG_ 947 VC_PE_CSO 2000;
BA_ "FlexKomSigStartValue" SG_ 947 VC_PE_CSO "0300000000000000h";
BA_ "GenSigTimeout_IC" SG_ 947 VC_PE_CSO 21000;
BA_ "FlexKomSID" SG_ 947 VC_PE_CSO 2006;
BA_ "FlexKomSigStartPos" SG_ 947 VC_PE_CSO 7;
BA_ "FlexKomSigLaenge" SG_ 947 VC_PE_CSO 64;
BA_ "FlexKomSigName" SG_ 947 VC_PE_CSO "VehCfgCSM1_Pkt";
BA_ "FlexKomComment" SG_ 947 VC_PE_CSO "Vehicle configuration - customer settings menu 1 P";
BA_ "FlexKomIsMotorola" SG_ 947 VC_PE_CSO 1;
BA_ "GenSigSNA" SG_ 947 VC_PE_CSO "0h";
BA_ "GenSigSendType" SG_ 947 VC_PER_SHFT_ENBL_CSO 5;
BA_ "GenSigCycleTime" SG_ 947 VC_PER_SHFT_ENBL_CSO 2000;
BA_ "FlexKomSigStartValue" SG_ 947 VC_PER_SHFT_ENBL_CSO "0300000000000000h";
BA_ "GenSigTimeout_IC" SG_ 947 VC_PER_SHFT_ENBL_CSO 21000;
BA_ "FlexKomSID" SG_ 947 VC_PER_SHFT_ENBL_CSO 2006;
BA_ "FlexKomSigStartPos" SG_ 947 VC_PER_SHFT_ENBL_CSO 7;
BA_ "FlexKomSigLaenge" SG_ 947 VC_PER_SHFT_ENBL_CSO 64;
BA_ "FlexKomSigName" SG_ 947 VC_PER_SHFT_ENBL_CSO "VehCfgCSM1_Pkt";
BA_ "FlexKomComment" SG_ 947 VC_PER_SHFT_ENBL_CSO "Vehicle configuration - customer settings menu 1 P";
BA_ "FlexKomIsMotorola" SG_ 947 VC_PER_SHFT_ENBL_CSO 1;
BA_ "GenSigSNA" SG_ 947 VC_PER_SHFT_ENBL_CSO "0h";
BA_ "GenSigSendType" SG_ 947 VC_PER_SHFT_RPM_CSO 5;
BA_ "GenSigCycleTime" SG_ 947 VC_PER_SHFT_RPM_CSO 2000;
BA_ "FlexKomSigStartValue" SG_ 947 VC_PER_SHFT_RPM_CSO "0300000000000000h";
BA_ "GenSigTimeout_IC" SG_ 947 VC_PER_SHFT_RPM_CSO 21000;
BA_ "FlexKomSID" SG_ 947 VC_PER_SHFT_RPM_CSO 2006;
BA_ "FlexKomSigStartPos" SG_ 947 VC_PER_SHFT_RPM_CSO 7;
BA_ "FlexKomSigLaenge" SG_ 947 VC_PER_SHFT_RPM_CSO 64;
BA_ "FlexKomSigName" SG_ 947 VC_PER_SHFT_RPM_CSO "VehCfgCSM1_Pkt";
BA_ "FlexKomComment" SG_ 947 VC_PER_SHFT_RPM_CSO "Vehicle configuration - customer settings menu 1 P";
BA_ "FlexKomIsMotorola" SG_ 947 VC_PER_SHFT_RPM_CSO 1;
BA_ "GenSigSNA" SG_ 947 VC_PER_SHFT_RPM_CSO "0h";
BA_ "GenSigSendType" SG_ 947 VC_PLG_CHM_CSO 5;
BA_ "GenSigCycleTime" SG_ 947 VC_PLG_CHM_CSO 2000;
BA_ "FlexKomSigStartValue" SG_ 947 VC_PLG_CHM_CSO "0300000000000000h";
BA_ "GenSigTimeout_IC" SG_ 947 VC_PLG_CHM_CSO 21000;
BA_ "FlexKomSID" SG_ 947 VC_PLG_CHM_CSO 2006;
BA_ "FlexKomSigStartPos" SG_ 947 VC_PLG_CHM_CSO 7;
BA_ "FlexKomSigLaenge" SG_ 947 VC_PLG_CHM_CSO 64;
BA_ "FlexKomSigName" SG_ 947 VC_PLG_CHM_CSO "VehCfgCSM1_Pkt";
BA_ "FlexKomComment" SG_ 947 VC_PLG_CHM_CSO "Vehicle configuration - customer settings menu 1 P";
BA_ "FlexKomIsMotorola" SG_ 947 VC_PLG_CHM_CSO 1;
BA_ "GenSigSNA" SG_ 947 VC_PLG_CHM_CSO "0h";
BA_ "GenSigSendType" SG_ 947 VC_POWER_CSO 5;
BA_ "GenSigCycleTime" SG_ 947 VC_POWER_CSO 2000;
BA_ "FlexKomSigStartValue" SG_ 947 VC_POWER_CSO "0300000000000000h";
BA_ "GenSigTimeout_IC" SG_ 947 VC_POWER_CSO 21000;
BA_ "FlexKomSID" SG_ 947 VC_POWER_CSO 2006;
BA_ "FlexKomSigStartPos" SG_ 947 VC_POWER_CSO 7;
BA_ "FlexKomSigLaenge" SG_ 947 VC_POWER_CSO 64;
BA_ "FlexKomSigName" SG_ 947 VC_POWER_CSO "VehCfgCSM1_Pkt";
BA_ "FlexKomComment" SG_ 947 VC_POWER_CSO "Vehicle configuration - customer settings menu 1 P";
BA_ "FlexKomIsMotorola" SG_ 947 VC_POWER_CSO 1;
BA_ "GenSigSNA" SG_ 947 VC_POWER_CSO "0h";
BA_ "GenSigSendType" SG_ 947 VC_PRESSURE_CSO 5;
BA_ "GenSigCycleTime" SG_ 947 VC_PRESSURE_CSO 2000;
BA_ "FlexKomSigStartValue" SG_ 947 VC_PRESSURE_CSO "0300000000000000h";
BA_ "GenSigTimeout_IC" SG_ 947 VC_PRESSURE_CSO 21000;
BA_ "FlexKomSID" SG_ 947 VC_PRESSURE_CSO 2006;
BA_ "FlexKomSigStartPos" SG_ 947 VC_PRESSURE_CSO 7;
BA_ "FlexKomSigLaenge" SG_ 947 VC_PRESSURE_CSO 64;
BA_ "FlexKomSigName" SG_ 947 VC_PRESSURE_CSO "VehCfgCSM1_Pkt";
BA_ "FlexKomComment" SG_ 947 VC_PRESSURE_CSO "Vehicle configuration - customer settings menu 1 P";
BA_ "FlexKomIsMotorola" SG_ 947 VC_PRESSURE_CSO 1;
BA_ "GenSigSNA" SG_ 947 VC_PRESSURE_CSO "0h";
BA_ "GenSigSendType" SG_ 947 VC_PTO_CSO 5;
BA_ "GenSigCycleTime" SG_ 947 VC_PTO_CSO 2000;
BA_ "FlexKomSigStartValue" SG_ 947 VC_PTO_CSO "0300000000000000h";
BA_ "GenSigTimeout_IC" SG_ 947 VC_PTO_CSO 21000;
BA_ "FlexKomSID" SG_ 947 VC_PTO_CSO 2006;
BA_ "FlexKomSigStartPos" SG_ 947 VC_PTO_CSO 7;
BA_ "FlexKomSigLaenge" SG_ 947 VC_PTO_CSO 64;
BA_ "FlexKomSigName" SG_ 947 VC_PTO_CSO "VehCfgCSM1_Pkt";
BA_ "FlexKomComment" SG_ 947 VC_PTO_CSO "Vehicle configuration - customer settings menu 1 P";
BA_ "FlexKomIsMotorola" SG_ 947 VC_PTO_CSO 1;
BA_ "GenSigSNA" SG_ 947 VC_PTO_CSO "0h";
BA_ "GenSigSendType" SG_ 947 VC_RAIN_WPR_CSO 5;
BA_ "GenSigCycleTime" SG_ 947 VC_RAIN_WPR_CSO 2000;
BA_ "FlexKomSigStartValue" SG_ 947 VC_RAIN_WPR_CSO "0300000000000000h";
BA_ "GenSigTimeout_IC" SG_ 947 VC_RAIN_WPR_CSO 21000;
BA_ "FlexKomSID" SG_ 947 VC_RAIN_WPR_CSO 2006;
BA_ "FlexKomSigStartPos" SG_ 947 VC_RAIN_WPR_CSO 7;
BA_ "FlexKomSigLaenge" SG_ 947 VC_RAIN_WPR_CSO 64;
BA_ "FlexKomSigName" SG_ 947 VC_RAIN_WPR_CSO "VehCfgCSM1_Pkt";
BA_ "FlexKomComment" SG_ 947 VC_RAIN_WPR_CSO "Vehicle configuration - customer settings menu 1 P";
BA_ "FlexKomIsMotorola" SG_ 947 VC_RAIN_WPR_CSO 1;
BA_ "GenSigSNA" SG_ 947 VC_RAIN_WPR_CSO "0h";
BA_ "GenSigSendType" SG_ 947 VC_REAR_CMRA_CSO 5;
BA_ "GenSigCycleTime" SG_ 947 VC_REAR_CMRA_CSO 2000;
BA_ "FlexKomSigStartValue" SG_ 947 VC_REAR_CMRA_CSO "0300000000000000h";
BA_ "GenSigTimeout_IC" SG_ 947 VC_REAR_CMRA_CSO 21000;
BA_ "FlexKomSID" SG_ 947 VC_REAR_CMRA_CSO 2006;
BA_ "FlexKomSigStartPos" SG_ 947 VC_REAR_CMRA_CSO 7;
BA_ "FlexKomSigLaenge" SG_ 947 VC_REAR_CMRA_CSO 64;
BA_ "FlexKomSigName" SG_ 947 VC_REAR_CMRA_CSO "VehCfgCSM1_Pkt";
BA_ "FlexKomComment" SG_ 947 VC_REAR_CMRA_CSO "Vehicle configuration - customer settings menu 1 P";
BA_ "FlexKomIsMotorola" SG_ 947 VC_REAR_CMRA_CSO 1;
BA_ "GenSigSNA" SG_ 947 VC_REAR_CMRA_CSO "0h";
BA_ "GenSigSendType" SG_ 948 VC_VehCfgCSO2_Stat 5;
BA_ "GenSigCycleTime" SG_ 948 VC_VehCfgCSO2_Stat 2000;
BA_ "FlexKomSigStartValue" SG_ 948 VC_VehCfgCSO2_Stat "0300000000000000h";
BA_ "GenSigStartValue" SG_ 948 VC_VehCfgCSO2_Stat 3;
BA_ "GenSigTimeout_IC" SG_ 948 VC_VehCfgCSO2_Stat 21000;
BA_ "FlexKomSID" SG_ 948 VC_VehCfgCSO2_Stat 2007;
BA_ "FlexKomSigStartPos" SG_ 948 VC_VehCfgCSO2_Stat 7;
BA_ "FlexKomSigLaenge" SG_ 948 VC_VehCfgCSO2_Stat 64;
BA_ "FlexKomSigName" SG_ 948 VC_VehCfgCSO2_Stat "VehCfgCSM2_Pkt";
BA_ "FlexKomComment" SG_ 948 VC_VehCfgCSO2_Stat "Vehicle configuration - customer settings menu 2 P";
BA_ "FlexKomIsMotorola" SG_ 948 VC_VehCfgCSO2_Stat 1;
BA_ "GenSigSNA" SG_ 948 VC_VehCfgCSO2_Stat "3h";
BA_ "GenSigSendType" SG_ 948 VC_REAR_CMRA_DLY_CSO 5;
BA_ "GenSigCycleTime" SG_ 948 VC_REAR_CMRA_DLY_CSO 2000;
BA_ "FlexKomSigStartValue" SG_ 948 VC_REAR_CMRA_DLY_CSO "0300000000000000h";
BA_ "GenSigTimeout_IC" SG_ 948 VC_REAR_CMRA_DLY_CSO 21000;
BA_ "FlexKomSID" SG_ 948 VC_REAR_CMRA_DLY_CSO 2007;
BA_ "FlexKomSigStartPos" SG_ 948 VC_REAR_CMRA_DLY_CSO 7;
BA_ "FlexKomSigLaenge" SG_ 948 VC_REAR_CMRA_DLY_CSO 64;
BA_ "FlexKomSigName" SG_ 948 VC_REAR_CMRA_DLY_CSO "VehCfgCSM2_Pkt";
BA_ "FlexKomComment" SG_ 948 VC_REAR_CMRA_DLY_CSO "Vehicle configuration - customer settings menu 2 P";
BA_ "FlexKomIsMotorola" SG_ 948 VC_REAR_CMRA_DLY_CSO 1;
BA_ "GenSigSNA" SG_ 948 VC_REAR_CMRA_DLY_CSO "0h";
BA_ "GenSigSendType" SG_ 948 VC_RKE_MEM_CSO 5;
BA_ "GenSigCycleTime" SG_ 948 VC_RKE_MEM_CSO 2000;
BA_ "FlexKomSigStartValue" SG_ 948 VC_RKE_MEM_CSO "0300000000000000h";
BA_ "GenSigTimeout_IC" SG_ 948 VC_RKE_MEM_CSO 21000;
BA_ "FlexKomSID" SG_ 948 VC_RKE_MEM_CSO 2007;
BA_ "FlexKomSigStartPos" SG_ 948 VC_RKE_MEM_CSO 7;
BA_ "FlexKomSigLaenge" SG_ 948 VC_RKE_MEM_CSO 64;
BA_ "FlexKomSigName" SG_ 948 VC_RKE_MEM_CSO "VehCfgCSM2_Pkt";
BA_ "FlexKomComment" SG_ 948 VC_RKE_MEM_CSO "Vehicle configuration - customer settings menu 2 P";
BA_ "FlexKomIsMotorola" SG_ 948 VC_RKE_MEM_CSO 1;
BA_ "GenSigSNA" SG_ 948 VC_RKE_MEM_CSO "0h";
BA_ "GenSigSendType" SG_ 948 VC_RKE_UNLK_CSO 5;
BA_ "GenSigCycleTime" SG_ 948 VC_RKE_UNLK_CSO 2000;
BA_ "FlexKomSigStartValue" SG_ 948 VC_RKE_UNLK_CSO "0300000000000000h";
BA_ "GenSigTimeout_IC" SG_ 948 VC_RKE_UNLK_CSO 21000;
BA_ "FlexKomSID" SG_ 948 VC_RKE_UNLK_CSO 2007;
BA_ "FlexKomSigStartPos" SG_ 948 VC_RKE_UNLK_CSO 7;
BA_ "FlexKomSigLaenge" SG_ 948 VC_RKE_UNLK_CSO 64;
BA_ "FlexKomSigName" SG_ 948 VC_RKE_UNLK_CSO "VehCfgCSM2_Pkt";
BA_ "FlexKomComment" SG_ 948 VC_RKE_UNLK_CSO "Vehicle configuration - customer settings menu 2 P";
BA_ "FlexKomIsMotorola" SG_ 948 VC_RKE_UNLK_CSO 1;
BA_ "GenSigSNA" SG_ 948 VC_RKE_UNLK_CSO "0h";
BA_ "GenSigSendType" SG_ 948 VC_SPEED_CSO 5;
BA_ "GenSigCycleTime" SG_ 948 VC_SPEED_CSO 2000;
BA_ "FlexKomSigStartValue" SG_ 948 VC_SPEED_CSO "0300000000000000h";
BA_ "GenSigTimeout_IC" SG_ 948 VC_SPEED_CSO 21000;
BA_ "FlexKomSID" SG_ 948 VC_SPEED_CSO 2007;
BA_ "FlexKomSigStartPos" SG_ 948 VC_SPEED_CSO 7;
BA_ "FlexKomSigLaenge" SG_ 948 VC_SPEED_CSO 64;
BA_ "FlexKomSigName" SG_ 948 VC_SPEED_CSO "VehCfgCSM2_Pkt";
BA_ "FlexKomComment" SG_ 948 VC_SPEED_CSO "Vehicle configuration - customer settings menu 2 P";
BA_ "FlexKomIsMotorola" SG_ 948 VC_SPEED_CSO 1;
BA_ "GenSigSNA" SG_ 948 VC_SPEED_CSO "0h";
BA_ "GenSigSendType" SG_ 948 VC_TLT_MRR_CSO 5;
BA_ "GenSigCycleTime" SG_ 948 VC_TLT_MRR_CSO 2000;
BA_ "FlexKomSigStartValue" SG_ 948 VC_TLT_MRR_CSO "0300000000000000h";
BA_ "GenSigTimeout_IC" SG_ 948 VC_TLT_MRR_CSO 21000;
BA_ "FlexKomSID" SG_ 948 VC_TLT_MRR_CSO 2007;
BA_ "FlexKomSigStartPos" SG_ 948 VC_TLT_MRR_CSO 7;
BA_ "FlexKomSigLaenge" SG_ 948 VC_TLT_MRR_CSO 64;
BA_ "FlexKomSigName" SG_ 948 VC_TLT_MRR_CSO "VehCfgCSM2_Pkt";
BA_ "FlexKomComment" SG_ 948 VC_TLT_MRR_CSO "Vehicle configuration - customer settings menu 2 P";
BA_ "FlexKomIsMotorola" SG_ 948 VC_TLT_MRR_CSO 1;
BA_ "GenSigSNA" SG_ 948 VC_TLT_MRR_CSO "0h";
BA_ "GenSigSendType" SG_ 948 VC_TORQUE_CSO 5;
BA_ "GenSigCycleTime" SG_ 948 VC_TORQUE_CSO 2000;
BA_ "FlexKomSigStartValue" SG_ 948 VC_TORQUE_CSO "0300000000000000h";
BA_ "GenSigTimeout_IC" SG_ 948 VC_TORQUE_CSO 21000;
BA_ "FlexKomSID" SG_ 948 VC_TORQUE_CSO 2007;
BA_ "FlexKomSigStartPos" SG_ 948 VC_TORQUE_CSO 7;
BA_ "FlexKomSigLaenge" SG_ 948 VC_TORQUE_CSO 64;
BA_ "FlexKomSigName" SG_ 948 VC_TORQUE_CSO "VehCfgCSM2_Pkt";
BA_ "FlexKomComment" SG_ 948 VC_TORQUE_CSO "Vehicle configuration - customer settings menu 2 P";
BA_ "FlexKomIsMotorola" SG_ 948 VC_TORQUE_CSO 1;
BA_ "GenSigSNA" SG_ 948 VC_TORQUE_CSO "0h";
BA_ "GenSigSendType" SG_ 948 VC_TRLR_CSO 5;
BA_ "GenSigCycleTime" SG_ 948 VC_TRLR_CSO 2000;
BA_ "FlexKomSigStartValue" SG_ 948 VC_TRLR_CSO "0300000000000000h";
BA_ "GenSigTimeout_IC" SG_ 948 VC_TRLR_CSO 21000;
BA_ "FlexKomSID" SG_ 948 VC_TRLR_CSO 2007;
BA_ "FlexKomSigStartPos" SG_ 948 VC_TRLR_CSO 7;
BA_ "FlexKomSigLaenge" SG_ 948 VC_TRLR_CSO 64;
BA_ "FlexKomSigName" SG_ 948 VC_TRLR_CSO "VehCfgCSM2_Pkt";
BA_ "FlexKomComment" SG_ 948 VC_TRLR_CSO "Vehicle configuration - customer settings menu 2 P";
BA_ "FlexKomIsMotorola" SG_ 948 VC_TRLR_CSO 1;
BA_ "GenSigSNA" SG_ 948 VC_TRLR_CSO "0h";
BA_ "GenSigSendType" SG_ 948 VC_TRLR_NAME_CSO 5;
BA_ "GenSigCycleTime" SG_ 948 VC_TRLR_NAME_CSO 2000;
BA_ "FlexKomSigStartValue" SG_ 948 VC_TRLR_NAME_CSO "0300000000000000h";
BA_ "GenSigTimeout_IC" SG_ 948 VC_TRLR_NAME_CSO 21000;
BA_ "FlexKomSID" SG_ 948 VC_TRLR_NAME_CSO 2007;
BA_ "FlexKomSigStartPos" SG_ 948 VC_TRLR_NAME_CSO 7;
BA_ "FlexKomSigLaenge" SG_ 948 VC_TRLR_NAME_CSO 64;
BA_ "FlexKomSigName" SG_ 948 VC_TRLR_NAME_CSO "VehCfgCSM2_Pkt";
BA_ "FlexKomComment" SG_ 948 VC_TRLR_NAME_CSO "Vehicle configuration - customer settings menu 2 P";
BA_ "FlexKomIsMotorola" SG_ 948 VC_TRLR_NAME_CSO 1;
BA_ "GenSigSNA" SG_ 948 VC_TRLR_NAME_CSO "0h";
BA_ "GenSigSendType" SG_ 948 VC_TRLR_TYPE_CSO 5;
BA_ "GenSigCycleTime" SG_ 948 VC_TRLR_TYPE_CSO 2000;
BA_ "FlexKomSigStartValue" SG_ 948 VC_TRLR_TYPE_CSO "0300000000000000h";
BA_ "GenSigTimeout_IC" SG_ 948 VC_TRLR_TYPE_CSO 21000;
BA_ "FlexKomSID" SG_ 948 VC_TRLR_TYPE_CSO 2007;
BA_ "FlexKomSigStartPos" SG_ 948 VC_TRLR_TYPE_CSO 7;
BA_ "FlexKomSigLaenge" SG_ 948 VC_TRLR_TYPE_CSO 64;
BA_ "FlexKomSigName" SG_ 948 VC_TRLR_TYPE_CSO "VehCfgCSM2_Pkt";
BA_ "FlexKomComment" SG_ 948 VC_TRLR_TYPE_CSO "Vehicle configuration - customer settings menu 2 P";
BA_ "FlexKomIsMotorola" SG_ 948 VC_TRLR_TYPE_CSO 1;
BA_ "GenSigSNA" SG_ 948 VC_TRLR_TYPE_CSO "0h";
BA_ "GenSigSendType" SG_ 948 VC_TRNS_MD_CSO 5;
BA_ "GenSigCycleTime" SG_ 948 VC_TRNS_MD_CSO 2000;
BA_ "FlexKomSigStartValue" SG_ 948 VC_TRNS_MD_CSO "0300000000000000h";
BA_ "GenSigTimeout_IC" SG_ 948 VC_TRNS_MD_CSO 21000;
BA_ "FlexKomSID" SG_ 948 VC_TRNS_MD_CSO 2007;
BA_ "FlexKomSigStartPos" SG_ 948 VC_TRNS_MD_CSO 7;
BA_ "FlexKomSigLaenge" SG_ 948 VC_TRNS_MD_CSO 64;
BA_ "FlexKomSigName" SG_ 948 VC_TRNS_MD_CSO "VehCfgCSM2_Pkt";
BA_ "FlexKomComment" SG_ 948 VC_TRNS_MD_CSO "Vehicle configuration - customer settings menu 2 P";
BA_ "FlexKomIsMotorola" SG_ 948 VC_TRNS_MD_CSO 1;
BA_ "GenSigSNA" SG_ 948 VC_TRNS_MD_CSO "0h";
BA_ "GenSigSendType" SG_ 948 VC_US_METRIC_CSO 5;
BA_ "GenSigCycleTime" SG_ 948 VC_US_METRIC_CSO 2000;
BA_ "FlexKomSigStartValue" SG_ 948 VC_US_METRIC_CSO "0300000000000000h";
BA_ "GenSigTimeout_IC" SG_ 948 VC_US_METRIC_CSO 21000;
BA_ "FlexKomSID" SG_ 948 VC_US_METRIC_CSO 2007;
BA_ "FlexKomSigStartPos" SG_ 948 VC_US_METRIC_CSO 7;
BA_ "FlexKomSigLaenge" SG_ 948 VC_US_METRIC_CSO 64;
BA_ "FlexKomSigName" SG_ 948 VC_US_METRIC_CSO "VehCfgCSM2_Pkt";
BA_ "FlexKomComment" SG_ 948 VC_US_METRIC_CSO "Vehicle configuration - customer settings menu 2 P";
BA_ "FlexKomIsMotorola" SG_ 948 VC_US_METRIC_CSO 1;
BA_ "GenSigSNA" SG_ 948 VC_US_METRIC_CSO "0h";
BA_ "GenSigSendType" SG_ 948 VC_WHL_ALGN_CSO 5;
BA_ "GenSigCycleTime" SG_ 948 VC_WHL_ALGN_CSO 2000;
BA_ "FlexKomSigStartValue" SG_ 948 VC_WHL_ALGN_CSO "0300000000000000h";
BA_ "GenSigTimeout_IC" SG_ 948 VC_WHL_ALGN_CSO 21000;
BA_ "FlexKomSID" SG_ 948 VC_WHL_ALGN_CSO 2007;
BA_ "FlexKomSigStartPos" SG_ 948 VC_WHL_ALGN_CSO 7;
BA_ "FlexKomSigLaenge" SG_ 948 VC_WHL_ALGN_CSO 64;
BA_ "FlexKomSigName" SG_ 948 VC_WHL_ALGN_CSO "VehCfgCSM2_Pkt";
BA_ "FlexKomComment" SG_ 948 VC_WHL_ALGN_CSO "Vehicle configuration - customer settings menu 2 P";
BA_ "FlexKomIsMotorola" SG_ 948 VC_WHL_ALGN_CSO 1;
BA_ "GenSigSNA" SG_ 948 VC_WHL_ALGN_CSO "0h";
BA_ "GenSigSendType" SG_ 948 VC_FUEL_SAV_CSO 5;
BA_ "GenSigCycleTime" SG_ 948 VC_FUEL_SAV_CSO 2000;
BA_ "FlexKomSigStartValue" SG_ 948 VC_FUEL_SAV_CSO "0300000000000000h";
BA_ "FlexKomSID" SG_ 948 VC_FUEL_SAV_CSO 2007;
BA_ "FlexKomSigStartPos" SG_ 948 VC_FUEL_SAV_CSO 7;
BA_ "FlexKomSigLaenge" SG_ 948 VC_FUEL_SAV_CSO 64;
BA_ "FlexKomSigName" SG_ 948 VC_FUEL_SAV_CSO "VehCfgCSM2_Pkt";
BA_ "FlexKomComment" SG_ 948 VC_FUEL_SAV_CSO "Vehicle configuration - customer settings menu 2 P";
BA_ "FlexKomIsMotorola" SG_ 948 VC_FUEL_SAV_CSO 1;
BA_ "GenSigSNA" SG_ 948 VC_FUEL_SAV_CSO "0h";
BA_ "GenSigSendType" SG_ 948 VC_TEMP_CSO 5;
BA_ "GenSigCycleTime" SG_ 948 VC_TEMP_CSO 2000;
BA_ "FlexKomSigStartValue" SG_ 948 VC_TEMP_CSO "0300000000000000h";
BA_ "FlexKomSID" SG_ 948 VC_TEMP_CSO 2007;
BA_ "FlexKomSigStartPos" SG_ 948 VC_TEMP_CSO 7;
BA_ "FlexKomSigLaenge" SG_ 948 VC_TEMP_CSO 64;
BA_ "FlexKomSigName" SG_ 948 VC_TEMP_CSO "VehCfgCSM2_Pkt";
BA_ "FlexKomComment" SG_ 948 VC_TEMP_CSO "Vehicle configuration - customer settings menu 2 P";
BA_ "FlexKomIsMotorola" SG_ 948 VC_TEMP_CSO 1;
BA_ "GenSigSNA" SG_ 948 VC_TEMP_CSO "0h";
BA_ "GenSigSendType" SG_ 949 VC_BU_VehCfgCSO1_Stat 1;
BA_ "FlexKomSigStartValue" SG_ 949 VC_BU_VehCfgCSO1_Stat "0300000000000000h";
BA_ "GenSigStartValue" SG_ 949 VC_BU_VehCfgCSO1_Stat 3;
BA_ "FlexKomSID" SG_ 949 VC_BU_VehCfgCSO1_Stat 2008;
BA_ "FlexKomSigStartPos" SG_ 949 VC_BU_VehCfgCSO1_Stat 7;
BA_ "FlexKomSigLaenge" SG_ 949 VC_BU_VehCfgCSO1_Stat 64;
BA_ "FlexKomSigName" SG_ 949 VC_BU_VehCfgCSO1_Stat "VehCfgCSM1_BuPkt";
BA_ "FlexKomComment" SG_ 949 VC_BU_VehCfgCSO1_Stat "Backup for veh config - customer settings menu 1 P";
BA_ "FlexKomIsMotorola" SG_ 949 VC_BU_VehCfgCSO1_Stat 1;
BA_ "GenSigSNA" SG_ 949 VC_BU_VehCfgCSO1_Stat "3h";
BA_ "GenSigSendType" SG_ 949 VC_BU_PRK_AST_CSO 1;
BA_ "FlexKomSigStartValue" SG_ 949 VC_BU_PRK_AST_CSO "0300000000000000h";
BA_ "FlexKomSID" SG_ 949 VC_BU_PRK_AST_CSO 2008;
BA_ "FlexKomSigStartPos" SG_ 949 VC_BU_PRK_AST_CSO 7;
BA_ "FlexKomSigLaenge" SG_ 949 VC_BU_PRK_AST_CSO 64;
BA_ "FlexKomSigName" SG_ 949 VC_BU_PRK_AST_CSO "VehCfgCSM1_BuPkt";
BA_ "FlexKomComment" SG_ 949 VC_BU_PRK_AST_CSO "Backup for veh config - customer settings menu 1 P";
BA_ "FlexKomIsMotorola" SG_ 949 VC_BU_PRK_AST_CSO 1;
BA_ "GenSigSNA" SG_ 949 VC_BU_PRK_AST_CSO "0h";
BA_ "GenSigSendType" SG_ 949 VC_BU_PRK_AST_BRK_CSO 1;
BA_ "FlexKomSigStartValue" SG_ 949 VC_BU_PRK_AST_BRK_CSO "0300000000000000h";
BA_ "FlexKomSID" SG_ 949 VC_BU_PRK_AST_BRK_CSO 2008;
BA_ "FlexKomSigStartPos" SG_ 949 VC_BU_PRK_AST_BRK_CSO 7;
BA_ "FlexKomSigLaenge" SG_ 949 VC_BU_PRK_AST_BRK_CSO 64;
BA_ "FlexKomSigName" SG_ 949 VC_BU_PRK_AST_BRK_CSO "VehCfgCSM1_BuPkt";
BA_ "FlexKomComment" SG_ 949 VC_BU_PRK_AST_BRK_CSO "Backup for veh config - customer settings menu 1 P";
BA_ "FlexKomIsMotorola" SG_ 949 VC_BU_PRK_AST_BRK_CSO 1;
BA_ "GenSigSNA" SG_ 949 VC_BU_PRK_AST_BRK_CSO "0h";
BA_ "GenSigSendType" SG_ 949 VC_BU_PRK_FT_VOL_CSO 1;
BA_ "FlexKomSigStartValue" SG_ 949 VC_BU_PRK_FT_VOL_CSO "0300000000000000h";
BA_ "FlexKomSID" SG_ 949 VC_BU_PRK_FT_VOL_CSO 2008;
BA_ "FlexKomSigStartPos" SG_ 949 VC_BU_PRK_FT_VOL_CSO 7;
BA_ "FlexKomSigLaenge" SG_ 949 VC_BU_PRK_FT_VOL_CSO 64;
BA_ "FlexKomSigName" SG_ 949 VC_BU_PRK_FT_VOL_CSO "VehCfgCSM1_BuPkt";
BA_ "FlexKomComment" SG_ 949 VC_BU_PRK_FT_VOL_CSO "Backup for veh config - customer settings menu 1 P";
BA_ "FlexKomIsMotorola" SG_ 949 VC_BU_PRK_FT_VOL_CSO 1;
BA_ "GenSigSNA" SG_ 949 VC_BU_PRK_FT_VOL_CSO "0h";
BA_ "GenSigSendType" SG_ 949 VC_BU_PRK_RR_VOL_CSO 1;
BA_ "FlexKomSigStartValue" SG_ 949 VC_BU_PRK_RR_VOL_CSO "0300000000000000h";
BA_ "FlexKomSID" SG_ 949 VC_BU_PRK_RR_VOL_CSO 2008;
BA_ "FlexKomSigStartPos" SG_ 949 VC_BU_PRK_RR_VOL_CSO 7;
BA_ "FlexKomSigLaenge" SG_ 949 VC_BU_PRK_RR_VOL_CSO 64;
BA_ "FlexKomSigName" SG_ 949 VC_BU_PRK_RR_VOL_CSO "VehCfgCSM1_BuPkt";
BA_ "FlexKomComment" SG_ 949 VC_BU_PRK_RR_VOL_CSO "Backup for veh config - customer settings menu 1 P";
BA_ "FlexKomIsMotorola" SG_ 949 VC_BU_PRK_RR_VOL_CSO 1;
BA_ "GenSigSNA" SG_ 949 VC_BU_PRK_RR_VOL_CSO "0h";
BA_ "GenSigSendType" SG_ 949 VC_BU_EPS_CSO 1;
BA_ "FlexKomSigStartValue" SG_ 949 VC_BU_EPS_CSO "0300000000000000h";
BA_ "FlexKomSID" SG_ 949 VC_BU_EPS_CSO 2008;
BA_ "FlexKomSigStartPos" SG_ 949 VC_BU_EPS_CSO 7;
BA_ "FlexKomSigLaenge" SG_ 949 VC_BU_EPS_CSO 64;
BA_ "FlexKomSigName" SG_ 949 VC_BU_EPS_CSO "VehCfgCSM1_BuPkt";
BA_ "FlexKomComment" SG_ 949 VC_BU_EPS_CSO "Backup for veh config - customer settings menu 1 P";
BA_ "FlexKomIsMotorola" SG_ 949 VC_BU_EPS_CSO 1;
BA_ "GenSigSNA" SG_ 949 VC_BU_EPS_CSO "0h";
BA_ "GenSigSendType" SG_ 949 VC_BU_FCW_CSO 1;
BA_ "FlexKomSigStartValue" SG_ 949 VC_BU_FCW_CSO "0300000000000000h";
BA_ "FlexKomSID" SG_ 949 VC_BU_FCW_CSO 2008;
BA_ "FlexKomSigStartPos" SG_ 949 VC_BU_FCW_CSO 7;
BA_ "FlexKomSigLaenge" SG_ 949 VC_BU_FCW_CSO 64;
BA_ "FlexKomSigName" SG_ 949 VC_BU_FCW_CSO "VehCfgCSM1_BuPkt";
BA_ "FlexKomComment" SG_ 949 VC_BU_FCW_CSO "Backup for veh config - customer settings menu 1 P";
BA_ "FlexKomIsMotorola" SG_ 949 VC_BU_FCW_CSO 1;
BA_ "GenSigSNA" SG_ 949 VC_BU_FCW_CSO "0h";
BA_ "GenSigSendType" SG_ 949 VC_BU_FCW_BRK_CSO 1;
BA_ "FlexKomSigStartValue" SG_ 949 VC_BU_FCW_BRK_CSO "0300000000000000h";
BA_ "FlexKomSID" SG_ 949 VC_BU_FCW_BRK_CSO 2008;
BA_ "FlexKomSigStartPos" SG_ 949 VC_BU_FCW_BRK_CSO 7;
BA_ "FlexKomSigLaenge" SG_ 949 VC_BU_FCW_BRK_CSO 64;
BA_ "FlexKomSigName" SG_ 949 VC_BU_FCW_BRK_CSO "VehCfgCSM1_BuPkt";
BA_ "FlexKomComment" SG_ 949 VC_BU_FCW_BRK_CSO "Backup for veh config - customer settings menu 1 P";
BA_ "FlexKomIsMotorola" SG_ 949 VC_BU_FCW_BRK_CSO 1;
BA_ "GenSigSNA" SG_ 949 VC_BU_FCW_BRK_CSO "0h";
BA_ "GenSigSendType" SG_ 949 VC_BU_HRN_RMT_LK_CSO 1;
BA_ "FlexKomSigStartValue" SG_ 949 VC_BU_HRN_RMT_LK_CSO "0300000000000000h";
BA_ "FlexKomSID" SG_ 949 VC_BU_HRN_RMT_LK_CSO 2008;
BA_ "FlexKomSigStartPos" SG_ 949 VC_BU_HRN_RMT_LK_CSO 7;
BA_ "FlexKomSigLaenge" SG_ 949 VC_BU_HRN_RMT_LK_CSO 64;
BA_ "FlexKomSigName" SG_ 949 VC_BU_HRN_RMT_LK_CSO "VehCfgCSM1_BuPkt";
BA_ "FlexKomComment" SG_ 949 VC_BU_HRN_RMT_LK_CSO "Backup for veh config - customer settings menu 1 P";
BA_ "FlexKomIsMotorola" SG_ 949 VC_BU_HRN_RMT_LK_CSO 1;
BA_ "GenSigSNA" SG_ 949 VC_BU_HRN_RMT_LK_CSO "0h";
BA_ "GenSigSendType" SG_ 949 VC_BU_HRN_RMT_ST_CSO 1;
BA_ "FlexKomSigStartValue" SG_ 949 VC_BU_HRN_RMT_ST_CSO "0300000000000000h";
BA_ "FlexKomSID" SG_ 949 VC_BU_HRN_RMT_ST_CSO 2008;
BA_ "FlexKomSigStartPos" SG_ 949 VC_BU_HRN_RMT_ST_CSO 7;
BA_ "FlexKomSigLaenge" SG_ 949 VC_BU_HRN_RMT_ST_CSO 64;
BA_ "FlexKomSigName" SG_ 949 VC_BU_HRN_RMT_ST_CSO "VehCfgCSM1_BuPkt";
BA_ "FlexKomComment" SG_ 949 VC_BU_HRN_RMT_ST_CSO "Backup for veh config - customer settings menu 1 P";
BA_ "FlexKomIsMotorola" SG_ 949 VC_BU_HRN_RMT_ST_CSO 1;
BA_ "GenSigSNA" SG_ 949 VC_BU_HRN_RMT_ST_CSO "0h";
BA_ "GenSigSendType" SG_ 949 VC_BU_HRN_RMT_LWR_CSO 1;
BA_ "FlexKomSigStartValue" SG_ 949 VC_BU_HRN_RMT_LWR_CSO "0300000000000000h";
BA_ "FlexKomSID" SG_ 949 VC_BU_HRN_RMT_LWR_CSO 2008;
BA_ "FlexKomSigStartPos" SG_ 949 VC_BU_HRN_RMT_LWR_CSO 7;
BA_ "FlexKomSigLaenge" SG_ 949 VC_BU_HRN_RMT_LWR_CSO 64;
BA_ "FlexKomSigName" SG_ 949 VC_BU_HRN_RMT_LWR_CSO "VehCfgCSM1_BuPkt";
BA_ "FlexKomComment" SG_ 949 VC_BU_HRN_RMT_LWR_CSO "Backup for veh config - customer settings menu 1 P";
BA_ "FlexKomIsMotorola" SG_ 949 VC_BU_HRN_RMT_LWR_CSO 1;
BA_ "GenSigSNA" SG_ 949 VC_BU_HRN_RMT_LWR_CSO "0h";
BA_ "GenSigSendType" SG_ 949 VC_BU_CHMSL_LINE_CSO 1;
BA_ "FlexKomSigStartValue" SG_ 949 VC_BU_CHMSL_LINE_CSO "0300000000000000h";
BA_ "FlexKomSID" SG_ 949 VC_BU_CHMSL_LINE_CSO 2008;
BA_ "FlexKomSigStartPos" SG_ 949 VC_BU_CHMSL_LINE_CSO 7;
BA_ "FlexKomSigLaenge" SG_ 949 VC_BU_CHMSL_LINE_CSO 64;
BA_ "FlexKomSigName" SG_ 949 VC_BU_CHMSL_LINE_CSO "VehCfgCSM1_BuPkt";
BA_ "FlexKomComment" SG_ 949 VC_BU_CHMSL_LINE_CSO "Backup for veh config - customer settings menu 1 P";
BA_ "FlexKomIsMotorola" SG_ 949 VC_BU_CHMSL_LINE_CSO 1;
BA_ "GenSigSNA" SG_ 949 VC_BU_CHMSL_LINE_CSO "0h";
BA_ "GenSigSendType" SG_ 949 VC_BU_DCS_CSO 1;
BA_ "FlexKomSigStartValue" SG_ 949 VC_BU_DCS_CSO "0300000000000000h";
BA_ "FlexKomSID" SG_ 949 VC_BU_DCS_CSO 2008;
BA_ "FlexKomSigStartPos" SG_ 949 VC_BU_DCS_CSO 7;
BA_ "FlexKomSigLaenge" SG_ 949 VC_BU_DCS_CSO 64;
BA_ "FlexKomSigName" SG_ 949 VC_BU_DCS_CSO "VehCfgCSM1_BuPkt";
BA_ "FlexKomComment" SG_ 949 VC_BU_DCS_CSO "Backup for veh config - customer settings menu 1 P";
BA_ "FlexKomIsMotorola" SG_ 949 VC_BU_DCS_CSO 1;
BA_ "GenSigSNA" SG_ 949 VC_BU_DCS_CSO "0h";
BA_ "GenSigSendType" SG_ 949 VC_BU_AUX_SWS_CSO 1;
BA_ "FlexKomSigStartValue" SG_ 949 VC_BU_AUX_SWS_CSO "0300000000000000h";
BA_ "FlexKomSID" SG_ 949 VC_BU_AUX_SWS_CSO 2008;
BA_ "FlexKomSigStartPos" SG_ 949 VC_BU_AUX_SWS_CSO 7;
BA_ "FlexKomSigLaenge" SG_ 949 VC_BU_AUX_SWS_CSO 64;
BA_ "FlexKomSigName" SG_ 949 VC_BU_AUX_SWS_CSO "VehCfgCSM1_BuPkt";
BA_ "FlexKomComment" SG_ 949 VC_BU_AUX_SWS_CSO "Backup for veh config - customer settings menu 1 P";
BA_ "FlexKomIsMotorola" SG_ 949 VC_BU_AUX_SWS_CSO 1;
BA_ "GenSigSNA" SG_ 949 VC_BU_AUX_SWS_CSO "0h";
BA_ "GenSigSendType" SG_ 949 VC_BU_CMRA_GRDLNS_CSO 1;
BA_ "FlexKomSigStartValue" SG_ 949 VC_BU_CMRA_GRDLNS_CSO "0300000000000000h";
BA_ "FlexKomSID" SG_ 949 VC_BU_CMRA_GRDLNS_CSO 2008;
BA_ "FlexKomSigStartPos" SG_ 949 VC_BU_CMRA_GRDLNS_CSO 7;
BA_ "FlexKomSigLaenge" SG_ 949 VC_BU_CMRA_GRDLNS_CSO 64;
BA_ "FlexKomSigName" SG_ 949 VC_BU_CMRA_GRDLNS_CSO "VehCfgCSM1_BuPkt";
BA_ "FlexKomComment" SG_ 949 VC_BU_CMRA_GRDLNS_CSO "Backup for veh config - customer settings menu 1 P";
BA_ "FlexKomIsMotorola" SG_ 949 VC_BU_CMRA_GRDLNS_CSO 1;
BA_ "GenSigSNA" SG_ 949 VC_BU_CMRA_GRDLNS_CSO "0h";
BA_ "GenSigSendType" SG_ 949 VC_BU_ACC_DLY_CSO 1;
BA_ "FlexKomSigStartValue" SG_ 949 VC_BU_ACC_DLY_CSO "0300000000000000h";
BA_ "FlexKomSID" SG_ 949 VC_BU_ACC_DLY_CSO 2008;
BA_ "FlexKomSigStartPos" SG_ 949 VC_BU_ACC_DLY_CSO 7;
BA_ "FlexKomSigLaenge" SG_ 949 VC_BU_ACC_DLY_CSO 64;
BA_ "FlexKomSigName" SG_ 949 VC_BU_ACC_DLY_CSO "VehCfgCSM1_BuPkt";
BA_ "FlexKomComment" SG_ 949 VC_BU_ACC_DLY_CSO "Backup for veh config - customer settings menu 1 P";
BA_ "FlexKomIsMotorola" SG_ 949 VC_BU_ACC_DLY_CSO 1;
BA_ "GenSigSNA" SG_ 949 VC_BU_ACC_DLY_CSO "0h";
BA_ "GenSigSendType" SG_ 949 VC_BU_AFLS_CSO 1;
BA_ "FlexKomSigStartValue" SG_ 949 VC_BU_AFLS_CSO "0300000000000000h";
BA_ "FlexKomSID" SG_ 949 VC_BU_AFLS_CSO 2008;
BA_ "FlexKomSigStartPos" SG_ 949 VC_BU_AFLS_CSO 7;
BA_ "FlexKomSigLaenge" SG_ 949 VC_BU_AFLS_CSO 64;
BA_ "FlexKomSigName" SG_ 949 VC_BU_AFLS_CSO "VehCfgCSM1_BuPkt";
BA_ "FlexKomComment" SG_ 949 VC_BU_AFLS_CSO "Backup for veh config - customer settings menu 1 P";
BA_ "FlexKomIsMotorola" SG_ 949 VC_BU_AFLS_CSO 1;
BA_ "GenSigSNA" SG_ 949 VC_BU_AFLS_CSO "0h";
BA_ "GenSigSendType" SG_ 949 VC_BU_AMB_DMR_CSO 1;
BA_ "FlexKomSigStartValue" SG_ 949 VC_BU_AMB_DMR_CSO "0300000000000000h";
BA_ "FlexKomSID" SG_ 949 VC_BU_AMB_DMR_CSO 2008;
BA_ "FlexKomSigStartPos" SG_ 949 VC_BU_AMB_DMR_CSO 7;
BA_ "FlexKomSigLaenge" SG_ 949 VC_BU_AMB_DMR_CSO 64;
BA_ "FlexKomSigName" SG_ 949 VC_BU_AMB_DMR_CSO "VehCfgCSM1_BuPkt";
BA_ "FlexKomComment" SG_ 949 VC_BU_AMB_DMR_CSO "Backup for veh config - customer settings menu 1 P";
BA_ "FlexKomIsMotorola" SG_ 949 VC_BU_AMB_DMR_CSO 1;
BA_ "GenSigSNA" SG_ 949 VC_BU_AMB_DMR_CSO "0h";
BA_ "GenSigSendType" SG_ 949 VC_BU_ASCM_TJ_CSO 1;
BA_ "FlexKomSigStartValue" SG_ 949 VC_BU_ASCM_TJ_CSO "0300000000000000h";
BA_ "FlexKomSID" SG_ 949 VC_BU_ASCM_TJ_CSO 2008;
BA_ "FlexKomSigStartPos" SG_ 949 VC_BU_ASCM_TJ_CSO 7;
BA_ "FlexKomSigLaenge" SG_ 949 VC_BU_ASCM_TJ_CSO 64;
BA_ "FlexKomSigName" SG_ 949 VC_BU_ASCM_TJ_CSO "VehCfgCSM1_BuPkt";
BA_ "FlexKomComment" SG_ 949 VC_BU_ASCM_TJ_CSO "Backup for veh config - customer settings menu 1 P";
BA_ "FlexKomIsMotorola" SG_ 949 VC_BU_ASCM_TJ_CSO 1;
BA_ "GenSigSNA" SG_ 949 VC_BU_ASCM_TJ_CSO "0h";
BA_ "GenSigSendType" SG_ 949 VC_BU_ASCM_WRN_CSO 1;
BA_ "FlexKomSigStartValue" SG_ 949 VC_BU_ASCM_WRN_CSO "0300000000000000h";
BA_ "FlexKomSID" SG_ 949 VC_BU_ASCM_WRN_CSO 2008;
BA_ "FlexKomSigStartPos" SG_ 949 VC_BU_ASCM_WRN_CSO 7;
BA_ "FlexKomSigLaenge" SG_ 949 VC_BU_ASCM_WRN_CSO 64;
BA_ "FlexKomSigName" SG_ 949 VC_BU_ASCM_WRN_CSO "VehCfgCSM1_BuPkt";
BA_ "FlexKomComment" SG_ 949 VC_BU_ASCM_WRN_CSO "Backup for veh config - customer settings menu 1 P";
BA_ "FlexKomIsMotorola" SG_ 949 VC_BU_ASCM_WRN_CSO 1;
BA_ "GenSigSNA" SG_ 949 VC_BU_ASCM_WRN_CSO "0h";
BA_ "GenSigSendType" SG_ 949 VC_BU_AUTO_AERO_CSO 1;
BA_ "FlexKomSigStartValue" SG_ 949 VC_BU_AUTO_AERO_CSO "0300000000000000h";
BA_ "FlexKomSID" SG_ 949 VC_BU_AUTO_AERO_CSO 2008;
BA_ "FlexKomSigStartPos" SG_ 949 VC_BU_AUTO_AERO_CSO 7;
BA_ "FlexKomSigLaenge" SG_ 949 VC_BU_AUTO_AERO_CSO 64;
BA_ "FlexKomSigName" SG_ 949 VC_BU_AUTO_AERO_CSO "VehCfgCSM1_BuPkt";
BA_ "FlexKomComment" SG_ 949 VC_BU_AUTO_AERO_CSO "Backup for veh config - customer settings menu 1 P";
BA_ "FlexKomIsMotorola" SG_ 949 VC_BU_AUTO_AERO_CSO 1;
BA_ "GenSigSNA" SG_ 949 VC_BU_AUTO_AERO_CSO "0h";
BA_ "GenSigSendType" SG_ 949 VC_BU_AUTO_HB_CSO 1;
BA_ "FlexKomSigStartValue" SG_ 949 VC_BU_AUTO_HB_CSO "0300000000000000h";
BA_ "FlexKomSID" SG_ 949 VC_BU_AUTO_HB_CSO 2008;
BA_ "FlexKomSigStartPos" SG_ 949 VC_BU_AUTO_HB_CSO 7;
BA_ "FlexKomSigLaenge" SG_ 949 VC_BU_AUTO_HB_CSO 64;
BA_ "FlexKomSigName" SG_ 949 VC_BU_AUTO_HB_CSO "VehCfgCSM1_BuPkt";
BA_ "FlexKomComment" SG_ 949 VC_BU_AUTO_HB_CSO "Backup for veh config - customer settings menu 1 P";
BA_ "FlexKomIsMotorola" SG_ 949 VC_BU_AUTO_HB_CSO 1;
BA_ "GenSigSNA" SG_ 949 VC_BU_AUTO_HB_CSO "0h";
BA_ "GenSigSendType" SG_ 949 VC_BU_AUTO_PRK_CSO 1;
BA_ "FlexKomSigStartValue" SG_ 949 VC_BU_AUTO_PRK_CSO "0300000000000000h";
BA_ "FlexKomSID" SG_ 949 VC_BU_AUTO_PRK_CSO 2008;
BA_ "FlexKomSigStartPos" SG_ 949 VC_BU_AUTO_PRK_CSO 7;
BA_ "FlexKomSigLaenge" SG_ 949 VC_BU_AUTO_PRK_CSO 64;
BA_ "FlexKomSigName" SG_ 949 VC_BU_AUTO_PRK_CSO "VehCfgCSM1_BuPkt";
BA_ "FlexKomComment" SG_ 949 VC_BU_AUTO_PRK_CSO "Backup for veh config - customer settings menu 1 P";
BA_ "FlexKomIsMotorola" SG_ 949 VC_BU_AUTO_PRK_CSO 1;
BA_ "GenSigSNA" SG_ 949 VC_BU_AUTO_PRK_CSO "0h";
BA_ "GenSigSendType" SG_ 949 VC_BU_BLIND_SPOT_CSO 1;
BA_ "FlexKomSigStartValue" SG_ 949 VC_BU_BLIND_SPOT_CSO "0300000000000000h";
BA_ "FlexKomSID" SG_ 949 VC_BU_BLIND_SPOT_CSO 2008;
BA_ "FlexKomSigStartPos" SG_ 949 VC_BU_BLIND_SPOT_CSO 7;
BA_ "FlexKomSigLaenge" SG_ 949 VC_BU_BLIND_SPOT_CSO 64;
BA_ "FlexKomSigName" SG_ 949 VC_BU_BLIND_SPOT_CSO "VehCfgCSM1_BuPkt";
BA_ "FlexKomComment" SG_ 949 VC_BU_BLIND_SPOT_CSO "Backup for veh config - customer settings menu 1 P";
BA_ "FlexKomIsMotorola" SG_ 949 VC_BU_BLIND_SPOT_CSO 1;
BA_ "GenSigSNA" SG_ 949 VC_BU_BLIND_SPOT_CSO "0h";
BA_ "GenSigSendType" SG_ 949 VC_BU_CAPACITY_CSO 1;
BA_ "FlexKomSigStartValue" SG_ 949 VC_BU_CAPACITY_CSO "0300000000000000h";
BA_ "FlexKomSID" SG_ 949 VC_BU_CAPACITY_CSO 2008;
BA_ "FlexKomSigStartPos" SG_ 949 VC_BU_CAPACITY_CSO 7;
BA_ "FlexKomSigLaenge" SG_ 949 VC_BU_CAPACITY_CSO 64;
BA_ "FlexKomSigName" SG_ 949 VC_BU_CAPACITY_CSO "VehCfgCSM1_BuPkt";
BA_ "FlexKomComment" SG_ 949 VC_BU_CAPACITY_CSO "Backup for veh config - customer settings menu 1 P";
BA_ "FlexKomIsMotorola" SG_ 949 VC_BU_CAPACITY_CSO 1;
BA_ "GenSigSNA" SG_ 949 VC_BU_CAPACITY_CSO "0h";
BA_ "GenSigSendType" SG_ 949 VC_BU_CLK_DSP_CSO 1;
BA_ "FlexKomSigStartValue" SG_ 949 VC_BU_CLK_DSP_CSO "0300000000000000h";
BA_ "FlexKomSID" SG_ 949 VC_BU_CLK_DSP_CSO 2008;
BA_ "FlexKomSigStartPos" SG_ 949 VC_BU_CLK_DSP_CSO 7;
BA_ "FlexKomSigLaenge" SG_ 949 VC_BU_CLK_DSP_CSO 64;
BA_ "FlexKomSigName" SG_ 949 VC_BU_CLK_DSP_CSO "VehCfgCSM1_BuPkt";
BA_ "FlexKomComment" SG_ 949 VC_BU_CLK_DSP_CSO "Backup for veh config - customer settings menu 1 P";
BA_ "FlexKomIsMotorola" SG_ 949 VC_BU_CLK_DSP_CSO 1;
BA_ "GenSigSNA" SG_ 949 VC_BU_CLK_DSP_CSO "0h";
BA_ "GenSigSendType" SG_ 949 VC_BU_CMP_CAL_CSO 1;
BA_ "FlexKomSigStartValue" SG_ 949 VC_BU_CMP_CAL_CSO "0300000000000000h";
BA_ "FlexKomSID" SG_ 949 VC_BU_CMP_CAL_CSO 2008;
BA_ "FlexKomSigStartPos" SG_ 949 VC_BU_CMP_CAL_CSO 7;
BA_ "FlexKomSigLaenge" SG_ 949 VC_BU_CMP_CAL_CSO 64;
BA_ "FlexKomSigName" SG_ 949 VC_BU_CMP_CAL_CSO "VehCfgCSM1_BuPkt";
BA_ "FlexKomComment" SG_ 949 VC_BU_CMP_CAL_CSO "Backup for veh config - customer settings menu 1 P";
BA_ "FlexKomIsMotorola" SG_ 949 VC_BU_CMP_CAL_CSO 1;
BA_ "GenSigSNA" SG_ 949 VC_BU_CMP_CAL_CSO "0h";
BA_ "GenSigSendType" SG_ 949 VC_BU_CMP_VAR_CSO 1;
BA_ "FlexKomSigStartValue" SG_ 949 VC_BU_CMP_VAR_CSO "0300000000000000h";
BA_ "FlexKomSID" SG_ 949 VC_BU_CMP_VAR_CSO 2008;
BA_ "FlexKomSigStartPos" SG_ 949 VC_BU_CMP_VAR_CSO 7;
BA_ "FlexKomSigLaenge" SG_ 949 VC_BU_CMP_VAR_CSO 64;
BA_ "FlexKomSigName" SG_ 949 VC_BU_CMP_VAR_CSO "VehCfgCSM1_BuPkt";
BA_ "FlexKomComment" SG_ 949 VC_BU_CMP_VAR_CSO "Backup for veh config - customer settings menu 1 P";
BA_ "FlexKomIsMotorola" SG_ 949 VC_BU_CMP_VAR_CSO 1;
BA_ "GenSigSNA" SG_ 949 VC_BU_CMP_VAR_CSO "0h";
BA_ "GenSigSendType" SG_ 949 VC_BU_CONS_CSO 1;
BA_ "FlexKomSigStartValue" SG_ 949 VC_BU_CONS_CSO "0300000000000000h";
BA_ "FlexKomSID" SG_ 949 VC_BU_CONS_CSO 2008;
BA_ "FlexKomSigStartPos" SG_ 949 VC_BU_CONS_CSO 7;
BA_ "FlexKomSigLaenge" SG_ 949 VC_BU_CONS_CSO 64;
BA_ "FlexKomSigName" SG_ 949 VC_BU_CONS_CSO "VehCfgCSM1_BuPkt";
BA_ "FlexKomComment" SG_ 949 VC_BU_CONS_CSO "Backup for veh config - customer settings menu 1 P";
BA_ "FlexKomIsMotorola" SG_ 949 VC_BU_CONS_CSO 1;
BA_ "GenSigSNA" SG_ 949 VC_BU_CONS_CSO "0h";
BA_ "GenSigSendType" SG_ 949 VC_BU_DISTANCE_CSO 1;
BA_ "FlexKomSigStartValue" SG_ 949 VC_BU_DISTANCE_CSO "0300000000000000h";
BA_ "FlexKomSID" SG_ 949 VC_BU_DISTANCE_CSO 2008;
BA_ "FlexKomSigStartPos" SG_ 949 VC_BU_DISTANCE_CSO 7;
BA_ "FlexKomSigLaenge" SG_ 949 VC_BU_DISTANCE_CSO 64;
BA_ "FlexKomSigName" SG_ 949 VC_BU_DISTANCE_CSO "VehCfgCSM1_BuPkt";
BA_ "FlexKomComment" SG_ 949 VC_BU_DISTANCE_CSO "Backup for veh config - customer settings menu 1 P";
BA_ "FlexKomIsMotorola" SG_ 949 VC_BU_DISTANCE_CSO 1;
BA_ "GenSigSNA" SG_ 949 VC_BU_DISTANCE_CSO "0h";
BA_ "GenSigSendType" SG_ 949 VC_BU_DR_LK_CSO 1;
BA_ "FlexKomSigStartValue" SG_ 949 VC_BU_DR_LK_CSO "0300000000000000h";
BA_ "FlexKomSID" SG_ 949 VC_BU_DR_LK_CSO 2008;
BA_ "FlexKomSigStartPos" SG_ 949 VC_BU_DR_LK_CSO 7;
BA_ "FlexKomSigLaenge" SG_ 949 VC_BU_DR_LK_CSO 64;
BA_ "FlexKomSigName" SG_ 949 VC_BU_DR_LK_CSO "VehCfgCSM1_BuPkt";
BA_ "FlexKomComment" SG_ 949 VC_BU_DR_LK_CSO "Backup for veh config - customer settings menu 1 P";
BA_ "FlexKomIsMotorola" SG_ 949 VC_BU_DR_LK_CSO 1;
BA_ "GenSigSNA" SG_ 949 VC_BU_DR_LK_CSO "0h";
BA_ "GenSigSendType" SG_ 949 VC_BU_DR_UNLK_CSO 1;
BA_ "FlexKomSigStartValue" SG_ 949 VC_BU_DR_UNLK_CSO "0300000000000000h";
BA_ "FlexKomSID" SG_ 949 VC_BU_DR_UNLK_CSO 2008;
BA_ "FlexKomSigStartPos" SG_ 949 VC_BU_DR_UNLK_CSO 7;
BA_ "FlexKomSigLaenge" SG_ 949 VC_BU_DR_UNLK_CSO 64;
BA_ "FlexKomSigName" SG_ 949 VC_BU_DR_UNLK_CSO "VehCfgCSM1_BuPkt";
BA_ "FlexKomComment" SG_ 949 VC_BU_DR_UNLK_CSO "Backup for veh config - customer settings menu 1 P";
BA_ "FlexKomIsMotorola" SG_ 949 VC_BU_DR_UNLK_CSO 1;
BA_ "GenSigSNA" SG_ 949 VC_BU_DR_UNLK_CSO "0h";
BA_ "GenSigSendType" SG_ 949 VC_BU_DRL_CSO 1;
BA_ "FlexKomSigStartValue" SG_ 949 VC_BU_DRL_CSO "0300000000000000h";
BA_ "FlexKomSID" SG_ 949 VC_BU_DRL_CSO 2008;
BA_ "FlexKomSigStartPos" SG_ 949 VC_BU_DRL_CSO 7;
BA_ "FlexKomSigLaenge" SG_ 949 VC_BU_DRL_CSO 64;
BA_ "FlexKomSigName" SG_ 949 VC_BU_DRL_CSO "VehCfgCSM1_BuPkt";
BA_ "FlexKomComment" SG_ 949 VC_BU_DRL_CSO "Backup for veh config - customer settings menu 1 P";
BA_ "FlexKomIsMotorola" SG_ 949 VC_BU_DRL_CSO 1;
BA_ "GenSigSNA" SG_ 949 VC_BU_DRL_CSO "0h";
BA_ "GenSigSendType" SG_ 949 VC_BU_EASY_EXIT_CSO 1;
BA_ "FlexKomSigStartValue" SG_ 949 VC_BU_EASY_EXIT_CSO "0300000000000000h";
BA_ "FlexKomSID" SG_ 949 VC_BU_EASY_EXIT_CSO 2008;
BA_ "FlexKomSigStartPos" SG_ 949 VC_BU_EASY_EXIT_CSO 7;
BA_ "FlexKomSigLaenge" SG_ 949 VC_BU_EASY_EXIT_CSO 64;
BA_ "FlexKomSigName" SG_ 949 VC_BU_EASY_EXIT_CSO "VehCfgCSM1_BuPkt";
BA_ "FlexKomComment" SG_ 949 VC_BU_EASY_EXIT_CSO "Backup for veh config - customer settings menu 1 P";
BA_ "FlexKomIsMotorola" SG_ 949 VC_BU_EASY_EXIT_CSO 1;
BA_ "GenSigSNA" SG_ 949 VC_BU_EASY_EXIT_CSO "0h";
BA_ "GenSigSendType" SG_ 949 VC_BU_ENTRY_EXIT_CSO 1;
BA_ "FlexKomSigStartValue" SG_ 949 VC_BU_ENTRY_EXIT_CSO "0300000000000000h";
BA_ "FlexKomSID" SG_ 949 VC_BU_ENTRY_EXIT_CSO 2008;
BA_ "FlexKomSigStartPos" SG_ 949 VC_BU_ENTRY_EXIT_CSO 7;
BA_ "FlexKomSigLaenge" SG_ 949 VC_BU_ENTRY_EXIT_CSO 64;
BA_ "FlexKomSigName" SG_ 949 VC_BU_ENTRY_EXIT_CSO "VehCfgCSM1_BuPkt";
BA_ "FlexKomComment" SG_ 949 VC_BU_ENTRY_EXIT_CSO "Backup for veh config - customer settings menu 1 P";
BA_ "FlexKomIsMotorola" SG_ 949 VC_BU_ENTRY_EXIT_CSO 1;
BA_ "GenSigSNA" SG_ 949 VC_BU_ENTRY_EXIT_CSO "0h";
BA_ "GenSigSendType" SG_ 949 VC_BU_EPB_SERV_CSO 1;
BA_ "FlexKomSigStartValue" SG_ 949 VC_BU_EPB_SERV_CSO "0300000000000000h";
BA_ "FlexKomSID" SG_ 949 VC_BU_EPB_SERV_CSO 2008;
BA_ "FlexKomSigStartPos" SG_ 949 VC_BU_EPB_SERV_CSO 7;
BA_ "FlexKomSigLaenge" SG_ 949 VC_BU_EPB_SERV_CSO 64;
BA_ "FlexKomSigName" SG_ 949 VC_BU_EPB_SERV_CSO "VehCfgCSM1_BuPkt";
BA_ "FlexKomComment" SG_ 949 VC_BU_EPB_SERV_CSO "Backup for veh config - customer settings menu 1 P";
BA_ "FlexKomIsMotorola" SG_ 949 VC_BU_EPB_SERV_CSO 1;
BA_ "GenSigSNA" SG_ 949 VC_BU_EPB_SERV_CSO "0h";
BA_ "GenSigSendType" SG_ 949 VC_BU_FLSH_LMP_LK_CSO 1;
BA_ "FlexKomSigStartValue" SG_ 949 VC_BU_FLSH_LMP_LK_CSO "0300000000000000h";
BA_ "FlexKomSID" SG_ 949 VC_BU_FLSH_LMP_LK_CSO 2008;
BA_ "FlexKomSigStartPos" SG_ 949 VC_BU_FLSH_LMP_LK_CSO 7;
BA_ "FlexKomSigLaenge" SG_ 949 VC_BU_FLSH_LMP_LK_CSO 64;
BA_ "FlexKomSigName" SG_ 949 VC_BU_FLSH_LMP_LK_CSO "VehCfgCSM1_BuPkt";
BA_ "FlexKomComment" SG_ 949 VC_BU_FLSH_LMP_LK_CSO "Backup for veh config - customer settings menu 1 P";
BA_ "FlexKomIsMotorola" SG_ 949 VC_BU_FLSH_LMP_LK_CSO 1;
BA_ "GenSigSNA" SG_ 949 VC_BU_FLSH_LMP_LK_CSO "0h";
BA_ "GenSigSendType" SG_ 949 VC_BU_HL_DRP_CSO 1;
BA_ "FlexKomSigStartValue" SG_ 949 VC_BU_HL_DRP_CSO "0300000000000000h";
BA_ "FlexKomSID" SG_ 949 VC_BU_HL_DRP_CSO 2008;
BA_ "FlexKomSigStartPos" SG_ 949 VC_BU_HL_DRP_CSO 7;
BA_ "FlexKomSigLaenge" SG_ 949 VC_BU_HL_DRP_CSO 64;
BA_ "FlexKomSigName" SG_ 949 VC_BU_HL_DRP_CSO "VehCfgCSM1_BuPkt";
BA_ "FlexKomComment" SG_ 949 VC_BU_HL_DRP_CSO "Backup for veh config - customer settings menu 1 P";
BA_ "FlexKomIsMotorola" SG_ 949 VC_BU_HL_DRP_CSO 1;
BA_ "GenSigSNA" SG_ 949 VC_BU_HL_DRP_CSO "0h";
BA_ "GenSigSendType" SG_ 949 VC_BU_HL_OFF_DLY_CSO 1;
BA_ "FlexKomSigStartValue" SG_ 949 VC_BU_HL_OFF_DLY_CSO "0300000000000000h";
BA_ "FlexKomSID" SG_ 949 VC_BU_HL_OFF_DLY_CSO 2008;
BA_ "FlexKomSigStartPos" SG_ 949 VC_BU_HL_OFF_DLY_CSO 7;
BA_ "FlexKomSigLaenge" SG_ 949 VC_BU_HL_OFF_DLY_CSO 64;
BA_ "FlexKomSigName" SG_ 949 VC_BU_HL_OFF_DLY_CSO "VehCfgCSM1_BuPkt";
BA_ "FlexKomComment" SG_ 949 VC_BU_HL_OFF_DLY_CSO "Backup for veh config - customer settings menu 1 P";
BA_ "FlexKomIsMotorola" SG_ 949 VC_BU_HL_OFF_DLY_CSO 1;
BA_ "GenSigSNA" SG_ 949 VC_BU_HL_OFF_DLY_CSO "0h";
BA_ "GenSigSendType" SG_ 949 VC_BU_HL_WPR_CSO 1;
BA_ "FlexKomSigStartValue" SG_ 949 VC_BU_HL_WPR_CSO "0300000000000000h";
BA_ "FlexKomSID" SG_ 949 VC_BU_HL_WPR_CSO 2008;
BA_ "FlexKomSigStartPos" SG_ 949 VC_BU_HL_WPR_CSO 7;
BA_ "FlexKomSigLaenge" SG_ 949 VC_BU_HL_WPR_CSO 64;
BA_ "FlexKomSigName" SG_ 949 VC_BU_HL_WPR_CSO "VehCfgCSM1_BuPkt";
BA_ "FlexKomComment" SG_ 949 VC_BU_HL_WPR_CSO "Backup for veh config - customer settings menu 1 P";
BA_ "FlexKomIsMotorola" SG_ 949 VC_BU_HL_WPR_CSO 1;
BA_ "GenSigSNA" SG_ 949 VC_BU_HL_WPR_CSO "0h";
BA_ "GenSigSendType" SG_ 949 VC_BU_HSA_CSO 1;
BA_ "FlexKomSigStartValue" SG_ 949 VC_BU_HSA_CSO "0300000000000000h";
BA_ "FlexKomSID" SG_ 949 VC_BU_HSA_CSO 2008;
BA_ "FlexKomSigStartPos" SG_ 949 VC_BU_HSA_CSO 7;
BA_ "FlexKomSigLaenge" SG_ 949 VC_BU_HSA_CSO 64;
BA_ "FlexKomSigName" SG_ 949 VC_BU_HSA_CSO "VehCfgCSM1_BuPkt";
BA_ "FlexKomComment" SG_ 949 VC_BU_HSA_CSO "Backup for veh config - customer settings menu 1 P";
BA_ "FlexKomIsMotorola" SG_ 949 VC_BU_HSA_CSO 1;
BA_ "GenSigSNA" SG_ 949 VC_BU_HSA_CSO "0h";
BA_ "GenSigSendType" SG_ 949 VC_BU_ILL_APPRCH_CSO 1;
BA_ "FlexKomSigStartValue" SG_ 949 VC_BU_ILL_APPRCH_CSO "0300000000000000h";
BA_ "FlexKomSID" SG_ 949 VC_BU_ILL_APPRCH_CSO 2008;
BA_ "FlexKomSigStartPos" SG_ 949 VC_BU_ILL_APPRCH_CSO 7;
BA_ "FlexKomSigLaenge" SG_ 949 VC_BU_ILL_APPRCH_CSO 64;
BA_ "FlexKomSigName" SG_ 949 VC_BU_ILL_APPRCH_CSO "VehCfgCSM1_BuPkt";
BA_ "FlexKomComment" SG_ 949 VC_BU_ILL_APPRCH_CSO "Backup for veh config - customer settings menu 1 P";
BA_ "FlexKomIsMotorola" SG_ 949 VC_BU_ILL_APPRCH_CSO 1;
BA_ "GenSigSNA" SG_ 949 VC_BU_ILL_APPRCH_CSO "0h";
BA_ "GenSigSendType" SG_ 949 VC_BU_LDW_TRQ_CSO 1;
BA_ "FlexKomSigStartValue" SG_ 949 VC_BU_LDW_TRQ_CSO "0300000000000000h";
BA_ "FlexKomSID" SG_ 949 VC_BU_LDW_TRQ_CSO 2008;
BA_ "FlexKomSigStartPos" SG_ 949 VC_BU_LDW_TRQ_CSO 7;
BA_ "FlexKomSigLaenge" SG_ 949 VC_BU_LDW_TRQ_CSO 64;
BA_ "FlexKomSigName" SG_ 949 VC_BU_LDW_TRQ_CSO "VehCfgCSM1_BuPkt";
BA_ "FlexKomComment" SG_ 949 VC_BU_LDW_TRQ_CSO "Backup for veh config - customer settings menu 1 P";
BA_ "FlexKomIsMotorola" SG_ 949 VC_BU_LDW_TRQ_CSO 1;
BA_ "GenSigSNA" SG_ 949 VC_BU_LDW_TRQ_CSO "0h";
BA_ "GenSigSendType" SG_ 949 VC_BU_LDW_WRN_CSO 1;
BA_ "FlexKomSigStartValue" SG_ 949 VC_BU_LDW_WRN_CSO "0300000000000000h";
BA_ "FlexKomSID" SG_ 949 VC_BU_LDW_WRN_CSO 2008;
BA_ "FlexKomSigStartPos" SG_ 949 VC_BU_LDW_WRN_CSO 7;
BA_ "FlexKomSigLaenge" SG_ 949 VC_BU_LDW_WRN_CSO 64;
BA_ "FlexKomSigName" SG_ 949 VC_BU_LDW_WRN_CSO "VehCfgCSM1_BuPkt";
BA_ "FlexKomComment" SG_ 949 VC_BU_LDW_WRN_CSO "Backup for veh config - customer settings menu 1 P";
BA_ "FlexKomIsMotorola" SG_ 949 VC_BU_LDW_WRN_CSO 1;
BA_ "GenSigSNA" SG_ 949 VC_BU_LDW_WRN_CSO "0h";
BA_ "GenSigSendType" SG_ 949 VC_BU_LGHT_RMT_LWR_CSO 1;
BA_ "FlexKomSigStartValue" SG_ 949 VC_BU_LGHT_RMT_LWR_CSO "0300000000000000h";
BA_ "FlexKomSID" SG_ 949 VC_BU_LGHT_RMT_LWR_CSO 2008;
BA_ "FlexKomSigStartPos" SG_ 949 VC_BU_LGHT_RMT_LWR_CSO 7;
BA_ "FlexKomSigLaenge" SG_ 949 VC_BU_LGHT_RMT_LWR_CSO 64;
BA_ "FlexKomSigName" SG_ 949 VC_BU_LGHT_RMT_LWR_CSO "VehCfgCSM1_BuPkt";
BA_ "FlexKomComment" SG_ 949 VC_BU_LGHT_RMT_LWR_CSO "Backup for veh config - customer settings menu 1 P";
BA_ "FlexKomIsMotorola" SG_ 949 VC_BU_LGHT_RMT_LWR_CSO 1;
BA_ "GenSigSNA" SG_ 949 VC_BU_LGHT_RMT_LWR_CSO "0h";
BA_ "GenSigSendType" SG_ 949 VC_BU_NAV_TRN_CSO 1;
BA_ "FlexKomSigStartValue" SG_ 949 VC_BU_NAV_TRN_CSO "0300000000000000h";
BA_ "FlexKomSID" SG_ 949 VC_BU_NAV_TRN_CSO 2008;
BA_ "FlexKomSigStartPos" SG_ 949 VC_BU_NAV_TRN_CSO 7;
BA_ "FlexKomSigLaenge" SG_ 949 VC_BU_NAV_TRN_CSO 64;
BA_ "FlexKomSigName" SG_ 949 VC_BU_NAV_TRN_CSO "VehCfgCSM1_BuPkt";
BA_ "FlexKomComment" SG_ 949 VC_BU_NAV_TRN_CSO "Backup for veh config - customer settings menu 1 P";
BA_ "FlexKomIsMotorola" SG_ 949 VC_BU_NAV_TRN_CSO 1;
BA_ "GenSigSNA" SG_ 949 VC_BU_NAV_TRN_CSO "0h";
BA_ "GenSigSendType" SG_ 949 VC_BU_PE_CSO 1;
BA_ "FlexKomSigStartValue" SG_ 949 VC_BU_PE_CSO "0300000000000000h";
BA_ "FlexKomSID" SG_ 949 VC_BU_PE_CSO 2008;
BA_ "FlexKomSigStartPos" SG_ 949 VC_BU_PE_CSO 7;
BA_ "FlexKomSigLaenge" SG_ 949 VC_BU_PE_CSO 64;
BA_ "FlexKomSigName" SG_ 949 VC_BU_PE_CSO "VehCfgCSM1_BuPkt";
BA_ "FlexKomComment" SG_ 949 VC_BU_PE_CSO "Backup for veh config - customer settings menu 1 P";
BA_ "FlexKomIsMotorola" SG_ 949 VC_BU_PE_CSO 1;
BA_ "GenSigSNA" SG_ 949 VC_BU_PE_CSO "0h";
BA_ "GenSigSendType" SG_ 949 VC_BU_PER_SHFT_ENBL_CSO 1;
BA_ "FlexKomSigStartValue" SG_ 949 VC_BU_PER_SHFT_ENBL_CSO "0300000000000000h";
BA_ "FlexKomSID" SG_ 949 VC_BU_PER_SHFT_ENBL_CSO 2008;
BA_ "FlexKomSigStartPos" SG_ 949 VC_BU_PER_SHFT_ENBL_CSO 7;
BA_ "FlexKomSigLaenge" SG_ 949 VC_BU_PER_SHFT_ENBL_CSO 64;
BA_ "FlexKomSigName" SG_ 949 VC_BU_PER_SHFT_ENBL_CSO "VehCfgCSM1_BuPkt";
BA_ "FlexKomComment" SG_ 949 VC_BU_PER_SHFT_ENBL_CSO "Backup for veh config - customer settings menu 1 P";
BA_ "FlexKomIsMotorola" SG_ 949 VC_BU_PER_SHFT_ENBL_CSO 1;
BA_ "GenSigSNA" SG_ 949 VC_BU_PER_SHFT_ENBL_CSO "0h";
BA_ "GenSigSendType" SG_ 949 VC_BU_PER_SHFT_RPM_CSO 1;
BA_ "FlexKomSigStartValue" SG_ 949 VC_BU_PER_SHFT_RPM_CSO "0300000000000000h";
BA_ "FlexKomSID" SG_ 949 VC_BU_PER_SHFT_RPM_CSO 2008;
BA_ "FlexKomSigStartPos" SG_ 949 VC_BU_PER_SHFT_RPM_CSO 7;
BA_ "FlexKomSigLaenge" SG_ 949 VC_BU_PER_SHFT_RPM_CSO 64;
BA_ "FlexKomSigName" SG_ 949 VC_BU_PER_SHFT_RPM_CSO "VehCfgCSM1_BuPkt";
BA_ "FlexKomComment" SG_ 949 VC_BU_PER_SHFT_RPM_CSO "Backup for veh config - customer settings menu 1 P";
BA_ "FlexKomIsMotorola" SG_ 949 VC_BU_PER_SHFT_RPM_CSO 1;
BA_ "GenSigSNA" SG_ 949 VC_BU_PER_SHFT_RPM_CSO "0h";
BA_ "GenSigSendType" SG_ 949 VC_BU_PLG_CHM_CSO 1;
BA_ "FlexKomSigStartValue" SG_ 949 VC_BU_PLG_CHM_CSO "0300000000000000h";
BA_ "FlexKomSID" SG_ 949 VC_BU_PLG_CHM_CSO 2008;
BA_ "FlexKomSigStartPos" SG_ 949 VC_BU_PLG_CHM_CSO 7;
BA_ "FlexKomSigLaenge" SG_ 949 VC_BU_PLG_CHM_CSO 64;
BA_ "FlexKomSigName" SG_ 949 VC_BU_PLG_CHM_CSO "VehCfgCSM1_BuPkt";
BA_ "FlexKomComment" SG_ 949 VC_BU_PLG_CHM_CSO "Backup for veh config - customer settings menu 1 P";
BA_ "FlexKomIsMotorola" SG_ 949 VC_BU_PLG_CHM_CSO 1;
BA_ "GenSigSNA" SG_ 949 VC_BU_PLG_CHM_CSO "0h";
BA_ "GenSigSendType" SG_ 949 VC_BU_POWER_CSO 1;
BA_ "FlexKomSigStartValue" SG_ 949 VC_BU_POWER_CSO "0300000000000000h";
BA_ "FlexKomSID" SG_ 949 VC_BU_POWER_CSO 2008;
BA_ "FlexKomSigStartPos" SG_ 949 VC_BU_POWER_CSO 7;
BA_ "FlexKomSigLaenge" SG_ 949 VC_BU_POWER_CSO 64;
BA_ "FlexKomSigName" SG_ 949 VC_BU_POWER_CSO "VehCfgCSM1_BuPkt";
BA_ "FlexKomComment" SG_ 949 VC_BU_POWER_CSO "Backup for veh config - customer settings menu 1 P";
BA_ "FlexKomIsMotorola" SG_ 949 VC_BU_POWER_CSO 1;
BA_ "GenSigSNA" SG_ 949 VC_BU_POWER_CSO "0h";
BA_ "GenSigSendType" SG_ 949 VC_BU_PRESSURE_CSO 1;
BA_ "FlexKomSigStartValue" SG_ 949 VC_BU_PRESSURE_CSO "0300000000000000h";
BA_ "FlexKomSID" SG_ 949 VC_BU_PRESSURE_CSO 2008;
BA_ "FlexKomSigStartPos" SG_ 949 VC_BU_PRESSURE_CSO 7;
BA_ "FlexKomSigLaenge" SG_ 949 VC_BU_PRESSURE_CSO 64;
BA_ "FlexKomSigName" SG_ 949 VC_BU_PRESSURE_CSO "VehCfgCSM1_BuPkt";
BA_ "FlexKomComment" SG_ 949 VC_BU_PRESSURE_CSO "Backup for veh config - customer settings menu 1 P";
BA_ "FlexKomIsMotorola" SG_ 949 VC_BU_PRESSURE_CSO 1;
BA_ "GenSigSNA" SG_ 949 VC_BU_PRESSURE_CSO "0h";
BA_ "GenSigSendType" SG_ 949 VC_BU_PTO_CSO 1;
BA_ "FlexKomSigStartValue" SG_ 949 VC_BU_PTO_CSO "0300000000000000h";
BA_ "FlexKomSID" SG_ 949 VC_BU_PTO_CSO 2008;
BA_ "FlexKomSigStartPos" SG_ 949 VC_BU_PTO_CSO 7;
BA_ "FlexKomSigLaenge" SG_ 949 VC_BU_PTO_CSO 64;
BA_ "FlexKomSigName" SG_ 949 VC_BU_PTO_CSO "VehCfgCSM1_BuPkt";
BA_ "FlexKomComment" SG_ 949 VC_BU_PTO_CSO "Backup for veh config - customer settings menu 1 P";
BA_ "FlexKomIsMotorola" SG_ 949 VC_BU_PTO_CSO 1;
BA_ "GenSigSNA" SG_ 949 VC_BU_PTO_CSO "0h";
BA_ "GenSigSendType" SG_ 949 VC_BU_RAIN_WPR_CSO 1;
BA_ "FlexKomSigStartValue" SG_ 949 VC_BU_RAIN_WPR_CSO "0300000000000000h";
BA_ "FlexKomSID" SG_ 949 VC_BU_RAIN_WPR_CSO 2008;
BA_ "FlexKomSigStartPos" SG_ 949 VC_BU_RAIN_WPR_CSO 7;
BA_ "FlexKomSigLaenge" SG_ 949 VC_BU_RAIN_WPR_CSO 64;
BA_ "FlexKomSigName" SG_ 949 VC_BU_RAIN_WPR_CSO "VehCfgCSM1_BuPkt";
BA_ "FlexKomComment" SG_ 949 VC_BU_RAIN_WPR_CSO "Backup for veh config - customer settings menu 1 P";
BA_ "FlexKomIsMotorola" SG_ 949 VC_BU_RAIN_WPR_CSO 1;
BA_ "GenSigSNA" SG_ 949 VC_BU_RAIN_WPR_CSO "0h";
BA_ "GenSigSendType" SG_ 949 VC_BU_REAR_CMRA_CSO 1;
BA_ "FlexKomSigStartValue" SG_ 949 VC_BU_REAR_CMRA_CSO "0300000000000000h";
BA_ "FlexKomSID" SG_ 949 VC_BU_REAR_CMRA_CSO 2008;
BA_ "FlexKomSigStartPos" SG_ 949 VC_BU_REAR_CMRA_CSO 7;
BA_ "FlexKomSigLaenge" SG_ 949 VC_BU_REAR_CMRA_CSO 64;
BA_ "FlexKomSigName" SG_ 949 VC_BU_REAR_CMRA_CSO "VehCfgCSM1_BuPkt";
BA_ "FlexKomComment" SG_ 949 VC_BU_REAR_CMRA_CSO "Backup for veh config - customer settings menu 1 P";
BA_ "FlexKomIsMotorola" SG_ 949 VC_BU_REAR_CMRA_CSO 1;
BA_ "GenSigSNA" SG_ 949 VC_BU_REAR_CMRA_CSO "0h";
BA_ "GenSigSendType" SG_ 950 VC_BU_VehCfgCSO2_Stat 1;
BA_ "FlexKomSigStartValue" SG_ 950 VC_BU_VehCfgCSO2_Stat "0300000000000000h";
BA_ "GenSigStartValue" SG_ 950 VC_BU_VehCfgCSO2_Stat 3;
BA_ "FlexKomSID" SG_ 950 VC_BU_VehCfgCSO2_Stat 2009;
BA_ "FlexKomSigStartPos" SG_ 950 VC_BU_VehCfgCSO2_Stat 7;
BA_ "FlexKomSigLaenge" SG_ 950 VC_BU_VehCfgCSO2_Stat 64;
BA_ "FlexKomSigName" SG_ 950 VC_BU_VehCfgCSO2_Stat "VehCfgCSM2_BuPkt";
BA_ "FlexKomComment" SG_ 950 VC_BU_VehCfgCSO2_Stat "Backup for veh config - customer settings menu 2 p";
BA_ "FlexKomIsMotorola" SG_ 950 VC_BU_VehCfgCSO2_Stat 1;
BA_ "GenSigSNA" SG_ 950 VC_BU_VehCfgCSO2_Stat "3h";
BA_ "GenSigSendType" SG_ 950 VC_BU_REAR_CMRA_DLY_CSO 1;
BA_ "FlexKomSigStartValue" SG_ 950 VC_BU_REAR_CMRA_DLY_CSO "0300000000000000h";
BA_ "FlexKomSID" SG_ 950 VC_BU_REAR_CMRA_DLY_CSO 2009;
BA_ "FlexKomSigStartPos" SG_ 950 VC_BU_REAR_CMRA_DLY_CSO 7;
BA_ "FlexKomSigLaenge" SG_ 950 VC_BU_REAR_CMRA_DLY_CSO 64;
BA_ "FlexKomSigName" SG_ 950 VC_BU_REAR_CMRA_DLY_CSO "VehCfgCSM2_BuPkt";
BA_ "FlexKomComment" SG_ 950 VC_BU_REAR_CMRA_DLY_CSO "Backup for veh config - customer settings menu 2 p";
BA_ "FlexKomIsMotorola" SG_ 950 VC_BU_REAR_CMRA_DLY_CSO 1;
BA_ "GenSigSNA" SG_ 950 VC_BU_REAR_CMRA_DLY_CSO "0h";
BA_ "GenSigSendType" SG_ 950 VC_BU_RKE_MEM_CSO 1;
BA_ "FlexKomSigStartValue" SG_ 950 VC_BU_RKE_MEM_CSO "0300000000000000h";
BA_ "FlexKomSID" SG_ 950 VC_BU_RKE_MEM_CSO 2009;
BA_ "FlexKomSigStartPos" SG_ 950 VC_BU_RKE_MEM_CSO 7;
BA_ "FlexKomSigLaenge" SG_ 950 VC_BU_RKE_MEM_CSO 64;
BA_ "FlexKomSigName" SG_ 950 VC_BU_RKE_MEM_CSO "VehCfgCSM2_BuPkt";
BA_ "FlexKomComment" SG_ 950 VC_BU_RKE_MEM_CSO "Backup for veh config - customer settings menu 2 p";
BA_ "FlexKomIsMotorola" SG_ 950 VC_BU_RKE_MEM_CSO 1;
BA_ "GenSigSNA" SG_ 950 VC_BU_RKE_MEM_CSO "0h";
BA_ "GenSigSendType" SG_ 950 VC_BU_RKE_UNLK_CSO 1;
BA_ "FlexKomSigStartValue" SG_ 950 VC_BU_RKE_UNLK_CSO "0300000000000000h";
BA_ "FlexKomSID" SG_ 950 VC_BU_RKE_UNLK_CSO 2009;
BA_ "FlexKomSigStartPos" SG_ 950 VC_BU_RKE_UNLK_CSO 7;
BA_ "FlexKomSigLaenge" SG_ 950 VC_BU_RKE_UNLK_CSO 64;
BA_ "FlexKomSigName" SG_ 950 VC_BU_RKE_UNLK_CSO "VehCfgCSM2_BuPkt";
BA_ "FlexKomComment" SG_ 950 VC_BU_RKE_UNLK_CSO "Backup for veh config - customer settings menu 2 p";
BA_ "FlexKomIsMotorola" SG_ 950 VC_BU_RKE_UNLK_CSO 1;
BA_ "GenSigSNA" SG_ 950 VC_BU_RKE_UNLK_CSO "0h";
BA_ "GenSigSendType" SG_ 950 VC_BU_SPEED_CSO 1;
BA_ "FlexKomSigStartValue" SG_ 950 VC_BU_SPEED_CSO "0300000000000000h";
BA_ "FlexKomSID" SG_ 950 VC_BU_SPEED_CSO 2009;
BA_ "FlexKomSigStartPos" SG_ 950 VC_BU_SPEED_CSO 7;
BA_ "FlexKomSigLaenge" SG_ 950 VC_BU_SPEED_CSO 64;
BA_ "FlexKomSigName" SG_ 950 VC_BU_SPEED_CSO "VehCfgCSM2_BuPkt";
BA_ "FlexKomComment" SG_ 950 VC_BU_SPEED_CSO "Backup for veh config - customer settings menu 2 p";
BA_ "FlexKomIsMotorola" SG_ 950 VC_BU_SPEED_CSO 1;
BA_ "GenSigSNA" SG_ 950 VC_BU_SPEED_CSO "0h";
BA_ "GenSigSendType" SG_ 950 VC_BU_TLT_MRR_CSO 1;
BA_ "FlexKomSigStartValue" SG_ 950 VC_BU_TLT_MRR_CSO "0300000000000000h";
BA_ "FlexKomSID" SG_ 950 VC_BU_TLT_MRR_CSO 2009;
BA_ "FlexKomSigStartPos" SG_ 950 VC_BU_TLT_MRR_CSO 7;
BA_ "FlexKomSigLaenge" SG_ 950 VC_BU_TLT_MRR_CSO 64;
BA_ "FlexKomSigName" SG_ 950 VC_BU_TLT_MRR_CSO "VehCfgCSM2_BuPkt";
BA_ "FlexKomComment" SG_ 950 VC_BU_TLT_MRR_CSO "Backup for veh config - customer settings menu 2 p";
BA_ "FlexKomIsMotorola" SG_ 950 VC_BU_TLT_MRR_CSO 1;
BA_ "GenSigSNA" SG_ 950 VC_BU_TLT_MRR_CSO "0h";
BA_ "GenSigSendType" SG_ 950 VC_BU_TORQUE_CSO 1;
BA_ "FlexKomSigStartValue" SG_ 950 VC_BU_TORQUE_CSO "0300000000000000h";
BA_ "FlexKomSID" SG_ 950 VC_BU_TORQUE_CSO 2009;
BA_ "FlexKomSigStartPos" SG_ 950 VC_BU_TORQUE_CSO 7;
BA_ "FlexKomSigLaenge" SG_ 950 VC_BU_TORQUE_CSO 64;
BA_ "FlexKomSigName" SG_ 950 VC_BU_TORQUE_CSO "VehCfgCSM2_BuPkt";
BA_ "FlexKomComment" SG_ 950 VC_BU_TORQUE_CSO "Backup for veh config - customer settings menu 2 p";
BA_ "FlexKomIsMotorola" SG_ 950 VC_BU_TORQUE_CSO 1;
BA_ "GenSigSNA" SG_ 950 VC_BU_TORQUE_CSO "0h";
BA_ "GenSigSendType" SG_ 950 VC_BU_TRLR_CSO 1;
BA_ "FlexKomSigStartValue" SG_ 950 VC_BU_TRLR_CSO "0300000000000000h";
BA_ "FlexKomSID" SG_ 950 VC_BU_TRLR_CSO 2009;
BA_ "FlexKomSigStartPos" SG_ 950 VC_BU_TRLR_CSO 7;
BA_ "FlexKomSigLaenge" SG_ 950 VC_BU_TRLR_CSO 64;
BA_ "FlexKomSigName" SG_ 950 VC_BU_TRLR_CSO "VehCfgCSM2_BuPkt";
BA_ "FlexKomComment" SG_ 950 VC_BU_TRLR_CSO "Backup for veh config - customer settings menu 2 p";
BA_ "FlexKomIsMotorola" SG_ 950 VC_BU_TRLR_CSO 1;
BA_ "GenSigSNA" SG_ 950 VC_BU_TRLR_CSO "0h";
BA_ "GenSigSendType" SG_ 950 VC_BU_TRLR_NAME_CSO 1;
BA_ "FlexKomSigStartValue" SG_ 950 VC_BU_TRLR_NAME_CSO "0300000000000000h";
BA_ "FlexKomSID" SG_ 950 VC_BU_TRLR_NAME_CSO 2009;
BA_ "FlexKomSigStartPos" SG_ 950 VC_BU_TRLR_NAME_CSO 7;
BA_ "FlexKomSigLaenge" SG_ 950 VC_BU_TRLR_NAME_CSO 64;
BA_ "FlexKomSigName" SG_ 950 VC_BU_TRLR_NAME_CSO "VehCfgCSM2_BuPkt";
BA_ "FlexKomComment" SG_ 950 VC_BU_TRLR_NAME_CSO "Backup for veh config - customer settings menu 2 p";
BA_ "FlexKomIsMotorola" SG_ 950 VC_BU_TRLR_NAME_CSO 1;
BA_ "GenSigSNA" SG_ 950 VC_BU_TRLR_NAME_CSO "0h";
BA_ "GenSigSendType" SG_ 950 VC_BU_TRLR_TYPE_CSO 1;
BA_ "FlexKomSigStartValue" SG_ 950 VC_BU_TRLR_TYPE_CSO "0300000000000000h";
BA_ "FlexKomSID" SG_ 950 VC_BU_TRLR_TYPE_CSO 2009;
BA_ "FlexKomSigStartPos" SG_ 950 VC_BU_TRLR_TYPE_CSO 7;
BA_ "FlexKomSigLaenge" SG_ 950 VC_BU_TRLR_TYPE_CSO 64;
BA_ "FlexKomSigName" SG_ 950 VC_BU_TRLR_TYPE_CSO "VehCfgCSM2_BuPkt";
BA_ "FlexKomComment" SG_ 950 VC_BU_TRLR_TYPE_CSO "Backup for veh config - customer settings menu 2 p";
BA_ "FlexKomIsMotorola" SG_ 950 VC_BU_TRLR_TYPE_CSO 1;
BA_ "GenSigSNA" SG_ 950 VC_BU_TRLR_TYPE_CSO "0h";
BA_ "GenSigSendType" SG_ 950 VC_BU_TRNS_MD_CSO 1;
BA_ "FlexKomSigStartValue" SG_ 950 VC_BU_TRNS_MD_CSO "0300000000000000h";
BA_ "FlexKomSID" SG_ 950 VC_BU_TRNS_MD_CSO 2009;
BA_ "FlexKomSigStartPos" SG_ 950 VC_BU_TRNS_MD_CSO 7;
BA_ "FlexKomSigLaenge" SG_ 950 VC_BU_TRNS_MD_CSO 64;
BA_ "FlexKomSigName" SG_ 950 VC_BU_TRNS_MD_CSO "VehCfgCSM2_BuPkt";
BA_ "FlexKomComment" SG_ 950 VC_BU_TRNS_MD_CSO "Backup for veh config - customer settings menu 2 p";
BA_ "FlexKomIsMotorola" SG_ 950 VC_BU_TRNS_MD_CSO 1;
BA_ "GenSigSNA" SG_ 950 VC_BU_TRNS_MD_CSO "0h";
BA_ "GenSigSendType" SG_ 950 VC_BU_US_METRIC_CSO 1;
BA_ "FlexKomSigStartValue" SG_ 950 VC_BU_US_METRIC_CSO "0300000000000000h";
BA_ "FlexKomSID" SG_ 950 VC_BU_US_METRIC_CSO 2009;
BA_ "FlexKomSigStartPos" SG_ 950 VC_BU_US_METRIC_CSO 7;
BA_ "FlexKomSigLaenge" SG_ 950 VC_BU_US_METRIC_CSO 64;
BA_ "FlexKomSigName" SG_ 950 VC_BU_US_METRIC_CSO "VehCfgCSM2_BuPkt";
BA_ "FlexKomComment" SG_ 950 VC_BU_US_METRIC_CSO "Backup for veh config - customer settings menu 2 p";
BA_ "FlexKomIsMotorola" SG_ 950 VC_BU_US_METRIC_CSO 1;
BA_ "GenSigSNA" SG_ 950 VC_BU_US_METRIC_CSO "0h";
BA_ "GenSigSendType" SG_ 950 VC_BU_WHL_ALGN_CSO 1;
BA_ "FlexKomSigStartValue" SG_ 950 VC_BU_WHL_ALGN_CSO "0300000000000000h";
BA_ "FlexKomSID" SG_ 950 VC_BU_WHL_ALGN_CSO 2009;
BA_ "FlexKomSigStartPos" SG_ 950 VC_BU_WHL_ALGN_CSO 7;
BA_ "FlexKomSigLaenge" SG_ 950 VC_BU_WHL_ALGN_CSO 64;
BA_ "FlexKomSigName" SG_ 950 VC_BU_WHL_ALGN_CSO "VehCfgCSM2_BuPkt";
BA_ "FlexKomComment" SG_ 950 VC_BU_WHL_ALGN_CSO "Backup for veh config - customer settings menu 2 p";
BA_ "FlexKomIsMotorola" SG_ 950 VC_BU_WHL_ALGN_CSO 1;
BA_ "GenSigSNA" SG_ 950 VC_BU_WHL_ALGN_CSO "0h";
BA_ "GenSigSendType" SG_ 950 VC_BU_FUEL_SAV_CSO 1;
BA_ "FlexKomSigStartValue" SG_ 950 VC_BU_FUEL_SAV_CSO "0300000000000000h";
BA_ "FlexKomSID" SG_ 950 VC_BU_FUEL_SAV_CSO 2009;
BA_ "FlexKomSigStartPos" SG_ 950 VC_BU_FUEL_SAV_CSO 7;
BA_ "FlexKomSigLaenge" SG_ 950 VC_BU_FUEL_SAV_CSO 64;
BA_ "FlexKomSigName" SG_ 950 VC_BU_FUEL_SAV_CSO "VehCfgCSM2_BuPkt";
BA_ "FlexKomComment" SG_ 950 VC_BU_FUEL_SAV_CSO "Backup for veh config - customer settings menu 2 p";
BA_ "FlexKomIsMotorola" SG_ 950 VC_BU_FUEL_SAV_CSO 1;
BA_ "GenSigSNA" SG_ 950 VC_BU_FUEL_SAV_CSO "0h";
BA_ "GenSigSendType" SG_ 950 VC_BU_TEMP_CSO 1;
BA_ "FlexKomSigStartValue" SG_ 950 VC_BU_TEMP_CSO "0300000000000000h";
BA_ "FlexKomSID" SG_ 950 VC_BU_TEMP_CSO 2009;
BA_ "FlexKomSigStartPos" SG_ 950 VC_BU_TEMP_CSO 7;
BA_ "FlexKomSigLaenge" SG_ 950 VC_BU_TEMP_CSO 64;
BA_ "FlexKomSigName" SG_ 950 VC_BU_TEMP_CSO "VehCfgCSM2_BuPkt";
BA_ "FlexKomComment" SG_ 950 VC_BU_TEMP_CSO "Backup for veh config - customer settings menu 2 p";
BA_ "FlexKomIsMotorola" SG_ 950 VC_BU_TEMP_CSO 1;
BA_ "GenSigSNA" SG_ 950 VC_BU_TEMP_CSO "0h";
BA_ "GenSigSendType" SG_ 956 NAV_GrpNum 5;
BA_ "GenSigCycleTime" SG_ 956 NAV_GrpNum 1000;
BA_ "FlexKomSigStartValue" SG_ 956 NAV_GrpNum "0000000000000000h";
BA_ "FlexKomSID" SG_ 956 NAV_GrpNum 576;
BA_ "FlexKomSigStartPos" SG_ 956 NAV_GrpNum 7;
BA_ "FlexKomSigLaenge" SG_ 956 NAV_GrpNum 64;
BA_ "FlexKomSigName" SG_ 956 NAV_GrpNum "NAV_DATA";
BA_ "FlexKomComment" SG_ 956 NAV_GrpNum "Text data packet transfer from NAV";
BA_ "FlexKomIsMotorola" SG_ 956 NAV_GrpNum 1;
BA_ "GenSigSNA" SG_ 956 NAV_GrpNum "0h";
BA_ "GenSigSendType" SG_ 956 NAV_GrpTyp 5;
BA_ "GenSigCycleTime" SG_ 956 NAV_GrpTyp 1000;
BA_ "FlexKomSigStartValue" SG_ 956 NAV_GrpTyp "0000000000000000h";
BA_ "FlexKomSID" SG_ 956 NAV_GrpTyp 576;
BA_ "FlexKomSigStartPos" SG_ 956 NAV_GrpTyp 7;
BA_ "FlexKomSigLaenge" SG_ 956 NAV_GrpTyp 64;
BA_ "FlexKomSigName" SG_ 956 NAV_GrpTyp "NAV_DATA";
BA_ "FlexKomComment" SG_ 956 NAV_GrpTyp "Text data packet transfer from NAV";
BA_ "FlexKomIsMotorola" SG_ 956 NAV_GrpTyp 1;
BA_ "GenSigSNA" SG_ 956 NAV_GrpTyp "3Fh";
BA_ "GenSigSendType" SG_ 956 NAV_HiGrpMark 5;
BA_ "GenSigCycleTime" SG_ 956 NAV_HiGrpMark 1000;
BA_ "FlexKomSigStartValue" SG_ 956 NAV_HiGrpMark "0000000000000000h";
BA_ "FlexKomSID" SG_ 956 NAV_HiGrpMark 576;
BA_ "FlexKomSigStartPos" SG_ 956 NAV_HiGrpMark 7;
BA_ "FlexKomSigLaenge" SG_ 956 NAV_HiGrpMark 64;
BA_ "FlexKomSigName" SG_ 956 NAV_HiGrpMark "NAV_DATA";
BA_ "FlexKomComment" SG_ 956 NAV_HiGrpMark "Text data packet transfer from NAV";
BA_ "FlexKomIsMotorola" SG_ 956 NAV_HiGrpMark 1;
BA_ "GenSigSNA" SG_ 956 NAV_HiGrpMark "0h";
BA_ "GenSigSendType" SG_ 956 NAV_TEXT 5;
BA_ "GenSigCycleTime" SG_ 956 NAV_TEXT 1000;
BA_ "FlexKomSigStartValue" SG_ 956 NAV_TEXT "0000000000000000h";
BA_ "FlexKomSID" SG_ 956 NAV_TEXT 576;
BA_ "FlexKomSigStartPos" SG_ 956 NAV_TEXT 7;
BA_ "FlexKomSigLaenge" SG_ 956 NAV_TEXT 64;
BA_ "FlexKomSigName" SG_ 956 NAV_TEXT "NAV_DATA";
BA_ "FlexKomComment" SG_ 956 NAV_TEXT "Text data packet transfer from NAV";
BA_ "FlexKomIsMotorola" SG_ 956 NAV_TEXT 1;
BA_ "GenSigSNA" SG_ 956 NAV_TEXT "0h";
BA_ "GenSigSendType" SG_ 964 CODE_CTGY 1;
BA_ "FlexKomSigStartValue" SG_ 964 CODE_CTGY "0000h";
BA_ "FlexKomSID" SG_ 964 CODE_CTGY 763;
BA_ "FlexKomSigStartPos" SG_ 964 CODE_CTGY 7;
BA_ "FlexKomSigLaenge" SG_ 964 CODE_CTGY 16;
BA_ "FlexKomSigName" SG_ 964 CODE_CTGY "FLS_CODE";
BA_ "FlexKomComment" SG_ 964 CODE_CTGY "Flash code packet";
BA_ "FlexKomIsMotorola" SG_ 964 CODE_CTGY 1;
BA_ "GenSigSNA" SG_ 964 CODE_CTGY "0h";
BA_ "GenSigSendType" SG_ 964 CODE_1CHAR 1;
BA_ "FlexKomSigStartValue" SG_ 964 CODE_1CHAR "0000h";
BA_ "FlexKomSID" SG_ 964 CODE_1CHAR 763;
BA_ "FlexKomSigStartPos" SG_ 964 CODE_1CHAR 7;
BA_ "FlexKomSigLaenge" SG_ 964 CODE_1CHAR 16;
BA_ "FlexKomSigName" SG_ 964 CODE_1CHAR "FLS_CODE";
BA_ "FlexKomComment" SG_ 964 CODE_1CHAR "Flash code packet";
BA_ "FlexKomIsMotorola" SG_ 964 CODE_1CHAR 1;
BA_ "GenSigSNA" SG_ 964 CODE_1CHAR "0h";
BA_ "GenSigSendType" SG_ 964 CODE_2CHAR 1;
BA_ "FlexKomSigStartValue" SG_ 964 CODE_2CHAR "0000h";
BA_ "FlexKomSID" SG_ 964 CODE_2CHAR 763;
BA_ "FlexKomSigStartPos" SG_ 964 CODE_2CHAR 7;
BA_ "FlexKomSigLaenge" SG_ 964 CODE_2CHAR 16;
BA_ "FlexKomSigName" SG_ 964 CODE_2CHAR "FLS_CODE";
BA_ "FlexKomComment" SG_ 964 CODE_2CHAR "Flash code packet";
BA_ "FlexKomIsMotorola" SG_ 964 CODE_2CHAR 1;
BA_ "GenSigSNA" SG_ 964 CODE_2CHAR "0h";
BA_ "GenSigSendType" SG_ 964 CODE_3CHAR 1;
BA_ "FlexKomSigStartValue" SG_ 964 CODE_3CHAR "0000h";
BA_ "FlexKomSID" SG_ 964 CODE_3CHAR 763;
BA_ "FlexKomSigStartPos" SG_ 964 CODE_3CHAR 7;
BA_ "FlexKomSigLaenge" SG_ 964 CODE_3CHAR 16;
BA_ "FlexKomSigName" SG_ 964 CODE_3CHAR "FLS_CODE";
BA_ "FlexKomComment" SG_ 964 CODE_3CHAR "Flash code packet";
BA_ "FlexKomIsMotorola" SG_ 964 CODE_3CHAR 1;
BA_ "GenSigSNA" SG_ 964 CODE_3CHAR "0h";
BA_ "GenSigSendType" SG_ 964 CODE_4CHAR 1;
BA_ "FlexKomSigStartValue" SG_ 964 CODE_4CHAR "0000h";
BA_ "FlexKomSID" SG_ 964 CODE_4CHAR 763;
BA_ "FlexKomSigStartPos" SG_ 964 CODE_4CHAR 7;
BA_ "FlexKomSigLaenge" SG_ 964 CODE_4CHAR 16;
BA_ "FlexKomSigName" SG_ 964 CODE_4CHAR "FLS_CODE";
BA_ "FlexKomComment" SG_ 964 CODE_4CHAR "Flash code packet";
BA_ "FlexKomIsMotorola" SG_ 964 CODE_4CHAR 1;
BA_ "GenSigSNA" SG_ 964 CODE_4CHAR "0h";
BA_ "GenSigSendType" SG_ 968 VinChar10_IC 9;
BA_ "GenSigCycleTime" SG_ 968 VinChar10_IC 100;
BA_ "FlexKomSigStartValue" SG_ 968 VinChar10_IC "0000000000000000h";
BA_ "FlexKomSID" SG_ 968 VinChar10_IC 1316;
BA_ "FlexKomSigStartPos" SG_ 968 VinChar10_IC 7;
BA_ "FlexKomSigLaenge" SG_ 968 VinChar10_IC 64;
BA_ "FlexKomSigName" SG_ 968 VinChar10_IC "ImmHsPkt_IC";
BA_ "FlexKomComment" SG_ 968 VinChar10_IC "Immobilizer handshake packet from IC";
BA_ "FlexKomIsMotorola" SG_ 968 VinChar10_IC 1;
BA_ "GenSigSNA" SG_ 968 VinChar10_IC "FFh";
BA_ "GenSigSendType" SG_ 968 VinChar11_IC 9;
BA_ "GenSigCycleTime" SG_ 968 VinChar11_IC 100;
BA_ "FlexKomSigStartValue" SG_ 968 VinChar11_IC "0000000000000000h";
BA_ "FlexKomSID" SG_ 968 VinChar11_IC 1316;
BA_ "FlexKomSigStartPos" SG_ 968 VinChar11_IC 7;
BA_ "FlexKomSigLaenge" SG_ 968 VinChar11_IC 64;
BA_ "FlexKomSigName" SG_ 968 VinChar11_IC "ImmHsPkt_IC";
BA_ "FlexKomComment" SG_ 968 VinChar11_IC "Immobilizer handshake packet from IC";
BA_ "FlexKomIsMotorola" SG_ 968 VinChar11_IC 1;
BA_ "GenSigSNA" SG_ 968 VinChar11_IC "FFh";
BA_ "GenSigSendType" SG_ 968 VinChar12_IC 9;
BA_ "GenSigCycleTime" SG_ 968 VinChar12_IC 100;
BA_ "FlexKomSigStartValue" SG_ 968 VinChar12_IC "0000000000000000h";
BA_ "FlexKomSID" SG_ 968 VinChar12_IC 1316;
BA_ "FlexKomSigStartPos" SG_ 968 VinChar12_IC 7;
BA_ "FlexKomSigLaenge" SG_ 968 VinChar12_IC 64;
BA_ "FlexKomSigName" SG_ 968 VinChar12_IC "ImmHsPkt_IC";
BA_ "FlexKomComment" SG_ 968 VinChar12_IC "Immobilizer handshake packet from IC";
BA_ "FlexKomIsMotorola" SG_ 968 VinChar12_IC 1;
BA_ "GenSigSNA" SG_ 968 VinChar12_IC "FFh";
BA_ "GenSigSendType" SG_ 968 VinChar13_IC 9;
BA_ "GenSigCycleTime" SG_ 968 VinChar13_IC 100;
BA_ "FlexKomSigStartValue" SG_ 968 VinChar13_IC "0000000000000000h";
BA_ "FlexKomSID" SG_ 968 VinChar13_IC 1316;
BA_ "FlexKomSigStartPos" SG_ 968 VinChar13_IC 7;
BA_ "FlexKomSigLaenge" SG_ 968 VinChar13_IC 64;
BA_ "FlexKomSigName" SG_ 968 VinChar13_IC "ImmHsPkt_IC";
BA_ "FlexKomComment" SG_ 968 VinChar13_IC "Immobilizer handshake packet from IC";
BA_ "FlexKomIsMotorola" SG_ 968 VinChar13_IC 1;
BA_ "GenSigSNA" SG_ 968 VinChar13_IC "FFh";
BA_ "GenSigSendType" SG_ 968 VinChar14_IC 9;
BA_ "GenSigCycleTime" SG_ 968 VinChar14_IC 100;
BA_ "FlexKomSigStartValue" SG_ 968 VinChar14_IC "0000000000000000h";
BA_ "FlexKomSID" SG_ 968 VinChar14_IC 1316;
BA_ "FlexKomSigStartPos" SG_ 968 VinChar14_IC 7;
BA_ "FlexKomSigLaenge" SG_ 968 VinChar14_IC 64;
BA_ "FlexKomSigName" SG_ 968 VinChar14_IC "ImmHsPkt_IC";
BA_ "FlexKomComment" SG_ 968 VinChar14_IC "Immobilizer handshake packet from IC";
BA_ "FlexKomIsMotorola" SG_ 968 VinChar14_IC 1;
BA_ "GenSigSNA" SG_ 968 VinChar14_IC "FFh";
BA_ "GenSigSendType" SG_ 968 VinChar15_IC 9;
BA_ "GenSigCycleTime" SG_ 968 VinChar15_IC 100;
BA_ "FlexKomSigStartValue" SG_ 968 VinChar15_IC "0000000000000000h";
BA_ "FlexKomSID" SG_ 968 VinChar15_IC 1316;
BA_ "FlexKomSigStartPos" SG_ 968 VinChar15_IC 7;
BA_ "FlexKomSigLaenge" SG_ 968 VinChar15_IC 64;
BA_ "FlexKomSigName" SG_ 968 VinChar15_IC "ImmHsPkt_IC";
BA_ "FlexKomComment" SG_ 968 VinChar15_IC "Immobilizer handshake packet from IC";
BA_ "FlexKomIsMotorola" SG_ 968 VinChar15_IC 1;
BA_ "GenSigSNA" SG_ 968 VinChar15_IC "FFh";
BA_ "GenSigSendType" SG_ 968 VinChar16_IC 9;
BA_ "GenSigCycleTime" SG_ 968 VinChar16_IC 100;
BA_ "FlexKomSigStartValue" SG_ 968 VinChar16_IC "0000000000000000h";
BA_ "FlexKomSID" SG_ 968 VinChar16_IC 1316;
BA_ "FlexKomSigStartPos" SG_ 968 VinChar16_IC 7;
BA_ "FlexKomSigLaenge" SG_ 968 VinChar16_IC 64;
BA_ "FlexKomSigName" SG_ 968 VinChar16_IC "ImmHsPkt_IC";
BA_ "FlexKomComment" SG_ 968 VinChar16_IC "Immobilizer handshake packet from IC";
BA_ "FlexKomIsMotorola" SG_ 968 VinChar16_IC 1;
BA_ "GenSigSNA" SG_ 968 VinChar16_IC "FFh";
BA_ "GenSigSendType" SG_ 968 VinChar17_IC 9;
BA_ "GenSigCycleTime" SG_ 968 VinChar17_IC 100;
BA_ "FlexKomSigStartValue" SG_ 968 VinChar17_IC "0000000000000000h";
BA_ "FlexKomSID" SG_ 968 VinChar17_IC 1316;
BA_ "FlexKomSigStartPos" SG_ 968 VinChar17_IC 7;
BA_ "FlexKomSigLaenge" SG_ 968 VinChar17_IC 64;
BA_ "FlexKomSigName" SG_ 968 VinChar17_IC "ImmHsPkt_IC";
BA_ "FlexKomComment" SG_ 968 VinChar17_IC "Immobilizer handshake packet from IC";
BA_ "FlexKomIsMotorola" SG_ 968 VinChar17_IC 1;
BA_ "GenSigSNA" SG_ 968 VinChar17_IC "FFh";
BA_ "GenSigCycleTime" SG_ 969 AMB_TEMP_AVG_F 1000;
BA_ "FlexKomSigStartValue" SG_ 969 AMB_TEMP_AVG_F "FFh";
BA_ "GenSigStartValue" SG_ 969 AMB_TEMP_AVG_F 255;
BA_ "GenSigTimeout_IC" SG_ 969 AMB_TEMP_AVG_F 10500;
BA_ "FlexKomSID" SG_ 969 AMB_TEMP_AVG_F 1428;
BA_ "FlexKomSigStartPos" SG_ 969 AMB_TEMP_AVG_F 7;
BA_ "FlexKomSigLaenge" SG_ 969 AMB_TEMP_AVG_F 8;
BA_ "FlexKomSigName" SG_ 969 AMB_TEMP_AVG_F "AMB_TEMP_AVG_F";
BA_ "FlexKomComment" SG_ 969 AMB_TEMP_AVG_F "Ambient temperature average - in degrees Fahrenhei";
BA_ "FlexKomIsMotorola" SG_ 969 AMB_TEMP_AVG_F 1;
BA_ "GenSigSNA" SG_ 969 AMB_TEMP_AVG_F "FFh";
BA_ "GenSigCycleTime" SG_ 969 AMB_TEMP_AVG_C 1000;
BA_ "FlexKomSigStartValue" SG_ 969 AMB_TEMP_AVG_C "FFh";
BA_ "GenSigStartValue" SG_ 969 AMB_TEMP_AVG_C 255;
BA_ "GenSigTimeout_IC" SG_ 969 AMB_TEMP_AVG_C 10500;
BA_ "FlexKomSID" SG_ 969 AMB_TEMP_AVG_C 1427;
BA_ "FlexKomSigStartPos" SG_ 969 AMB_TEMP_AVG_C 15;
BA_ "FlexKomSigLaenge" SG_ 969 AMB_TEMP_AVG_C 8;
BA_ "FlexKomSigName" SG_ 969 AMB_TEMP_AVG_C "AMB_TEMP_AVG_C";
BA_ "FlexKomComment" SG_ 969 AMB_TEMP_AVG_C "Ambient temperature average - in degrees Celsius";
BA_ "FlexKomIsMotorola" SG_ 969 AMB_TEMP_AVG_C 1;
BA_ "GenSigSNA" SG_ 969 AMB_TEMP_AVG_C "FFh";
BA_ "GenSigSendType" SG_ 970 VinChar10_CBC 9;
BA_ "GenSigCycleTime" SG_ 970 VinChar10_CBC 100;
BA_ "FlexKomSigStartValue" SG_ 970 VinChar10_CBC "0000000000000000h";
BA_ "FlexKomSID" SG_ 970 VinChar10_CBC 1317;
BA_ "FlexKomSigStartPos" SG_ 970 VinChar10_CBC 7;
BA_ "FlexKomSigLaenge" SG_ 970 VinChar10_CBC 64;
BA_ "FlexKomSigName" SG_ 970 VinChar10_CBC "ImmHsPkt_CBC";
BA_ "FlexKomComment" SG_ 970 VinChar10_CBC "Immobilizer handshake packet from CBC";
BA_ "FlexKomIsMotorola" SG_ 970 VinChar10_CBC 1;
BA_ "GenSigSNA" SG_ 970 VinChar10_CBC "FFh";
BA_ "GenSigSendType" SG_ 970 VinChar11_CBC 9;
BA_ "GenSigCycleTime" SG_ 970 VinChar11_CBC 100;
BA_ "FlexKomSigStartValue" SG_ 970 VinChar11_CBC "0000000000000000h";
BA_ "FlexKomSID" SG_ 970 VinChar11_CBC 1317;
BA_ "FlexKomSigStartPos" SG_ 970 VinChar11_CBC 7;
BA_ "FlexKomSigLaenge" SG_ 970 VinChar11_CBC 64;
BA_ "FlexKomSigName" SG_ 970 VinChar11_CBC "ImmHsPkt_CBC";
BA_ "FlexKomComment" SG_ 970 VinChar11_CBC "Immobilizer handshake packet from CBC";
BA_ "FlexKomIsMotorola" SG_ 970 VinChar11_CBC 1;
BA_ "GenSigSNA" SG_ 970 VinChar11_CBC "FFh";
BA_ "GenSigSendType" SG_ 970 VinChar12_CBC 9;
BA_ "GenSigCycleTime" SG_ 970 VinChar12_CBC 100;
BA_ "FlexKomSigStartValue" SG_ 970 VinChar12_CBC "0000000000000000h";
BA_ "FlexKomSID" SG_ 970 VinChar12_CBC 1317;
BA_ "FlexKomSigStartPos" SG_ 970 VinChar12_CBC 7;
BA_ "FlexKomSigLaenge" SG_ 970 VinChar12_CBC 64;
BA_ "FlexKomSigName" SG_ 970 VinChar12_CBC "ImmHsPkt_CBC";
BA_ "FlexKomComment" SG_ 970 VinChar12_CBC "Immobilizer handshake packet from CBC";
BA_ "FlexKomIsMotorola" SG_ 970 VinChar12_CBC 1;
BA_ "GenSigSNA" SG_ 970 VinChar12_CBC "FFh";
BA_ "GenSigSendType" SG_ 970 VinChar13_CBC 9;
BA_ "GenSigCycleTime" SG_ 970 VinChar13_CBC 100;
BA_ "FlexKomSigStartValue" SG_ 970 VinChar13_CBC "0000000000000000h";
BA_ "FlexKomSID" SG_ 970 VinChar13_CBC 1317;
BA_ "FlexKomSigStartPos" SG_ 970 VinChar13_CBC 7;
BA_ "FlexKomSigLaenge" SG_ 970 VinChar13_CBC 64;
BA_ "FlexKomSigName" SG_ 970 VinChar13_CBC "ImmHsPkt_CBC";
BA_ "FlexKomComment" SG_ 970 VinChar13_CBC "Immobilizer handshake packet from CBC";
BA_ "FlexKomIsMotorola" SG_ 970 VinChar13_CBC 1;
BA_ "GenSigSNA" SG_ 970 VinChar13_CBC "FFh";
BA_ "GenSigSendType" SG_ 970 VinChar14_CBC 9;
BA_ "GenSigCycleTime" SG_ 970 VinChar14_CBC 100;
BA_ "FlexKomSigStartValue" SG_ 970 VinChar14_CBC "0000000000000000h";
BA_ "FlexKomSID" SG_ 970 VinChar14_CBC 1317;
BA_ "FlexKomSigStartPos" SG_ 970 VinChar14_CBC 7;
BA_ "FlexKomSigLaenge" SG_ 970 VinChar14_CBC 64;
BA_ "FlexKomSigName" SG_ 970 VinChar14_CBC "ImmHsPkt_CBC";
BA_ "FlexKomComment" SG_ 970 VinChar14_CBC "Immobilizer handshake packet from CBC";
BA_ "FlexKomIsMotorola" SG_ 970 VinChar14_CBC 1;
BA_ "GenSigSNA" SG_ 970 VinChar14_CBC "FFh";
BA_ "GenSigSendType" SG_ 970 VinChar15_CBC 9;
BA_ "GenSigCycleTime" SG_ 970 VinChar15_CBC 100;
BA_ "FlexKomSigStartValue" SG_ 970 VinChar15_CBC "0000000000000000h";
BA_ "FlexKomSID" SG_ 970 VinChar15_CBC 1317;
BA_ "FlexKomSigStartPos" SG_ 970 VinChar15_CBC 7;
BA_ "FlexKomSigLaenge" SG_ 970 VinChar15_CBC 64;
BA_ "FlexKomSigName" SG_ 970 VinChar15_CBC "ImmHsPkt_CBC";
BA_ "FlexKomComment" SG_ 970 VinChar15_CBC "Immobilizer handshake packet from CBC";
BA_ "FlexKomIsMotorola" SG_ 970 VinChar15_CBC 1;
BA_ "GenSigSNA" SG_ 970 VinChar15_CBC "FFh";
BA_ "GenSigSendType" SG_ 970 VinChar16_CBC 9;
BA_ "GenSigCycleTime" SG_ 970 VinChar16_CBC 100;
BA_ "FlexKomSigStartValue" SG_ 970 VinChar16_CBC "0000000000000000h";
BA_ "FlexKomSID" SG_ 970 VinChar16_CBC 1317;
BA_ "FlexKomSigStartPos" SG_ 970 VinChar16_CBC 7;
BA_ "FlexKomSigLaenge" SG_ 970 VinChar16_CBC 64;
BA_ "FlexKomSigName" SG_ 970 VinChar16_CBC "ImmHsPkt_CBC";
BA_ "FlexKomComment" SG_ 970 VinChar16_CBC "Immobilizer handshake packet from CBC";
BA_ "FlexKomIsMotorola" SG_ 970 VinChar16_CBC 1;
BA_ "GenSigSNA" SG_ 970 VinChar16_CBC "FFh";
BA_ "GenSigSendType" SG_ 970 VinChar17_CBC 9;
BA_ "GenSigCycleTime" SG_ 970 VinChar17_CBC 100;
BA_ "FlexKomSigStartValue" SG_ 970 VinChar17_CBC "0000000000000000h";
BA_ "FlexKomSID" SG_ 970 VinChar17_CBC 1317;
BA_ "FlexKomSigStartPos" SG_ 970 VinChar17_CBC 7;
BA_ "FlexKomSigLaenge" SG_ 970 VinChar17_CBC 64;
BA_ "FlexKomSigName" SG_ 970 VinChar17_CBC "ImmHsPkt_CBC";
BA_ "FlexKomComment" SG_ 970 VinChar17_CBC "Immobilizer handshake packet from CBC";
BA_ "FlexKomIsMotorola" SG_ 970 VinChar17_CBC 1;
BA_ "GenSigSNA" SG_ 970 VinChar17_CBC "FFh";
VAL_ 903 ITBM_TrlrStat 3 "SNA" 2 "TRLR_DCONN" 1 "TRLR_PRSNT" 0 "NO_TRLR" ;
VAL_ 903 ITBM_BrkStyle 3 "HV_EOH" 2 "LT_EOH" 1 "HV_ELECT" 0 "LT_ELECT" ;
VAL_ 903 ITBM_OP_PWR 255 "SNA" ;
VAL_ 903 ITBM_BRK_SW 3 "SNA" 1 "BRAKE_ON" 0 "BRAKE_OFF" ;
VAL_ 903 ITBM_GAIN_STAT 31 "SNA" ;
VAL_ 903 ITBM_DSP_RQ 15 "SNA" 8 "SAFE" 7 "MANUAL" 6 "TLR_NOT_CONN" 5 "FLT_CONN" 4 "GAIN_ADJ" 3 "FLT_TRLR_DCONN" 2 "FLT_ITBM" 1 "FLT_TRLR_WIRE" 0 "NO_DISP_RQ" ;
VAL_ 914 PTOPressSwStat 3 "SNA" 1 "CLOSED" 0 "OPEN" ;
VAL_ 916 PlowHL_Stat 3 "SNA" 2 "HI" 1 "LOW" 0 "OFF" ;
VAL_ 924 MsgFobBattLow 3 "SNA" 1 "MSG_ACTIVE" 0 "MSG_DEFAULT" ;
VAL_ 924 MsgServPEKG 3 "SNA" 1 "MSG_ACTIVE" 0 "MSG_DEFAULT" ;
VAL_ 924 MsgFobNotFnd 3 "SNA" 1 "MSG_ACTIVE" 0 "MSG_DEFAULT" ;
VAL_ 924 MsgNotInPark 3 "SNA" 1 "MSG_ACTIVE" 0 "MSG_DEFAULT" ;
VAL_ 924 MsgVehMove 3 "SNA" 1 "MSG_ACTIVE" 0 "MSG_DEFAULT" ;
VAL_ 924 MsgIgnOn 3 "SNA" 1 "MSG_ACTIVE" 0 "MSG_DEFAULT" ;
VAL_ 924 MsgKG1 3 "SNA" 1 "MSG_ACTIVE" 0 "MSG_DEFAULT" ;
VAL_ 924 MsgKG2 3 "SNA" 1 "MSG_ACTIVE" 0 "MSG_DEFAULT" ;
VAL_ 924 FOB_SrchRslt 3 "TIMEOUT" 2 "COMPLETE" 1 "SIP" 0 "NO_ACT" ;
VAL_ 937 ILL_APRCH_TIME 255 "SNA" ;
VAL_ 937 HL_DLY_TIME 255 "SNA" ;
VAL_ 937 ACC_DLY_TIME 65535 "SNA" ;
VAL_ 937 SOUND_LK_1ST_2ND 3 "SNA" 2 "SECOND" 1 "FIRST" 0 "OFF" ;
VAL_ 947 VC_VehCfgCSO1_Stat 3 "SNA" 2 "REQUEST_DATA" 1 "PROGAMMED" 0 "NA" ;
VAL_ 947 VC_PRK_AST_CSO 2 "Option_2_3" 1 "Option_1_2" 0 "Absent" ;
VAL_ 947 VC_FCW_CSO 2 "Option_2_3" 1 "Option_1_2" 0 "Absent" ;
VAL_ 947 VC_HRN_RMT_LK_CSO 2 "Option_2_3" 1 "Option_1_2" 0 "Absent" ;
VAL_ 947 VC_DCS_CSO 2 "Option_2_3" 1 "Option_1_2" 0 "Absent" ;
VAL_ 947 VC_AUX_SWS_CSO 2 "SWITCH_2_5" 1 "SWITCH_1_4" 0 "Absent" ;
VAL_ 947 VC_CMRA_GRDLNS_CSO 3 "STATIC_DYNAMIC" 2 "DYNAMIC" 1 "STATIC" 0 "Absent" ;
VAL_ 948 VC_VehCfgCSO2_Stat 3 "SNA" 2 "REQUEST_DATA" 1 "PROGAMMED" 0 "NA" ;
VAL_ 949 VC_BU_VehCfgCSO1_Stat 3 "SNA" 2 "REQUEST_DATA" 1 "PROGAMMED" 0 "NA" ;
VAL_ 949 VC_BU_PRK_AST_CSO 2 "Option_2_3" 1 "Option_1_2" 0 "Absent" ;
VAL_ 949 VC_BU_FCW_CSO 2 "Option_2_3" 1 "Option_1_2" 0 "Absent" ;
VAL_ 949 VC_BU_HRN_RMT_LK_CSO 2 "Option_2_3" 1 "Option_1_2" 0 "Absent" ;
VAL_ 949 VC_BU_DCS_CSO 2 "Option_2_3" 1 "Option_1_2" 0 "Absent" ;
VAL_ 949 VC_BU_AUX_SWS_CSO 2 "SWITCH_2_5" 1 "SWITCH_1_4" 0 "Absent" ;
VAL_ 949 VC_BU_CMRA_GRDLNS_CSO 3 "STATIC_DYNAMIC" 2 "DYNAMIC" 1 "STATIC" 0 "Absent" ;
VAL_ 950 VC_BU_VehCfgCSO2_Stat 3 "SNA" 2 "REQUEST_DATA" 1 "PROGAMMED" 0 "NA" ;
VAL_ 956 NAV_GrpTyp 63 "SNA" 0 "NO_TEXT" ;
VAL_ 964 CODE_CTGY 3 "FLS_U" 2 "FLS_B" 1 "FLS_C" 0 "FLS_P" ;
VAL_ 968 VinChar10_IC 255 "SNA" ;
VAL_ 968 VinChar11_IC 255 "SNA" ;
VAL_ 968 VinChar12_IC 255 "SNA" ;
VAL_ 968 VinChar13_IC 255 "SNA" ;
VAL_ 968 VinChar14_IC 255 "SNA" ;
VAL_ 968 VinChar15_IC 255 "SNA" ;
VAL_ 968 VinChar16_IC 255 "SNA" ;
VAL_ 968 VinChar17_IC 255 "SNA" ;
VAL_ 969 AMB_TEMP_AVG_F 255 "SNA" ;
VAL_ 969 AMB_TEMP_AVG_C 255 "SNA" ;
VAL_ 970 VinChar10_CBC 255 "SNA" ;
VAL_ 970 VinChar11_CBC 255 "SNA" ;
VAL_ 970 VinChar12_CBC 255 "SNA" ;
VAL_ 970 VinChar13_CBC 255 "SNA" ;
VAL_ 970 VinChar14_CBC 255 "SNA" ;
VAL_ 970 VinChar15_CBC 255 "SNA" ;
VAL_ 970 VinChar16_CBC 255 "SNA" ;
VAL_ 970 VinChar17_CBC 255 "SNA" ;
